VERSION ""

NS_ :

BS_:

BU_: ETH

BO_ 738 VCLEFT_seatStatus2: 8 Vector__XXX
 SG_ VCLEFT_seatStatus2Index M : 0|4@1+ (1,0) [0|0] "" Vector__XXX
 SG_ VCLEFT_2RowSeatReclineActuatorCurrent m6 : 4|12@1- (0.01,0) [0|0] "" Vector__XXX
 SG_ VCLEFT_2RowSeatTrackActuatorCurrent m9 : 4|12@1- (0.01,0) [0|0] "" Vector__XXX
 SG_ VCLEFT_frontOccupancyVoltage m2 : 4|8@1+ (0.02,0) [0|0] "" Vector__XXX
 SG_ VCLEFT_frontSeatHeatCurrent m0 : 4|12@1+ (0.01,0) [0|0] "" Vector__XXX
 SG_ VCLEFT_frontSeatTrackBackrestSwitchVoltage m7 : 4|10@1+ (0.01,0) [0|0] "" Vector__XXX
 SG_ VCLEFT_rearCHeatCurrent m4 : 4|12@1+ (0.01,0) [0|0] "" Vector__XXX
 SG_ VCLEFT_rearLBackHeatCurrent m1 : 4|12@1+ (0.01,0) [0|0] "" Vector__XXX
 SG_ VCLEFT_rearLHeatCurrent m3 : 4|12@1+ (0.01,0) [0|0] "" Vector__XXX
 SG_ VCLEFT_rearRCushionHeatCurrent m5 : 4|12@1+ (0.01,0) [0|0] "" Vector__XXX
 SG_ VCLEFT_trunkFoldFlatLeftSwitchVoltage m8 : 4|10@1+ (0.004887585532746823,0) [0|0] "" Vector__XXX
 SG_ VCLEFT_frontBuckleVoltage m2 : 12|8@1+ (0.02,0) [0|0] "" Vector__XXX
 SG_ VCLEFT_frontSeatLumbarSwitchVoltage m7 : 14|10@1+ (0.01,0) [0|0] "" Vector__XXX
 SG_ VCLEFT_trunkFoldFlatRightSwitchVoltage m8 : 14|10@1+ (0.01,0) [0|0] "" Vector__XXX
 SG_ VCLEFT_2RowSeatReclineActuatorDuty m6 : 16|12@1- (0.1,0) [0|0] "" Vector__XXX
 SG_ VCLEFT_2RowSeatTrackActuatorDuty m9 : 16|12@1- (0.1,0) [0|0] "" Vector__XXX
 SG_ VCLEFT_frontSeatHeatDuty m0 : 16|8@1+ (1,0) [0|0] "" Vector__XXX
 SG_ VCLEFT_rearCHeatDuty m4 : 16|8@1+ (1,0) [0|0] "" Vector__XXX
 SG_ VCLEFT_rearLBackHeatDuty m1 : 16|8@1+ (1,0) [0|0] "" Vector__XXX
 SG_ VCLEFT_rearLHeatDuty m3 : 16|8@1+ (1,0) [0|0] "" Vector__XXX
 SG_ VCLEFT_rearRCushionHeatDuty m5 : 16|8@1+ (1,0) [0|0] "" Vector__XXX
 SG_ VCLEFT_rearLeftBuckleVoltage m2 : 20|8@1+ (0.02,0) [0|0] "" Vector__XXX
 SG_ VCLEFT_frontSeatHeatTmp m0 : 24|12@1- (0.05,0) [0|0] "" Vector__XXX
 SG_ VCLEFT_frontSeatLiftTiltSwitchVoltage m7 : 24|10@1+ (0.01,0) [0|0] "" Vector__XXX
 SG_ VCLEFT_rearCHeatTmp m4 : 24|12@1- (0.05,0) [0|0] "" Vector__XXX
 SG_ VCLEFT_rearLBackHeatTmp m1 : 24|12@1- (0.05,0) [0|0] "" Vector__XXX
 SG_ VCLEFT_rearLHeatTmp m3 : 24|12@1- (0.05,0) [0|0] "" Vector__XXX
 SG_ VCLEFT_rearRCushionHeatTmp m5 : 24|12@1- (0.05,0) [0|0] "" Vector__XXX
 SG_ VCLEFT_2RowSeatCenterActuatorCurrent m6 : 28|12@1- (0.01,0) [0|0] "" Vector__XXX
 SG_ VCLEFT_2RowSeatEasyEntryState m9 : 28|3@1+ (1,0) [0|0] "" Vector__XXX
 SG_ VCLEFT_rearLeftOccupancyVoltage m2 : 28|8@1+ (0.02,0) [0|0] "" Vector__XXX
 SG_ VCLEFT_2RowSeatTrackPositionSwitch m9 : 31|2@1+ (1,0) [0|0] "" Vector__XXX
 SG_ VCLEFT_2RowSeatReclineSwitchVoltage m7 : 34|10@1+ (0.01,0) [0|0] "" Vector__XXX
 SG_ VCLEFT_frontSeatHeatTmpTarget m0 : 36|8@1- (0.5,0) [0|0] "" Vector__XXX
 SG_ VCLEFT_rearCHeatTmpTarget m4 : 36|8@1- (0.5,0) [0|0] "" Vector__XXX
 SG_ VCLEFT_rearCenterOccupancyVoltage m2 : 36|8@1+ (0.02,0) [0|0] "" Vector__XXX
 SG_ VCLEFT_rearLBackHeatTmpTarget m1 : 36|8@1- (0.5,0) [0|0] "" Vector__XXX
 SG_ VCLEFT_rearLHeatTmpTarget m3 : 36|8@1- (0.5,0) [0|0] "" Vector__XXX
 SG_ VCLEFT_rearRCushionHeatTmpTarget m5 : 36|8@1- (0.5,0) [0|0] "" Vector__XXX
 SG_ VCLEFT_2RowSeatCenterActuatorDuty m6 : 40|12@1- (0.1,0) [0|0] "" Vector__XXX
 SG_ VCLEFT_2RowSeatEasyEntrySwitchVoltage m7 : 44|10@1+ (0.01,0) [0|0] "" Vector__XXX
 SG_ VCLEFT_frontSeatHeatInhibited m0 : 44|1@1+ (1,0) [0|0] "" Vector__XXX
 SG_ VCLEFT_rearCHeatInhibited m4 : 44|1@1+ (1,0) [0|0] "" Vector__XXX
 SG_ VCLEFT_rearLBackHeatInhibited m1 : 44|1@1+ (1,0) [0|0] "" Vector__XXX
 SG_ VCLEFT_rearLHeatInhibited m3 : 44|1@1+ (1,0) [0|0] "" Vector__XXX
 SG_ VCLEFT_rearRCushionHeatInhibited m5 : 44|1@1+ (1,0) [0|0] "" Vector__XXX
 SG_ VCLEFT_rearRightOccupancyVoltage m2 : 44|8@1+ (0.02,0) [0|0] "" Vector__XXX
 SG_ VCLEFT_frontSeatHeatPowered m0 : 45|1@1+ (1,0) [0|0] "" Vector__XXX
 SG_ VCLEFT_rearCHeatPowered m4 : 45|1@1+ (1,0) [0|0] "" Vector__XXX
 SG_ VCLEFT_rearLBackHeatPowered m1 : 45|1@1+ (1,0) [0|0] "" Vector__XXX
 SG_ VCLEFT_rearLHeatPowered m3 : 45|1@1+ (1,0) [0|0] "" Vector__XXX
 SG_ VCLEFT_rearRCushionHeatPowered m5 : 45|1@1+ (1,0) [0|0] "" Vector__XXX
 SG_ VCLEFT_rearCenterBuckleVoltage m2 : 52|8@1+ (0.02,0) [0|0] "" Vector__XXX
 SG_ VCLEFT_2RowSeatCenterSwitchVoltage m7 : 54|10@1+ (0.01,0) [0|0] "" Vector__XXX
 SG_ VC_AH_1RowLeftSeatHeatVentHealth m0 : 62|2@1+ (1,0) [0|0] "" Vector__XXX
 SG_ VC_AH_2RowCenterSeatHeatVentHealth m4 : 62|2@1+ (1,0) [0|0] "" Vector__XXX
 SG_ VC_AH_2RowLeftSeatHeatVentHealth m3 : 62|2@1+ (1,0) [0|0] "" Vector__XXX
 SG_ VC_AH_2RowRightSeatHeatVentHealth m5 : 62|2@1+ (1,0) [0|0] "" Vector__XXX

BO_ 739 VCRIGHT_seatStatus2: 8 Vector__XXX
 SG_ VCRIGHT_seatStatus2Index M : 0|4@1+ (1,0) [0|0] "" Vector__XXX
 SG_ VCRIGHT_2RowSeatReclineActuatorCurrent m6 : 4|12@1- (0.01,0) [0|0] "" Vector__XXX
 SG_ VCRIGHT_2RowSeatTrackActuatorCurrent m9 : 4|12@1- (0.01,0) [0|0] "" Vector__XXX
 SG_ VCRIGHT_3RowSeatLeftReclineSwitchVoltage m8 : 4|10@1+ (0.01,0) [0|0] "" Vector__XXX
 SG_ VCRIGHT_frontOccupancyVoltage m4 : 4|10@1+ (0.01,0) [0|0] "" Vector__XXX
 SG_ VCRIGHT_frontSeatHeatCurrent m0 : 4|12@1+ (0.01,0) [0|0] "" Vector__XXX
 SG_ VCRIGHT_frontSeatTrackBackrestSwitchVoltage m7 : 4|10@1+ (0.01,0) [0|0] "" Vector__XXX
 SG_ VCRIGHT_ocsIEEAirbAllwdSts m10 : 4|2@1+ (1,0) [0|0] "" Vector__XXX
 SG_ VCRIGHT_rearCSeatHeatCurrent m2 : 4|12@1+ (0.01,0) [0|0] "" Vector__XXX
 SG_ VCRIGHT_rearLSeatHeatCurrent m1 : 4|12@1+ (0.01,0) [0|0] "" Vector__XXX
 SG_ VCRIGHT_rearRSeatHeatCurrent m3 : 4|12@1+ (0.01,0) [0|0] "" Vector__XXX
 SG_ VCRIGHT_ocsIEEEcuFailr m10 : 6|1@1+ (1,0) [0|0] "" Vector__XXX
 SG_ VCRIGHT_ocsIEEMIA m10 : 7|1@1+ (1,0) [0|0] "" Vector__XXX
 SG_ VCRIGHT_ocsIEEFltResp1 m10 : 8|1@1+ (1,0) [0|0] "" Vector__XXX
 SG_ VCRIGHT_ocsIEEFltResp2 m10 : 9|1@1+ (1,0) [0|0] "" Vector__XXX
 SG_ VCRIGHT_ocsIEEFltResp3 m10 : 10|1@1+ (1,0) [0|0] "" Vector__XXX
 SG_ VCRIGHT_ocsIEEFltResp4 m10 : 11|1@1+ (1,0) [0|0] "" Vector__XXX
 SG_ VCRIGHT_ocsIEEFltResp5 m10 : 12|1@1+ (1,0) [0|0] "" Vector__XXX
 SG_ VCRIGHT_ocsIEEFltResp6 m10 : 13|1@1+ (1,0) [0|0] "" Vector__XXX
 SG_ VCRIGHT_3RowSeatRightReclineSwitchVoltage m8 : 14|10@1+ (0.01,0) [0|0] "" Vector__XXX
 SG_ VCRIGHT_frontBuckleVoltage m4 : 14|10@1+ (0.01,0) [0|0] "" Vector__XXX
 SG_ VCRIGHT_frontSeatLumbarSwitchVoltage m7 : 14|10@1+ (0.01,0) [0|0] "" Vector__XXX
 SG_ VCRIGHT_ocsIEEFltResp7 m10 : 14|1@1+ (1,0) [0|0] "" Vector__XXX
 SG_ VCRIGHT_ocsIEEFltResp8 m10 : 15|1@1+ (1,0) [0|0] "" Vector__XXX
 SG_ VCRIGHT_2RowSeatReclineActuatorDuty m6 : 16|12@1- (0.1,0) [0|0] "" Vector__XXX
 SG_ VCRIGHT_2RowSeatTrackActuatorDuty m9 : 16|12@1- (0.1,0) [0|0] "" Vector__XXX
 SG_ VCRIGHT_frontSeatHeatDuty m0 : 16|8@1+ (1,0) [0|0] "" Vector__XXX
 SG_ VCRIGHT_ocsIEEReqOfPassSeatCal m10 : 16|1@1+ (1,0) [0|0] "" Vector__XXX
 SG_ VCRIGHT_rearCSeatHeatDuty m2 : 16|8@1+ (1,0) [0|0] "" Vector__XXX
 SG_ VCRIGHT_rearLSeatHeatDuty m1 : 16|8@1+ (1,0) [0|0] "" Vector__XXX
 SG_ VCRIGHT_rearRSeatHeatDuty m3 : 16|8@1+ (1,0) [0|0] "" Vector__XXX
 SG_ VCRIGHT_ocsIEEReqOfClrOfFlt m10 : 17|1@1+ (1,0) [0|0] "" Vector__XXX
 SG_ VCRIGHT_ocsIEESnsrPassSeatCalRespSts m10 : 18|2@1+ (1,0) [0|0] "" Vector__XXX
 SG_ VCRIGHT_ocsIEEPowerCurrent m10 : 20|12@1+ (0.001,0) [0|0] "" Vector__XXX
 SG_ VCRIGHT_frontSeatHeatTmp m0 : 24|12@1- (0.05,0) [0|0] "" Vector__XXX
 SG_ VCRIGHT_frontSeatLiftTiltSwitchVoltage m7 : 24|10@1+ (0.01,0) [0|0] "" Vector__XXX
 SG_ VCRIGHT_rearCSeatHeatTmp m2 : 24|12@1- (0.05,0) [0|0] "" Vector__XXX
 SG_ VCRIGHT_rearCenterBuckleVoltage m4 : 24|10@1+ (0.01,0) [0|0] "" Vector__XXX
 SG_ VCRIGHT_rearLSeatHeatTmp m1 : 24|12@1- (0.05,0) [0|0] "" Vector__XXX
 SG_ VCRIGHT_rearRSeatHeatTmp m3 : 24|12@1- (0.05,0) [0|0] "" Vector__XXX
 SG_ VCRIGHT_2RowSeatEasyEntryState m9 : 28|3@1+ (1,0) [0|0] "" Vector__XXX
 SG_ VCRIGHT_3RUSBPortsCurrentAvg m6 : 28|8@1+ (0.01,0) [0|0] "" Vector__XXX
 SG_ VCRIGHT_2RowSeatTrackPositionSwitch m9 : 31|2@1+ (1,0) [0|0] "" Vector__XXX
 SG_ VCRIGHT_ocsIEEState m10 : 32|3@1+ (1,0) [0|0] "" Vector__XXX
 SG_ VCRIGHT_2RowSeatReclineSwitchVoltage m7 : 34|10@1+ (0.01,0) [0|0] "" Vector__XXX
 SG_ VCRIGHT_rearRightBuckleVoltage m4 : 34|10@1+ (0.01,0) [0|0] "" Vector__XXX
 SG_ VCRIGHT_frontSeatHeatTmpTarget m0 : 36|8@1- (0.5,0) [0|0] "" Vector__XXX
 SG_ VCRIGHT_rearCSeatHeatTmpTarget m2 : 36|8@1- (0.5,0) [0|0] "" Vector__XXX
 SG_ VCRIGHT_rearLSeatHeatTmpTarget m1 : 36|8@1- (0.5,0) [0|0] "" Vector__XXX
 SG_ VCRIGHT_rearRSeatHeatTmpTarget m3 : 36|8@1- (0.5,0) [0|0] "" Vector__XXX
 SG_ VCRIGHT_2RowSeatEasyEntrySwitchVoltage m7 : 44|10@1+ (0.01,0) [0|0] "" Vector__XXX
 SG_ VCRIGHT_frontSeatHeatInhibited m0 : 44|1@1+ (1,0) [0|0] "" Vector__XXX
 SG_ VCRIGHT_rearCSeatHeatInhibited m2 : 44|1@1+ (1,0) [0|0] "" Vector__XXX
 SG_ VCRIGHT_rearLSeatHeatInhibited m1 : 44|1@1+ (1,0) [0|0] "" Vector__XXX
 SG_ VCRIGHT_rearRSeatHeatInhibited m3 : 44|1@1+ (1,0) [0|0] "" Vector__XXX
 SG_ VCRIGHT_frontSeatHeatPowered m0 : 45|1@1+ (1,0) [0|0] "" Vector__XXX
 SG_ VCRIGHT_rearCSeatHeatPowered m2 : 45|1@1+ (1,0) [0|0] "" Vector__XXX
 SG_ VCRIGHT_rearLSeatHeatPowered m1 : 45|1@1+ (1,0) [0|0] "" Vector__XXX
 SG_ VCRIGHT_rearRSeatHeatPowered m3 : 45|1@1+ (1,0) [0|0] "" Vector__XXX
 SG_ VCRIGHT_occupantClassificationHoldState m4 : 46|2@1+ (1,0) [0|0] "" Vector__XXX
 SG_ VC_AH_1RowRightSeatHeatVentHealth m0 : 54|2@1+ (1,0) [0|0] "" Vector__XXX

BO_ 740 PCS2_logging: 8 Vector__XXX
 SG_ PCS2_logMessageSelect M : 0|8@1+ (1,0) [0|0] "" Vector__XXX
 SG_ PCS2_10V0RailSense m24 : 8|12@1+ (0.01,0) [0|0] "" Vector__XXX
 SG_ PCS2_13V5RailSense m29 : 8|12@1+ (0.01,0) [0|0] "" Vector__XXX
 SG_ PCS2_18V0RailSense m16 : 8|12@1+ (0.01,0) [0|0] "" Vector__XXX
 SG_ PCS2_1V6RailSense m26 : 8|12@1+ (0.01,0) [0|0] "" Vector__XXX
 SG_ PCS2_2V5Ref_V m30 : 8|12@1+ (0.01,0) [0|0] "" Vector__XXX
 SG_ PCS2_48V0RailSense m27 : 8|13@1+ (0.01,0) [0|0] "" Vector__XXX
 SG_ PCS2_48V0_18V0_CurrentSense m28 : 8|13@1- (0.01,0) [0|0] "" Vector__XXX
 SG_ PCS2_4V5RailSense m25 : 8|12@1+ (0.01,0) [0|0] "" Vector__XXX
 SG_ PCS2_FC_VSense m31 : 8|12@1- (1,0) [0|0] "" Vector__XXX
 SG_ PCS2_L1NAvailableForCharging m140 : 8|1@1+ (1,0) [0|0] "" Vector__XXX
 SG_ PCS2_acChargeLifetimekVAh m151 : 8|24@1+ (0.01,0) [0|0] "" Vector__XXX
 SG_ PCS2_acFrequencyL1L2 m133 : 8|13@1+ (0.01,0) [0|0] "" Vector__XXX
 SG_ PCS2_acFrequencyL1N m132 : 8|13@1+ (0.01,0) [0|0] "" Vector__XXX
 SG_ PCS2_acL1Arms m130 : 8|12@1+ (0.1,0) [0|0] "" Vector__XXX
 SG_ PCS2_acL1ChassisVrms m138 : 8|9@1+ (1,0) [0|0] "" Vector__XXX
 SG_ PCS2_acL1ContinuousCurrentLimit m149 : 8|10@1+ (0.1,0) [0|0] "" Vector__XXX
 SG_ PCS2_acL1CurrentLimitI2T m148 : 8|9@1+ (1,0) [0|0] "" Vector__XXX
 SG_ PCS2_acL1GeneratedHeatI2TCpLimit m159 : 8|10@1+ (0.1,0) [0|0] "" Vector__XXX
 SG_ PCS2_acL1GeneratedHeatI2THwLimit m150 : 8|10@1+ (0.1,0) [0|0] "" Vector__XXX
 SG_ PCS2_acL1L2Vrms m129 : 8|10@1+ (0.5,0) [0|0] "" Vector__XXX
 SG_ PCS2_acL1NVrms m128 : 8|10@1+ (0.5,0) [0|0] "" Vector__XXX
 SG_ PCS2_acL1TransientCurrentLimit m147 : 8|10@1+ (0.1,0) [0|0] "" Vector__XXX
 SG_ PCS2_acL2NPreRelayVrms m157 : 8|10@1+ (0.5,0) [0|0] "" Vector__XXX
 SG_ PCS2_aggregatedChargingCurrentLimit m139 : 8|10@1+ (0.1,0) [0|0] "" Vector__XXX
 SG_ PCS2_cabinAndBedL1L2LifetimekVAh m153 : 8|24@1+ (0.01,0) [0|0] "" Vector__XXX
 SG_ PCS2_cabinOnlyL2L3LifetimekVAh m152 : 8|24@1+ (0.01,0) [0|0] "" Vector__XXX
 SG_ PCS2_chgMainStateMachineState m135 : 8|4@1+ (1,0) [0|0] "" Vector__XXX
 SG_ PCS2_cpu0IsrUtilizationPercentageMax10s m23 : 8|8@1+ (1,0) [0|0] "" Vector__XXX
 SG_ PCS2_cpu1IsrUtilizationPercentageMax10s m95 : 8|8@1+ (1,0) [0|0] "" Vector__XXX
 SG_ PCS2_cpu2IsrUtilizationPercentageMax10s m158 : 8|8@1+ (1,0) [0|0] "" Vector__XXX
 SG_ PCS2_cpu3IsrUtilizationPercentageMax10s m206 : 8|8@1+ (1,0) [0|0] "" Vector__XXX
 SG_ PCS2_cycloAC_L1L2PeakV m160 : 8|11@1+ (0.5,0) [0|0] "" Vector__XXX
 SG_ PCS2_cycloAC_L1PeakCurrent m192 : 8|9@1+ (1,0) [0|0] "" Vector__XXX
 SG_ PCS2_cycloAC_chassisNPeakV m136 : 8|11@1+ (0.5,0) [0|0] "" Vector__XXX
 SG_ PCS2_cycloACmdSwitchingFreq_max_1s m156 : 8|14@1+ (0.1,150) [0|0] "" Vector__XXX
 SG_ PCS2_cycloASurgeCombinedDeratingFactor m143 : 8|7@1+ (0.01,0) [0|0] "" Vector__XXX
 SG_ PCS2_cycloATankLeakFreq m137 : 8|12@1+ (0.1,0) [0|0] "" Vector__XXX
 SG_ PCS2_cycloA_L_tank m142 : 8|11@1+ (0.1,0) [0|0] "" Vector__XXX
 SG_ PCS2_cycloA_tank_zcd_event_pu_max_1s m155 : 8|9@1- (0.01,0) [0|0] "" Vector__XXX
 SG_ PCS2_cycloBCmdSwitchingFreq_max_1s m203 : 8|14@1+ (0.1,150) [0|0] "" Vector__XXX
 SG_ PCS2_cycloBSurgeCombinedDeratingFactor m195 : 8|7@1+ (0.01,0) [0|0] "" Vector__XXX
 SG_ PCS2_cycloBTankLeakFreq m193 : 8|12@1+ (0.1,0) [0|0] "" Vector__XXX
 SG_ PCS2_cycloB_L_tank m194 : 8|11@1+ (0.1,0) [0|0] "" Vector__XXX
 SG_ PCS2_cycloB_tank_zcd_event_pu_max_1s m202 : 8|9@1- (0.01,0) [0|0] "" Vector__XXX
 SG_ PCS2_cyclo_A_hv_device_temp m144 : 8|11@1+ (0.1,0) [0|0] "" Vector__XXX
 SG_ PCS2_cyclo_A_hv_device_temp_max m145 : 8|11@1+ (0.1,0) [0|0] "" Vector__XXX
 SG_ PCS2_cyclo_A_i_tank_loss m146 : 8|17@1+ (1000000000000,0) [0|0] "" Vector__XXX
 SG_ PCS2_cyclo_B_hv_device_temp m196 : 8|11@1+ (0.1,0) [0|0] "" Vector__XXX
 SG_ PCS2_cyclo_B_hv_device_temp_max m197 : 8|11@1+ (0.1,0) [0|0] "" Vector__XXX
 SG_ PCS2_cyclo_B_i_tank_loss m198 : 8|17@1+ (1000000000000,0) [0|0] "" Vector__XXX
 SG_ PCS2_dcOffsetL1NVoltage m204 : 8|9@1- (4,0) [0|0] "" Vector__XXX
 SG_ PCS2_dcOffsetL2NPreRelayVoltage m205 : 8|9@1- (4,0) [0|0] "" Vector__XXX
 SG_ PCS2_dcacA_ac1Temp m86 : 8|11@1- (0.15,70.05) [0|0] "" Vector__XXX
 SG_ PCS2_dcacA_ac1TempMax_10s m91 : 8|11@1- (0.15,70.05) [0|0] "" Vector__XXX
 SG_ PCS2_dcacA_ac1TempMin_10s m90 : 8|11@1- (0.15,70.05) [0|0] "" Vector__XXX
 SG_ PCS2_dcacA_transformerTemp m89 : 8|11@1- (0.15,70.05) [0|0] "" Vector__XXX
 SG_ PCS2_dcacA_transformerTempMax_10s m82 : 8|11@1- (0.15,70.05) [0|0] "" Vector__XXX
 SG_ PCS2_dcacA_transformerTempMin_10s m94 : 8|11@1- (0.15,70.05) [0|0] "" Vector__XXX
 SG_ PCS2_dcacB_ac1Temp m87 : 8|11@1- (0.15,70.05) [0|0] "" Vector__XXX
 SG_ PCS2_dcacB_ac1TempMax_10s m93 : 8|11@1- (0.15,70.05) [0|0] "" Vector__XXX
 SG_ PCS2_dcacB_ac1TempMin_10s m92 : 8|11@1- (0.15,70.05) [0|0] "" Vector__XXX
 SG_ PCS2_dcacHvBusVoltage m134 : 8|14@1+ (0.1,0) [0|0] "" Vector__XXX
 SG_ PCS2_dcdcACmdSwitchingFreq_max_1s m21 : 8|14@1+ (0.1,150) [0|0] "" Vector__XXX
 SG_ PCS2_dcdcAHalfBusTopVoltageMin_10s m7 : 8|10@1+ (1,0) [0|0] "" Vector__XXX
 SG_ PCS2_dcdcAHvCurrentCommand m2 : 8|13@1- (0.01,0) [0|0] "" Vector__XXX
 SG_ PCS2_dcdcAHvVoltage m0 : 8|14@1+ (0.1,0) [0|0] "" Vector__XXX
 SG_ PCS2_dcdcAHvVoltageMin_10s m5 : 8|14@1+ (0.1,0) [0|0] "" Vector__XXX
 SG_ PCS2_dcdcALifetimekWh m10 : 8|24@1+ (0.01,0) [0|0] "" Vector__XXX
 SG_ PCS2_dcdcALvMosfetModelTemp m11 : 8|9@1- (1,106) [0|0] "" Vector__XXX
 SG_ PCS2_dcdcALvVoltageTarget m9 : 8|13@1+ (0.01,0) [0|0] "" Vector__XXX
 SG_ PCS2_dcdcAPWMBlockedByArbitration m19 : 8|1@1+ (1,0) [0|0] "" Vector__XXX
 SG_ PCS2_dcdcAStageManagerRetryCount m17 : 8|3@1+ (1,0) [0|0] "" Vector__XXX
 SG_ PCS2_dcdcATankLeakFreq m8 : 8|12@1+ (0.1,0) [0|0] "" Vector__XXX
 SG_ PCS2_dcdcA_L_tank m6 : 8|11@1+ (0.1,0) [0|0] "" Vector__XXX
 SG_ PCS2_dcdcA_lv2Temp m88 : 8|11@1- (0.15,70.05) [0|0] "" Vector__XXX
 SG_ PCS2_dcdcA_lv2TempMax_10s m80 : 8|11@1- (0.15,70.05) [0|0] "" Vector__XXX
 SG_ PCS2_dcdcA_lv2TempMin_10s m79 : 8|11@1- (0.15,70.05) [0|0] "" Vector__XXX
 SG_ PCS2_dcdcA_tank_zcd_event_pu_max_1s m20 : 8|9@1- (0.01,0) [0|0] "" Vector__XXX
 SG_ PCS2_dcdcBCmdSwitchingFreq_max_1s m78 : 8|14@1+ (0.1,150) [0|0] "" Vector__XXX
 SG_ PCS2_dcdcBHalfBusTopVoltageMin_10s m68 : 8|10@1+ (1,0) [0|0] "" Vector__XXX
 SG_ PCS2_dcdcBHvCurrentCommand m65 : 8|13@1- (0.01,0) [0|0] "" Vector__XXX
 SG_ PCS2_dcdcBHvMosfetModelTemp m96 : 8|9@1- (1,106) [0|0] "" Vector__XXX
 SG_ PCS2_dcdcBHvVoltage m64 : 8|14@1+ (0.1,0) [0|0] "" Vector__XXX
 SG_ PCS2_dcdcBHvVoltageMin_10s m66 : 8|14@1+ (0.1,0) [0|0] "" Vector__XXX
 SG_ PCS2_dcdcBLifetimekWh m71 : 8|24@1+ (0.01,0) [0|0] "" Vector__XXX
 SG_ PCS2_dcdcBLvMosfetModelTemp m72 : 8|9@1- (1,106) [0|0] "" Vector__XXX
 SG_ PCS2_dcdcBLvVoltageTarget m70 : 8|13@1+ (0.01,0) [0|0] "" Vector__XXX
 SG_ PCS2_dcdcBPWMBlockedByArbitration m76 : 8|1@1+ (1,0) [0|0] "" Vector__XXX
 SG_ PCS2_dcdcBStageManagerRetryCount m74 : 8|3@1+ (1,0) [0|0] "" Vector__XXX
 SG_ PCS2_dcdcBTankLeakFreq m69 : 8|12@1+ (0.1,0) [0|0] "" Vector__XXX
 SG_ PCS2_dcdcB_L_tank m67 : 8|11@1+ (0.1,0) [0|0] "" Vector__XXX
 SG_ PCS2_dcdcB_tank_zcd_event_pu_max_1s m77 : 8|9@1- (0.01,0) [0|0] "" Vector__XXX
 SG_ PCS2_dcdcGdpsHealthCheckStatus m22 : 8|2@1+ (1,0) [0|0] "" Vector__XXX
 SG_ PCS2_dcdcLvBusVoltage m83 : 8|13@1+ (0.01,0) [0|0] "" Vector__XXX
 SG_ PCS2_dcdcLvBusVoltageFiltered m3 : 8|13@1+ (0.01,0) [0|0] "" Vector__XXX
 SG_ PCS2_dcdcUsingInternalDefLvTarget m1 : 8|1@1+ (1,0) [0|0] "" Vector__XXX
 SG_ PCS2_dcdc_hvTemp m81 : 8|11@1- (0.15,70.05) [0|0] "" Vector__XXX
 SG_ PCS2_detectedInternalPhaseConfig m131 : 8|3@1+ (1,0) [0|0] "" Vector__XXX
 SG_ PCS2_hvBusEstimatedCapacitance m73 : 8|10@1+ (10,0) [0|0] "" Vector__XXX
 SG_ PCS2_hwZcdFaultRateMax60s m97 : 8|16@1+ (0.001,0) [0|0] "" Vector__XXX
 SG_ PCS2_ipcCpu0ToCpu1MaxSuccessiveLockGrabFails m18 : 8|3@1+ (1,0) [0|0] "" Vector__XXX
 SG_ PCS2_ipcCpu1ToCpu0MaxSuccessiveLockGrabFails m75 : 8|3@1+ (1,0) [0|0] "" Vector__XXX
 SG_ PCS2_ipcCpu2ToCpu0MaxSuccessiveLockGrabFails m154 : 8|3@1+ (1,0) [0|0] "" Vector__XXX
 SG_ PCS2_ipcCpu3ToCpu0MaxSuccessiveLockGrabFails m200 : 8|3@1+ (1,0) [0|0] "" Vector__XXX
 SG_ PCS2_lite_ambientTemp m84 : 8|11@1- (0.15,70.05) [0|0] "" Vector__XXX
 SG_ PCS2_lite_boost_duty m32 : 8|7@1+ (0.01,0) [0|0] "" Vector__XXX
 SG_ PCS2_lite_dcdc_LV_A_Temp m85 : 8|11@1- (0.15,70.05) [0|0] "" Vector__XXX
 SG_ PCS2_lite_lvBiasRailSense m33 : 8|12@1+ (0.01,0) [0|0] "" Vector__XXX
 SG_ PCS2_llcControllerFreqMHz m4 : 8|8@1+ (0.01,0) [0|0] "" Vector__XXX
 SG_ PCS2_mfgFuncTestCalIterativeState m14 : 8|4@1+ (1,0) [0|0] "" Vector__XXX
 SG_ PCS2_mfgFuncTestIOXWriteFailed m15 : 8|10@1+ (1,0) [0|0] "" Vector__XXX
 SG_ PCS2_mfgFuncTestState m12 : 8|4@1+ (1,0) [0|0] "" Vector__XXX
 SG_ PCS2_mfg_can_injection_msg_index m13 : 8|3@1+ (1,0) [0|0] "" Vector__XXX
 SG_ PCS2_microgridHeartbeatDetected m201 : 8|1@1+ (1,0) [0|0] "" Vector__XXX
 SG_ PCS2_phase_diff_L1N_L2N m141 : 8|8@1+ (1,0) [0|0] "" Vector__XXX
 SG_ PCS2_vcrEfuseState m34 : 8|1@1+ (1,0) [0|0] "" Vector__XXX
 SG_ PCS2_L2NAvailableForCharging m140 : 9|1@1+ (1,0) [0|0] "" Vector__XXX
 SG_ PCS2_dcdcAStateMachineState m1 : 9|3@1+ (1,0) [0|0] "" Vector__XXX
 SG_ PCS2_hvcEfuseState m34 : 9|1@1+ (1,0) [0|0] "" Vector__XXX
 SG_ PCS2_L3NAvailableForCharging m140 : 10|1@1+ (1,0) [0|0] "" Vector__XXX
 SG_ PCS2_cycloAGdpsHealthCheckStatus m22 : 10|2@1+ (1,0) [0|0] "" Vector__XXX
 SG_ PCS2_L1L2AvailableForCharging m140 : 11|1@1+ (1,0) [0|0] "" Vector__XXX
 SG_ PCS2_dcdcASmLvRegulationRetryCnt m17 : 11|4@1+ (1,0) [0|0] "" Vector__XXX
 SG_ PCS2_dcdcBSmLvRegulationRetryCnt m74 : 11|4@1+ (1,0) [0|0] "" Vector__XXX
 SG_ PCS2_ipcCpu0ToCpu2MaxSuccessiveLockGrabFails m18 : 11|3@1+ (1,0) [0|0] "" Vector__XXX
 SG_ PCS2_ipcCpu1ToCpu2MaxSuccessiveLockGrabFails m75 : 11|3@1+ (1,0) [0|0] "" Vector__XXX
 SG_ PCS2_ipcCpu2ToCpu1MaxSuccessiveLockGrabFails m154 : 11|3@1+ (1,0) [0|0] "" Vector__XXX
 SG_ PCS2_ipcCpu3ToCpu1MaxSuccessiveLockGrabFails m200 : 11|3@1+ (1,0) [0|0] "" Vector__XXX
 SG_ PCS2_latchedInternalPhaseConfig m131 : 11|3@1+ (1,0) [0|0] "" Vector__XXX
 SG_ PCS2_mfgFuncTestImpedanceMeasEnable m13 : 11|1@1+ (1,0) [0|0] "" Vector__XXX
 SG_ PCS2_L1L3AvailableForCharging m140 : 12|1@1+ (1,0) [0|0] "" Vector__XXX
 SG_ PCS2_cycloBGdpsHealthCheckStatus m22 : 12|2@1+ (1,0) [0|0] "" Vector__XXX
 SG_ PCS2_dcdcBStateMachineState m1 : 12|3@1+ (1,0) [0|0] "" Vector__XXX
 SG_ PCS2_gridFormStateMachineState m135 : 12|3@1+ (1,0) [0|0] "" Vector__XXX
 SG_ PCS2_mfgFuncTestBlockID m12 : 12|6@1+ (1,0) [0|0] "" Vector__XXX
 SG_ PCS2_mfgFuncTestCalIterativeCtrlID m14 : 12|1@1+ (1,0) [0|0] "" Vector__XXX
 SG_ PCS2_mfgFuncTestCalPiCtrlEnable m13 : 12|1@1+ (1,0) [0|0] "" Vector__XXX
 SG_ PCS2_L2L3AvailableForCharging m140 : 13|1@1+ (1,0) [0|0] "" Vector__XXX
 SG_ PCS2_L1NExpectedWhileCharging m140 : 14|1@1+ (1,0) [0|0] "" Vector__XXX
 SG_ PCS2_cycloAMosfetHealthCheckStatus m22 : 14|2@1+ (1,0) [0|0] "" Vector__XXX
 SG_ PCS2_cycloNumWire m131 : 14|2@1+ (1,0) [0|0] "" Vector__XXX
 SG_ PCS2_L2NExpectedWhileCharging m140 : 15|1@1+ (1,0) [0|0] "" Vector__XXX
 SG_ PCS2_L3NExpectedWhileCharging m140 : 16|1@1+ (1,0) [0|0] "" Vector__XXX
 SG_ PCS2_cpu0Task5kHzUtilizationPercentageMax10s m23 : 16|8@1+ (1,0) [0|0] "" Vector__XXX
 SG_ PCS2_cpu1Task5kHzUtilizationPercentageMax10s m95 : 16|8@1+ (1,0) [0|0] "" Vector__XXX
 SG_ PCS2_cpu2Task5kHzUtilizationPercentageMax10s m158 : 16|8@1+ (1,0) [0|0] "" Vector__XXX
 SG_ PCS2_cpu3Task5kHzUtilizationPercentageMax10s m206 : 16|8@1+ (1,0) [0|0] "" Vector__XXX
 SG_ PCS2_cycloAStageStateMachineState m135 : 16|3@1+ (1,0) [0|0] "" Vector__XXX
 SG_ PCS2_cycloATxTempDeratingFactor m143 : 16|7@1+ (0.01,0) [0|0] "" Vector__XXX
 SG_ PCS2_cycloBMosfetHealthCheckStatus m22 : 16|2@1+ (1,0) [0|0] "" Vector__XXX
 SG_ PCS2_cycloBTxTempDeratingFactor m195 : 16|7@1+ (0.01,0) [0|0] "" Vector__XXX
 SG_ PCS2_dcdcADeltaEnergy m19 : 16|16@1+ (1,0) [0|0] "" Vector__XXX
 SG_ PCS2_dcdcASmPrechargeRetryCnt m17 : 16|4@1+ (1,0) [0|0] "" Vector__XXX
 SG_ PCS2_dcdcAStageModeRequest m1 : 16|2@1+ (1,0) [0|0] "" Vector__XXX
 SG_ PCS2_dcdcBDeltaEnergy m76 : 16|16@1+ (1,0) [0|0] "" Vector__XXX
 SG_ PCS2_dcdcBSmPrechargeRetryCnt m74 : 16|4@1+ (1,0) [0|0] "" Vector__XXX
 SG_ PCS2_gridFrequency m131 : 16|13@1+ (0.01,0) [0|0] "" Vector__XXX
 SG_ PCS2_ipcCpu0ToCpu3MaxSuccessiveLockGrabFails m18 : 16|3@1+ (1,0) [0|0] "" Vector__XXX
 SG_ PCS2_ipcCpu1ToCpu3MaxSuccessiveLockGrabFails m75 : 16|3@1+ (1,0) [0|0] "" Vector__XXX
 SG_ PCS2_ipcCpu2ToCpu3MaxSuccessiveLockGrabFails m154 : 16|3@1+ (1,0) [0|0] "" Vector__XXX
 SG_ PCS2_ipcCpu3ToCpu2MaxSuccessiveLockGrabFails m200 : 16|3@1+ (1,0) [0|0] "" Vector__XXX
 SG_ PCS2_lite_boost_duty_min_10s m32 : 16|7@1+ (0.01,0) [0|0] "" Vector__XXX
 SG_ PCS2_llcControllerFreqMHzMax10s m4 : 16|8@1+ (0.01,0) [0|0] "" Vector__XXX
 SG_ PCS2_mfgFuncTestCalPiReference m13 : 16|5@1+ (1,0) [0|0] "" Vector__XXX
 SG_ PCS2_mfgFuncTestResult2 m14 : 16|14@1- (0.01,0) [0|0] "" Vector__XXX
 SG_ PCS2_microgridHeartbeat1hzRms m201 : 16|8@1+ (0.001,0) [0|0] "" Vector__XXX
 SG_ PCS2_phase_diff_L1N_L3N m141 : 16|8@1+ (1,0) [0|0] "" Vector__XXX
 SG_ PCS2_L1L2ExpectedWhileCharging m140 : 17|1@1+ (1,0) [0|0] "" Vector__XXX
 SG_ PCS2_acL2ChassisVrms m138 : 17|9@1+ (1,0) [0|0] "" Vector__XXX
 SG_ PCS2_acL2CurrentLimitI2T m148 : 17|9@1+ (1,0) [0|0] "" Vector__XXX
 SG_ PCS2_cycloAC_L2PeakCurrent m192 : 17|9@1+ (1,0) [0|0] "" Vector__XXX
 SG_ PCS2_cycloA_tank_zcd_event_pu_min_1s m155 : 17|9@1- (0.01,0) [0|0] "" Vector__XXX
 SG_ PCS2_cycloB_tank_zcd_event_pu_min_1s m202 : 17|9@1- (0.01,0) [0|0] "" Vector__XXX
 SG_ PCS2_dcOffsetL2NVoltage m204 : 17|9@1- (4,0) [0|0] "" Vector__XXX
 SG_ PCS2_dcOffsetL3NPreRelayVoltage m205 : 17|9@1- (4,0) [0|0] "" Vector__XXX
 SG_ PCS2_dcdcALvMosfetModelHvCurrentLimit m11 : 17|14@1- (0.01,0) [0|0] "" Vector__XXX
 SG_ PCS2_dcdcA_tank_zcd_event_pu_min_1s m20 : 17|9@1- (0.01,0) [0|0] "" Vector__XXX
 SG_ PCS2_dcdcBHvMosfetModelHvCurrentLimit m96 : 17|14@1- (0.01,0) [0|0] "" Vector__XXX
 SG_ PCS2_dcdcBLvMosfetModelHvCurrentLimit m72 : 17|14@1- (0.01,0) [0|0] "" Vector__XXX
 SG_ PCS2_dcdcB_tank_zcd_event_pu_min_1s m77 : 17|9@1- (0.01,0) [0|0] "" Vector__XXX
 SG_ PCS2_L1L3ExpectedWhileCharging m140 : 18|1@1+ (1,0) [0|0] "" Vector__XXX
 SG_ PCS2_acL1L3Vrms m129 : 18|10@1+ (0.5,0) [0|0] "" Vector__XXX
 SG_ PCS2_acL2ContinuousCurrentLimit m149 : 18|10@1+ (0.1,0) [0|0] "" Vector__XXX
 SG_ PCS2_acL2GeneratedHeatI2TCpLimit m159 : 18|10@1+ (0.1,0) [0|0] "" Vector__XXX
 SG_ PCS2_acL2GeneratedHeatI2THwLimit m150 : 18|10@1+ (0.1,0) [0|0] "" Vector__XXX
 SG_ PCS2_acL2NVrms m128 : 18|10@1+ (0.5,0) [0|0] "" Vector__XXX
 SG_ PCS2_acL2TransientCurrentLimit m147 : 18|10@1+ (0.1,0) [0|0] "" Vector__XXX
 SG_ PCS2_acL3NPreRelayVrms m157 : 18|10@1+ (0.5,0) [0|0] "" Vector__XXX
 SG_ PCS2_aggregatedWithUserChargingCurrentLimit m139 : 18|10@1+ (0.1,0) [0|0] "" Vector__XXX
 SG_ PCS2_cycloXcapHealthCheckStatus m22 : 18|2@1+ (1,0) [0|0] "" Vector__XXX
 SG_ PCS2_dcdcAHalfBusTopVoltageMax_10s m7 : 18|10@1+ (1,0) [0|0] "" Vector__XXX
 SG_ PCS2_dcdcBHalfBusTopVoltageMax_10s m68 : 18|10@1+ (1,0) [0|0] "" Vector__XXX
 SG_ PCS2_dcdcBStageModeRequest m1 : 18|2@1+ (1,0) [0|0] "" Vector__XXX
 SG_ PCS2_mfgFuncTestID m12 : 18|10@1+ (1,0) [0|0] "" Vector__XXX
 SG_ PCS2_mfgFuncTestIOXWrRetryHWM m15 : 18|10@1+ (1,0) [0|0] "" Vector__XXX
 SG_ PCS2_L2L3ExpectedWhileCharging m140 : 19|1@1+ (1,0) [0|0] "" Vector__XXX
 SG_ PCS2_cycloAC_L1L3PeakV m160 : 19|11@1+ (0.5,0) [0|0] "" Vector__XXX
 SG_ PCS2_cycloAC_L1NPeakV m136 : 19|11@1+ (0.5,0) [0|0] "" Vector__XXX
 SG_ PCS2_cycloA_L_magnetizing m142 : 19|11@1+ (0.1,0) [0|0] "" Vector__XXX
 SG_ PCS2_cycloBStageStateMachineState m135 : 19|3@1+ (1,0) [0|0] "" Vector__XXX
 SG_ PCS2_cycloB_L_magnetizing m194 : 19|11@1+ (0.1,0) [0|0] "" Vector__XXX
 SG_ PCS2_cyclo_A_l1_device_temp m144 : 19|11@1+ (0.1,0) [0|0] "" Vector__XXX
 SG_ PCS2_cyclo_A_l1_device_temp_max m145 : 19|11@1+ (0.1,0) [0|0] "" Vector__XXX
 SG_ PCS2_cyclo_B_l1_device_temp m196 : 19|11@1+ (0.1,0) [0|0] "" Vector__XXX
 SG_ PCS2_cyclo_B_l1_device_temp_max m197 : 19|11@1+ (0.1,0) [0|0] "" Vector__XXX
 SG_ PCS2_dcacA_ac1TempIrrational m86 : 19|1@1+ (1,0) [0|0] "" Vector__XXX
 SG_ PCS2_dcacA_ac2TempMax_10s m91 : 19|11@1- (0.15,70.05) [0|0] "" Vector__XXX
 SG_ PCS2_dcacA_ac2TempMin_10s m90 : 19|11@1- (0.15,70.05) [0|0] "" Vector__XXX
 SG_ PCS2_dcacB_ac1TempIrrational m87 : 19|1@1+ (1,0) [0|0] "" Vector__XXX
 SG_ PCS2_dcacB_ac2TempMax_10s m93 : 19|11@1- (0.15,70.05) [0|0] "" Vector__XXX
 SG_ PCS2_dcacB_ac2TempMin_10s m92 : 19|11@1- (0.15,70.05) [0|0] "" Vector__XXX
 SG_ PCS2_dcacB_transformerTemp m89 : 19|11@1- (0.15,70.05) [0|0] "" Vector__XXX
 SG_ PCS2_dcacB_transformerTempMax_10s m82 : 19|11@1- (0.15,70.05) [0|0] "" Vector__XXX
 SG_ PCS2_dcacB_transformerTempMin_10s m94 : 19|11@1- (0.15,70.05) [0|0] "" Vector__XXX
 SG_ PCS2_dcdcA_L_magnetizing m6 : 19|11@1+ (0.1,0) [0|0] "" Vector__XXX
 SG_ PCS2_dcdcA_lv2TempIrrational m88 : 19|1@1+ (1,0) [0|0] "" Vector__XXX
 SG_ PCS2_dcdcB_L_magnetizing m67 : 19|11@1+ (0.1,0) [0|0] "" Vector__XXX
 SG_ PCS2_dcdcB_lv2TempMax_10s m80 : 19|11@1- (0.15,70.05) [0|0] "" Vector__XXX
 SG_ PCS2_dcdcB_lv2TempMin_10s m79 : 19|11@1- (0.15,70.05) [0|0] "" Vector__XXX
 SG_ PCS2_dcdc_hvTempIrrational m81 : 19|1@1+ (1,0) [0|0] "" Vector__XXX
 SG_ PCS2_ipcCpu0ToCpu1TotalPeriodicLockGrabFails m18 : 19|9@1+ (1,0) [0|0] "" Vector__XXX
 SG_ PCS2_ipcCpu1ToCpu0TotalPeriodicLockGrabFails m75 : 19|9@1+ (1,0) [0|0] "" Vector__XXX
 SG_ PCS2_ipcCpu2ToCpu0TotalPeriodicLockGrabFails m154 : 19|9@1+ (1,0) [0|0] "" Vector__XXX
 SG_ PCS2_ipcCpu3ToCpu0TotalPeriodicLockGrabFails m200 : 19|9@1+ (1,0) [0|0] "" Vector__XXX
 SG_ PCS2_lite_coolantOutTemp m84 : 19|11@1- (0.15,70.05) [0|0] "" Vector__XXX
 SG_ PCS2_lite_dcdc_LV_B_Temp m85 : 19|11@1- (0.15,70.05) [0|0] "" Vector__XXX
 SG_ PCS2_10V0RailSenseMax10s m24 : 20|12@1+ (0.01,0) [0|0] "" Vector__XXX
 SG_ PCS2_13V5RailSenseMax10s m29 : 20|12@1+ (0.01,0) [0|0] "" Vector__XXX
 SG_ PCS2_18V0RailSenseMax10s m16 : 20|12@1+ (0.01,0) [0|0] "" Vector__XXX
 SG_ PCS2_1V6RailSenseMax10s m26 : 20|12@1+ (0.01,0) [0|0] "" Vector__XXX
 SG_ PCS2_4V5RailSenseMax10s m25 : 20|12@1+ (0.01,0) [0|0] "" Vector__XXX
 SG_ PCS2_FC_P_VSense m31 : 20|12@1- (1,0) [0|0] "" Vector__XXX
 SG_ PCS2_L1NLatchedExpectedWhileCharging m140 : 20|1@1+ (1,0) [0|0] "" Vector__XXX
 SG_ PCS2_acL2Arms m130 : 20|12@1+ (0.1,0) [0|0] "" Vector__XXX
 SG_ PCS2_cycloATankLeakInductance m137 : 20|12@1+ (0.1,0) [0|0] "" Vector__XXX
 SG_ PCS2_cycloBTankLeakInductance m193 : 20|12@1+ (0.1,0) [0|0] "" Vector__XXX
 SG_ PCS2_dcacA_ac2Temp m86 : 20|11@1- (0.15,70.05) [0|0] "" Vector__XXX
 SG_ PCS2_dcacB_ac2Temp m87 : 20|11@1- (0.15,70.05) [0|0] "" Vector__XXX
 SG_ PCS2_dcdcASmDischargeRetryCnt m17 : 20|4@1+ (1,0) [0|0] "" Vector__XXX
 SG_ PCS2_dcdcATankLeakInductance m8 : 20|12@1+ (0.1,0) [0|0] "" Vector__XXX
 SG_ PCS2_dcdcBSmDischargeRetryCnt m74 : 20|4@1+ (1,0) [0|0] "" Vector__XXX
 SG_ PCS2_dcdcBTankLeakInductance m69 : 20|12@1+ (0.1,0) [0|0] "" Vector__XXX
 SG_ PCS2_dcdcB_lv2Temp m88 : 20|11@1- (0.15,70.05) [0|0] "" Vector__XXX
 SG_ PCS2_dcdc_LVRightTemp m81 : 20|11@1- (0.15,70.05) [0|0] "" Vector__XXX
 SG_ PCS2_lite_lvBiasRailSenseMax10s m33 : 20|12@1+ (0.01,0) [0|0] "" Vector__XXX
 SG_ PCS2_L2NLatchedExpectedWhileCharging m140 : 21|1@1+ (1,0) [0|0] "" Vector__XXX
 SG_ PCS2_L3NLatchedExpectedWhileCharging m140 : 22|1@1+ (1,0) [0|0] "" Vector__XXX
 SG_ PCS2_cycloACmdSwitchingFreq_min_1s m156 : 22|14@1+ (0.1,150) [0|0] "" Vector__XXX
 SG_ PCS2_cycloAEnableRequest m135 : 22|1@1+ (1,0) [0|0] "" Vector__XXX
 SG_ PCS2_cycloBCmdSwitchingFreq_min_1s m203 : 22|14@1+ (0.1,150) [0|0] "" Vector__XXX
 SG_ PCS2_L1L2LatchedExpectedWhileCharging m140 : 23|1@1+ (1,0) [0|0] "" Vector__XXX
 SG_ PCS2_cycloBEnableRequest m135 : 23|1@1+ (1,0) [0|0] "" Vector__XXX
 SG_ PCS2_48V0RailSenseMax10s m27 : 24|13@1+ (0.01,0) [0|0] "" Vector__XXX
 SG_ PCS2_48V0_18V0_CurrentSenseMax10s m28 : 24|13@1- (0.01,0) [0|0] "" Vector__XXX
 SG_ PCS2_L1L3LatchedExpectedWhileCharging m140 : 24|1@1+ (1,0) [0|0] "" Vector__XXX
 SG_ PCS2_acFrequencyL1L3 m133 : 24|13@1+ (0.01,0) [0|0] "" Vector__XXX
 SG_ PCS2_acFrequencyL2N m132 : 24|13@1+ (0.01,0) [0|0] "" Vector__XXX
 SG_ PCS2_cpu0Task1kHzUtilizationPercentageMax10s m23 : 24|8@1+ (1,0) [0|0] "" Vector__XXX
 SG_ PCS2_cpu1Task1kHzUtilizationPercentageMax10s m95 : 24|8@1+ (1,0) [0|0] "" Vector__XXX
 SG_ PCS2_cpu2Task1kHzUtilizationPercentageMax10s m158 : 24|8@1+ (1,0) [0|0] "" Vector__XXX
 SG_ PCS2_cpu3Task1kHzUtilizationPercentageMax10s m206 : 24|8@1+ (1,0) [0|0] "" Vector__XXX
 SG_ PCS2_cycloADcTempDeratingFactor m143 : 24|7@1+ (0.01,0) [0|0] "" Vector__XXX
 SG_ PCS2_cycloARetryCount m135 : 24|4@1+ (1,0) [0|0] "" Vector__XXX
 SG_ PCS2_cycloBDcTempDeratingFactor m195 : 24|7@1+ (0.01,0) [0|0] "" Vector__XXX
 SG_ PCS2_dcacHvBusCurrent m134 : 24|15@1- (0.01,0) [0|0] "" Vector__XXX
 SG_ PCS2_dcdcACmdSwitchingFreq_min_1s m21 : 24|14@1+ (0.1,150) [0|0] "" Vector__XXX
 SG_ PCS2_dcdcAHvVoltageFiltered m0 : 24|14@1+ (0.1,0) [0|0] "" Vector__XXX
 SG_ PCS2_dcdcAHvVoltageMax_10s m5 : 24|14@1+ (0.1,0) [0|0] "" Vector__XXX
 SG_ PCS2_dcdcAHvVoltageTarget m9 : 24|14@1+ (0.1,0) [0|0] "" Vector__XXX
 SG_ PCS2_dcdcALvCurrentCommand m2 : 24|13@1- (0.1,0) [0|0] "" Vector__XXX
 SG_ PCS2_dcdcAMinFaultDurationTicks m17 : 24|14@1+ (1,0) [0|0] "" Vector__XXX
 SG_ PCS2_dcdcBCmdSwitchingFreq_min_1s m78 : 24|14@1+ (0.1,150) [0|0] "" Vector__XXX
 SG_ PCS2_dcdcBHvVoltageFiltered m64 : 24|14@1+ (0.1,0) [0|0] "" Vector__XXX
 SG_ PCS2_dcdcBHvVoltageMax_10s m66 : 24|14@1+ (0.1,0) [0|0] "" Vector__XXX
 SG_ PCS2_dcdcBHvVoltageTarget m70 : 24|14@1+ (0.1,0) [0|0] "" Vector__XXX
 SG_ PCS2_dcdcBLvCurrentCommand m65 : 24|13@1- (0.1,0) [0|0] "" Vector__XXX
 SG_ PCS2_dcdcBMinFaultDurationTicks m74 : 24|14@1+ (1,0) [0|0] "" Vector__XXX
 SG_ PCS2_dcdcHvBusCurrent m83 : 24|15@1- (0.01,0) [0|0] "" Vector__XXX
 SG_ PCS2_hvBusEstimatedImpedanceLinear m73 : 24|16@1+ (10,0) [0|0] "" Vector__XXX
 SG_ PCS2_lite_boost_duty_max_10s m32 : 24|7@1+ (0.01,0) [0|0] "" Vector__XXX
 SG_ PCS2_llcControllerFreqMHzMin10s m4 : 24|8@1+ (0.01,0) [0|0] "" Vector__XXX
 SG_ PCS2_mfgFuncTestCalCtrlFreq_MHz m13 : 24|12@1+ (0.001,0) [0|0] "" Vector__XXX
 SG_ PCS2_microgridHeartbeat2hzRms m201 : 24|8@1+ (0.001,0) [0|0] "" Vector__XXX
 SG_ PCS2_phase_diff_L2N_L3N m141 : 24|8@1+ (1,0) [0|0] "" Vector__XXX
 SG_ PCS2_L2L3LatchedExpectedWhileCharging m140 : 25|1@1+ (1,0) [0|0] "" Vector__XXX
 SG_ PCS2_acL3ChassisVrms m138 : 26|9@1+ (1,0) [0|0] "" Vector__XXX
 SG_ PCS2_acL3CurrentLimitI2T m148 : 26|9@1+ (1,0) [0|0] "" Vector__XXX
 SG_ PCS2_cycloAC_L3PeakCurrent m192 : 26|9@1+ (1,0) [0|0] "" Vector__XXX
 SG_ PCS2_cycloA_tank_zcd_half_prd_meas_pu_max_1s m155 : 26|9@1- (0.01,0) [0|0] "" Vector__XXX
 SG_ PCS2_cycloB_tank_zcd_half_prd_meas_pu_max_1s m202 : 26|9@1- (0.01,0) [0|0] "" Vector__XXX
 SG_ PCS2_dcOffsetL3NVoltage m204 : 26|9@1- (4,0) [0|0] "" Vector__XXX
 SG_ PCS2_dcdcA_tank_zcd_half_prd_meas_pu_max_1s m20 : 26|9@1- (0.01,0) [0|0] "" Vector__XXX
 SG_ PCS2_dcdcB_tank_zcd_half_prd_meas_pu_max_1s m77 : 26|9@1- (0.01,0) [0|0] "" Vector__XXX
 SG_ PCS2_pcs2_pwm_xbar_time_index m35 : 26|6@1+ (1,0) [0|0] "" Vector__XXX
 SG_ PCS2_pcs2lite_pwm_xbar_time_index m36 : 26|6@1+ (1,0) [0|0] "" Vector__XXX
 SG_ PCS2_pcsci_pwm_xbar_time_index m37 : 26|6@1+ (1,0) [0|0] "" Vector__XXX
 SG_ PCS2_acL2L3Vrms m129 : 28|10@1+ (0.5,0) [0|0] "" Vector__XXX
 SG_ PCS2_acL3ContinuousCurrentLimit m149 : 28|10@1+ (0.1,0) [0|0] "" Vector__XXX
 SG_ PCS2_acL3GeneratedHeatI2TCpLimit m159 : 28|10@1+ (0.1,0) [0|0] "" Vector__XXX
 SG_ PCS2_acL3GeneratedHeatI2THwLimit m150 : 28|10@1+ (0.1,0) [0|0] "" Vector__XXX
 SG_ PCS2_acL3NVrms m128 : 28|10@1+ (0.5,0) [0|0] "" Vector__XXX
 SG_ PCS2_acL3TransientCurrentLimit m147 : 28|10@1+ (0.1,0) [0|0] "" Vector__XXX
 SG_ PCS2_acRelayState m157 : 28|3@1+ (1,0) [0|0] "" Vector__XXX
 SG_ PCS2_cycloChargingCurrentCommand m139 : 28|10@1+ (0.1,0) [0|0] "" Vector__XXX
 SG_ PCS2_dcdcAHalfBusBotVoltageMin_10s m7 : 28|10@1+ (1,0) [0|0] "" Vector__XXX
 SG_ PCS2_dcdcBHalfBusBotVoltageMin_10s m68 : 28|10@1+ (1,0) [0|0] "" Vector__XXX
 SG_ PCS2_ipcCpu0ToCpu2TotalPeriodicLockGrabFails m18 : 28|9@1+ (1,0) [0|0] "" Vector__XXX
 SG_ PCS2_ipcCpu1ToCpu2TotalPeriodicLockGrabFails m75 : 28|9@1+ (1,0) [0|0] "" Vector__XXX
 SG_ PCS2_ipcCpu2ToCpu1TotalPeriodicLockGrabFails m154 : 28|9@1+ (1,0) [0|0] "" Vector__XXX
 SG_ PCS2_ipcCpu3ToCpu1TotalPeriodicLockGrabFails m200 : 28|9@1+ (1,0) [0|0] "" Vector__XXX
 SG_ PCS2_mfgFuncTestACLineMosfetCount m12 : 28|3@1+ (1,0) [0|0] "" Vector__XXX
 SG_ PCS2_cycloA_C_tank m142 : 30|10@1+ (0.1,50) [0|0] "" Vector__XXX
 SG_ PCS2_cycloB_C_tank m194 : 30|10@1+ (0.1,50) [0|0] "" Vector__XXX
 SG_ PCS2_cyclo_A_l2_device_temp m144 : 30|11@1+ (0.1,0) [0|0] "" Vector__XXX
 SG_ PCS2_cyclo_A_l2_device_temp_max m145 : 30|11@1+ (0.1,0) [0|0] "" Vector__XXX
 SG_ PCS2_cyclo_B_l2_device_temp m196 : 30|11@1+ (0.1,0) [0|0] "" Vector__XXX
 SG_ PCS2_cyclo_B_l2_device_temp_max m197 : 30|11@1+ (0.1,0) [0|0] "" Vector__XXX
 SG_ PCS2_dcdcA_C_tank m6 : 30|10@1+ (0.05,15) [0|0] "" Vector__XXX
 SG_ PCS2_dcdcB_C_tank m67 : 30|10@1+ (0.05,15) [0|0] "" Vector__XXX
 SG_ PCS2_mfgFuncTestCalPiCtrlEnable2 m14 : 30|1@1+ (1,0) [0|0] "" Vector__XXX
 SG_ PCS2_dcacA_ac2TempIrrational m86 : 31|1@1+ (1,0) [0|0] "" Vector__XXX
 SG_ PCS2_dcacB_ac2TempIrrational m87 : 31|1@1+ (1,0) [0|0] "" Vector__XXX
 SG_ PCS2_dcdcATxWindingModelTemp m11 : 31|9@1- (1,106) [0|0] "" Vector__XXX
 SG_ PCS2_dcdcBTxWindingModelTemp m72 : 31|9@1- (1,106) [0|0] "" Vector__XXX
 SG_ PCS2_dcdcB_lv2TempIrrational m88 : 31|1@1+ (1,0) [0|0] "" Vector__XXX
 SG_ PCS2_dcdc_LVLeftTemp m81 : 31|11@1- (0.15,70.05) [0|0] "" Vector__XXX
 SG_ PCS2_mfgFuncTestACTankMosfetCount m12 : 31|2@1+ (1,0) [0|0] "" Vector__XXX
 SG_ PCS2_10V0RailSenseMin10s m24 : 32|12@1+ (0.01,0) [0|0] "" Vector__XXX
 SG_ PCS2_13V5RailSenseMin10s m29 : 32|12@1+ (0.01,0) [0|0] "" Vector__XXX
 SG_ PCS2_18V0RailSenseMin10s m16 : 32|12@1+ (0.01,0) [0|0] "" Vector__XXX
 SG_ PCS2_1V6RailSenseMin10s m26 : 32|12@1+ (0.01,0) [0|0] "" Vector__XXX
 SG_ PCS2_4V5RailSenseMin10s m25 : 32|12@1+ (0.01,0) [0|0] "" Vector__XXX
 SG_ PCS2_FC_N_VSense m31 : 32|12@1- (1,0) [0|0] "" Vector__XXX
 SG_ PCS2_acL3Arms m130 : 32|12@1+ (0.1,0) [0|0] "" Vector__XXX
 SG_ PCS2_ambientTemp m89 : 32|11@1- (0.15,70.05) [0|0] "" Vector__XXX
 SG_ PCS2_ambientTempMax_10s m82 : 32|11@1- (0.15,70.05) [0|0] "" Vector__XXX
 SG_ PCS2_ambientTempMin_10s m94 : 32|11@1- (0.15,70.05) [0|0] "" Vector__XXX
 SG_ PCS2_cabinAndBedL2L3LifetimekVAh m153 : 32|24@1+ (0.01,0) [0|0] "" Vector__XXX
 SG_ PCS2_cpGridFormLifetimekVAh m151 : 32|24@1+ (0.01,0) [0|0] "" Vector__XXX
 SG_ PCS2_cycloAC_L2L3PeakV m160 : 32|11@1+ (0.5,0) [0|0] "" Vector__XXX
 SG_ PCS2_cycloAC_L2NPeakV m136 : 32|11@1+ (0.5,0) [0|0] "" Vector__XXX
 SG_ PCS2_cycloAJunctionTempDeratingFactor m143 : 32|7@1+ (0.01,0) [0|0] "" Vector__XXX
 SG_ PCS2_cycloALineTransientRetryCount m135 : 32|7@1+ (0.1,0) [0|0] "" Vector__XXX
 SG_ PCS2_cycloATankCapacitance m137 : 32|10@1+ (0.1,50) [0|0] "" Vector__XXX
 SG_ PCS2_cycloBJunctionTempDeratingFactor m195 : 32|7@1+ (0.01,0) [0|0] "" Vector__XXX
 SG_ PCS2_cycloBTankCapacitance m193 : 32|10@1+ (0.1,50) [0|0] "" Vector__XXX
 SG_ PCS2_cyclo_A_hvdc_oc_count m146 : 32|8@1+ (1,0) [0|0] "" Vector__XXX
 SG_ PCS2_cyclo_B_hvdc_oc_count m198 : 32|8@1+ (1,0) [0|0] "" Vector__XXX
 SG_ PCS2_dcacA_dcTemp m86 : 32|11@1- (0.15,70.05) [0|0] "" Vector__XXX
 SG_ PCS2_dcacA_dcTempMax_10s m91 : 32|11@1- (0.15,70.05) [0|0] "" Vector__XXX
 SG_ PCS2_dcacA_dcTempMin_10s m90 : 32|11@1- (0.15,70.05) [0|0] "" Vector__XXX
 SG_ PCS2_dcacB_dcTemp m87 : 32|11@1- (0.15,70.05) [0|0] "" Vector__XXX
 SG_ PCS2_dcacB_dcTempMax_10s m93 : 32|11@1- (0.15,70.05) [0|0] "" Vector__XXX
 SG_ PCS2_dcacB_dcTempMin_10s m92 : 32|11@1- (0.15,70.05) [0|0] "" Vector__XXX
 SG_ PCS2_dcdcATankCapacitance m8 : 32|9@1+ (0.05,15) [0|0] "" Vector__XXX
 SG_ PCS2_dcdcAVoltageErrorTooLarge m19 : 32|1@1+ (1,0) [0|0] "" Vector__XXX
 SG_ PCS2_dcdcA_hvTemp m88 : 32|11@1- (0.15,70.05) [0|0] "" Vector__XXX
 SG_ PCS2_dcdcA_hvTempMax_10s m80 : 32|11@1- (0.15,70.05) [0|0] "" Vector__XXX
 SG_ PCS2_dcdcA_hvTempMin_10s m79 : 32|11@1- (0.15,70.05) [0|0] "" Vector__XXX
 SG_ PCS2_dcdcBTankCapacitance m69 : 32|9@1+ (0.05,15) [0|0] "" Vector__XXX
 SG_ PCS2_dcdcBVoltageErrorTooLarge m76 : 32|1@1+ (1,0) [0|0] "" Vector__XXX
 SG_ PCS2_lite_buck_duty m32 : 32|7@1+ (0.01,0) [0|0] "" Vector__XXX
 SG_ PCS2_lite_dcac_dcTemp m84 : 32|11@1- (0.15,70.05) [0|0] "" Vector__XXX
 SG_ PCS2_lite_dcdc_LV_C_Temp m85 : 32|11@1- (0.15,70.05) [0|0] "" Vector__XXX
 SG_ PCS2_lite_lvBiasRailSenseMin10s m33 : 32|12@1+ (0.01,0) [0|0] "" Vector__XXX
 SG_ PCS2_mfgFuncTestCalPiReference2 m14 : 32|5@1+ (1,0) [0|0] "" Vector__XXX
 SG_ PCS2_mfgFuncTestIOXWrExpected m15 : 32|16@1+ (1,0) [0|0] "" Vector__XXX
 SG_ PCS2_pcs2_pwm_xbar_DCDCA_TANK_ZCD m35 : 32|1@1+ (1,0) [0|0] "" Vector__XXX
 SG_ PCS2_pcs2lite_pwm_xbar_DCDCB_TANK_ZCD m36 : 32|1@1+ (1,0) [0|0] "" Vector__XXX
 SG_ PCS2_pcsci_pwm_xbar_DCDCB_TANK_ZCD m37 : 32|1@1+ (1,0) [0|0] "" Vector__XXX
 SG_ PCS2_phase_diff_L1L3_L2L3 m141 : 32|8@1+ (1,0) [0|0] "" Vector__XXX
 SG_ PCS2_remoteFilteredCoolantTemp m4 : 32|8@1- (1,46) [0|0] "" Vector__XXX
 SG_ PCS2_totalOutletLifetimekVAh m152 : 32|24@1+ (0.01,0) [0|0] "" Vector__XXX
 SG_ PCS2_dcdcACloseToPowerLimit m19 : 33|1@1+ (1,0) [0|0] "" Vector__XXX
 SG_ PCS2_dcdcBCloseToPowerLimit m76 : 33|1@1+ (1,0) [0|0] "" Vector__XXX
 SG_ PCS2_mfgFuncTestSwitchingFreq m12 : 33|14@1+ (0.1,150) [0|0] "" Vector__XXX
 SG_ PCS2_pcs2_pwm_xbar_ANY_LN_OC m35 : 33|1@1+ (1,0) [0|0] "" Vector__XXX
 SG_ PCS2_pcs2lite_pwm_xbar_ANY_LN_OC m36 : 33|1@1+ (1,0) [0|0] "" Vector__XXX
 SG_ PCS2_dcdcATransientPowerNotEnough m19 : 34|1@1+ (1,0) [0|0] "" Vector__XXX
 SG_ PCS2_dcdcBTransientPowerNotEnough m76 : 34|1@1+ (1,0) [0|0] "" Vector__XXX
 SG_ PCS2_pcs2_pwm_xbar_CYCLOA_TANK_ZCD m35 : 34|1@1+ (1,0) [0|0] "" Vector__XXX
 SG_ PCS2_acL2PreRelayChassisVrms m138 : 35|9@1+ (1,0) [0|0] "" Vector__XXX
 SG_ PCS2_acLNCurrentLimitI2T m148 : 35|9@1+ (1,0) [0|0] "" Vector__XXX
 SG_ PCS2_cycloAC_NPeakCurrent m192 : 35|9@1+ (1,0) [0|0] "" Vector__XXX
 SG_ PCS2_cycloA_tank_zcd_half_prd_meas_pu_min_1s m155 : 35|9@1- (0.01,0) [0|0] "" Vector__XXX
 SG_ PCS2_cycloB_tank_zcd_half_prd_meas_pu_min_1s m202 : 35|9@1- (0.01,0) [0|0] "" Vector__XXX
 SG_ PCS2_dcOffsetL1L2Voltage m204 : 35|9@1- (4,0) [0|0] "" Vector__XXX
 SG_ PCS2_dcdcA_tank_zcd_half_prd_meas_pu_min_1s m20 : 35|9@1- (0.01,0) [0|0] "" Vector__XXX
 SG_ PCS2_dcdcB_tank_zcd_half_prd_meas_pu_min_1s m77 : 35|9@1- (0.01,0) [0|0] "" Vector__XXX
 SG_ PCS2_pcs2_pwm_xbar_CYCLOA_SECONDARY_TRIPOUT m35 : 35|1@1+ (1,0) [0|0] "" Vector__XXX
 SG_ PCS2_pcs2lite_pwm_xbar_CYCLOA_SECONDARY_TRIPOUT m36 : 35|1@1+ (1,0) [0|0] "" Vector__XXX
 SG_ PCS2_cycloA_tank_zcd_measured_freq_max_1s m156 : 36|14@1+ (0.1,150) [0|0] "" Vector__XXX
 SG_ PCS2_cycloB_tank_zcd_measured_freq_max_1s m203 : 36|14@1+ (0.1,150) [0|0] "" Vector__XXX
 SG_ PCS2_mfg_nvm_gdps_id_begin m13 : 36|3@1+ (1,0) [0|0] "" Vector__XXX
 SG_ PCS2_pcs2_pwm_xbar_CYCLOB_SECONDARY_TRIPOUT m35 : 36|1@1+ (1,0) [0|0] "" Vector__XXX
 SG_ PCS2_dcdcAPowerLimit m2 : 37|12@1+ (1,0) [0|0] "" Vector__XXX
 SG_ PCS2_dcdcBPowerLimit m65 : 37|12@1+ (1,0) [0|0] "" Vector__XXX
 SG_ PCS2_ipcCpu0ToCpu3TotalPeriodicLockGrabFails m18 : 37|9@1+ (1,0) [0|0] "" Vector__XXX
 SG_ PCS2_ipcCpu1ToCpu3TotalPeriodicLockGrabFails m75 : 37|9@1+ (1,0) [0|0] "" Vector__XXX
 SG_ PCS2_ipcCpu2ToCpu3TotalPeriodicLockGrabFails m154 : 37|9@1+ (1,0) [0|0] "" Vector__XXX
 SG_ PCS2_ipcCpu3ToCpu2TotalPeriodicLockGrabFails m200 : 37|9@1+ (1,0) [0|0] "" Vector__XXX
 SG_ PCS2_pcs2lite_pwm_xbar_DCDC_GDPS m36 : 37|1@1+ (1,0) [0|0] "" Vector__XXX
 SG_ PCS2_acGndN m128 : 38|10@1- (1,0) [0|0] "" Vector__XXX
 SG_ PCS2_acLNContinuousCurrentLimit m149 : 38|10@1+ (0.1,0) [0|0] "" Vector__XXX
 SG_ PCS2_acLNGeneratedHeatI2TCpLimit m159 : 38|10@1+ (0.1,0) [0|0] "" Vector__XXX
 SG_ PCS2_acLNGeneratedHeatI2THwLimit m150 : 38|10@1+ (0.1,0) [0|0] "" Vector__XXX
 SG_ PCS2_acLNTransientCurrentLimit m147 : 38|10@1+ (0.1,0) [0|0] "" Vector__XXX
 SG_ PCS2_cycloChargingCurrentCommandReal m139 : 38|10@1+ (0.1,0) [0|0] "" Vector__XXX
 SG_ PCS2_dcdcABursting m17 : 38|1@1+ (1,0) [0|0] "" Vector__XXX
 SG_ PCS2_dcdcAHalfBusBotVoltageMax_10s m7 : 38|10@1+ (1,0) [0|0] "" Vector__XXX
 SG_ PCS2_dcdcAHvTopVoltage m0 : 38|13@1+ (0.1,0) [0|0] "" Vector__XXX
 SG_ PCS2_dcdcBBursting m74 : 38|1@1+ (1,0) [0|0] "" Vector__XXX
 SG_ PCS2_dcdcBHalfBusBotVoltageMax_10s m68 : 38|10@1+ (1,0) [0|0] "" Vector__XXX
 SG_ PCS2_dcdcBHvTopVoltage m64 : 38|13@1+ (0.1,0) [0|0] "" Vector__XXX
 SG_ PCS2_dcdcLvVoltageMin_10s m66 : 38|13@1+ (0.01,0) [0|0] "" Vector__XXX
 SG_ PCS2_pcs2_pwm_xbar_CYCLOA_COMBINEDX m35 : 38|1@1+ (1,0) [0|0] "" Vector__XXX
 SG_ PCS2_pcs2lite_pwm_xbar_CYCLOA_COMBINEDX m36 : 38|1@1+ (1,0) [0|0] "" Vector__XXX
 SG_ PCS2_cycloBRetryCount m135 : 39|4@1+ (1,0) [0|0] "" Vector__XXX
 SG_ PCS2_dcdcAlvuvSurgeLocked m17 : 39|1@1+ (1,0) [0|0] "" Vector__XXX
 SG_ PCS2_pcs2_pwm_xbar_CYCLOB_COMBINEDX m35 : 39|1@1+ (1,0) [0|0] "" Vector__XXX
 SG_ PCS2_pcs2lite_pwm_xbar_TEMPSENSE m36 : 39|1@1+ (1,0) [0|0] "" Vector__XXX
 SG_ PCS2_pcsci_pwm_xbar_DATA_TEMPSENSE m37 : 39|1@1+ (1,0) [0|0] "" Vector__XXX
 SG_ PCS2_48V0RailSenseMin10s m27 : 40|13@1+ (0.01,0) [0|0] "" Vector__XXX
 SG_ PCS2_48V0_18V0_CurrentSenseMin10s m28 : 40|13@1- (0.01,0) [0|0] "" Vector__XXX
 SG_ PCS2_acFrequencyL2L3 m133 : 40|13@1+ (0.01,0) [0|0] "" Vector__XXX
 SG_ PCS2_acFrequencyL3N m132 : 40|13@1+ (0.01,0) [0|0] "" Vector__XXX
 SG_ PCS2_canBusOffOccurrencePer10s m4 : 40|7@1+ (1,0) [0|0] "" Vector__XXX
 SG_ PCS2_cycloAInductorLossDeratingFactor m143 : 40|7@1+ (0.01,0) [0|0] "" Vector__XXX
 SG_ PCS2_cycloBInductorLossDeratingFactor m195 : 40|7@1+ (0.01,0) [0|0] "" Vector__XXX
 SG_ PCS2_dcdcAHvImpedanceEstState m9 : 40|3@1+ (1,0) [0|0] "" Vector__XXX
 SG_ PCS2_dcdcATxWindingModelHvCurrentLimit m11 : 40|14@1- (0.01,0) [0|0] "" Vector__XXX
 SG_ PCS2_dcdcBHvImpedanceEstState m70 : 40|3@1+ (1,0) [0|0] "" Vector__XXX
 SG_ PCS2_dcdcBTankSelfTestState m74 : 40|2@1+ (1,0) [0|0] "" Vector__XXX
 SG_ PCS2_dcdcBTxWindingModelHvCurrentLimit m72 : 40|14@1- (0.01,0) [0|0] "" Vector__XXX
 SG_ PCS2_hvBusEstimatedImpedanceLogarithm m73 : 40|16@1+ (10,0) [0|0] "" Vector__XXX
 SG_ PCS2_lite_buck_duty_min_10s m32 : 40|7@1+ (0.01,0) [0|0] "" Vector__XXX
 SG_ PCS2_mfgFuncTestCalCtrlFreq2_MHz m14 : 40|12@1+ (0.001,0) [0|0] "" Vector__XXX
 SG_ PCS2_mfg_nvm_gdps_id_end m13 : 40|3@1+ (1,0) [0|0] "" Vector__XXX
 SG_ PCS2_pcs2_pwm_xbar_DCDCA_COMBINEDX m35 : 40|1@1+ (1,0) [0|0] "" Vector__XXX
 SG_ PCS2_pcs2lite_pwm_xbar_DCAC_GDPS_COMBINEDX m36 : 40|1@1+ (1,0) [0|0] "" Vector__XXX
 SG_ PCS2_phase_diff_pre_relay_L1N_L2N m141 : 40|8@1+ (1,0) [0|0] "" Vector__XXX
 SG_ PCS2_cyclo_A_l3_device_temp m144 : 41|11@1+ (0.1,0) [0|0] "" Vector__XXX
 SG_ PCS2_cyclo_A_l3_device_temp_max m145 : 41|11@1+ (0.1,0) [0|0] "" Vector__XXX
 SG_ PCS2_cyclo_B_l3_device_temp m196 : 41|11@1+ (0.1,0) [0|0] "" Vector__XXX
 SG_ PCS2_cyclo_B_l3_device_temp_max m197 : 41|11@1+ (0.1,0) [0|0] "" Vector__XXX
 SG_ PCS2_dcdcATankMagInductance m8 : 41|12@1+ (0.1,0) [0|0] "" Vector__XXX
 SG_ PCS2_dcdcBTankMagInductance m69 : 41|12@1+ (0.1,0) [0|0] "" Vector__XXX
 SG_ PCS2_pcs2_pwm_xbar_DCDCB_COMBINEDX m35 : 41|1@1+ (1,0) [0|0] "" Vector__XXX
 SG_ PCS2_pcs2lite_pwm_xbar_DCDCB_COMBINEDX m36 : 41|1@1+ (1,0) [0|0] "" Vector__XXX
 SG_ PCS2_pcsci_pwm_xbar_DCDCB_COMBINEDX m37 : 41|1@1+ (1,0) [0|0] "" Vector__XXX
 SG_ PCS2_cycloATankMagInductance m137 : 42|12@1+ (0.1,0) [0|0] "" Vector__XXX
 SG_ PCS2_cycloBTankMagInductance m193 : 42|12@1+ (0.1,0) [0|0] "" Vector__XXX
 SG_ PCS2_dcdcBlvuvSurgeLocked m74 : 42|1@1+ (1,0) [0|0] "" Vector__XXX
 SG_ PCS2_dcdc_CoolantInTemp m81 : 42|11@1- (0.15,70.05) [0|0] "" Vector__XXX
 SG_ PCS2_pcs2_pwm_xbar_ANY_LN_OV m35 : 42|1@1+ (1,0) [0|0] "" Vector__XXX
 SG_ PCS2_pcs2lite_pwm_xbar_ANY_LN_OV m36 : 42|1@1+ (1,0) [0|0] "" Vector__XXX
 SG_ PCS2_coolantTemp m89 : 43|11@1- (0.15,70.05) [0|0] "" Vector__XXX
 SG_ PCS2_coolantTempMax_10s m82 : 43|11@1- (0.15,70.05) [0|0] "" Vector__XXX
 SG_ PCS2_coolantTempMin_10s m94 : 43|11@1- (0.15,70.05) [0|0] "" Vector__XXX
 SG_ PCS2_cycloAC_L3NPeakV m136 : 43|11@1+ (0.5,0) [0|0] "" Vector__XXX
 SG_ PCS2_cycloBLineTransientRetryCount m135 : 43|7@1+ (0.1,0) [0|0] "" Vector__XXX
 SG_ PCS2_dcacA_dcTempIrrational m86 : 43|1@1+ (1,0) [0|0] "" Vector__XXX
 SG_ PCS2_dcacB_dcTempIrrational m87 : 43|1@1+ (1,0) [0|0] "" Vector__XXX
 SG_ PCS2_dcdcA_hvTempIrrational m88 : 43|1@1+ (1,0) [0|0] "" Vector__XXX
 SG_ PCS2_dcdcB_hvTempMax_10s m80 : 43|11@1- (0.15,70.05) [0|0] "" Vector__XXX
 SG_ PCS2_dcdcB_hvTempMin_10s m79 : 43|11@1- (0.15,70.05) [0|0] "" Vector__XXX
 SG_ PCS2_lite_dcac_dcTempIrrational m84 : 43|1@1+ (1,0) [0|0] "" Vector__XXX
 SG_ PCS2_lite_dcdc_hvTemp m85 : 43|11@1- (0.15,70.05) [0|0] "" Vector__XXX
 SG_ PCS2_mfg_nvm_num_tables_in_last_commit m13 : 43|3@1+ (1,0) [0|0] "" Vector__XXX
 SG_ PCS2_pcs2_pwm_xbar_CYCLOA_I_TANK m35 : 43|1@1+ (1,0) [0|0] "" Vector__XXX
 SG_ PCS2_pcs2lite_pwm_xbar_CYCLOA_I_TANK m36 : 43|1@1+ (1,0) [0|0] "" Vector__XXX
 SG_ PCS2_acL3PreRelayChassisVrms m138 : 44|9@1+ (1,0) [0|0] "" Vector__XXX
 SG_ PCS2_acLNArms m130 : 44|12@1+ (0.1,0) [0|0] "" Vector__XXX
 SG_ PCS2_dcOffsetL1L3Voltage m204 : 44|9@1- (4,0) [0|0] "" Vector__XXX
 SG_ PCS2_dcdcB_hvTemp m88 : 44|11@1- (0.15,70.05) [0|0] "" Vector__XXX
 SG_ PCS2_lite_dcac_ac3Temp m84 : 44|11@1- (0.15,70.05) [0|0] "" Vector__XXX
 SG_ PCS2_pcs2_pwm_xbar_CYCLOB_I_TANK m35 : 44|1@1+ (1,0) [0|0] "" Vector__XXX
 SG_ PCS2_pcsci_pwm_xbar_CP_LATCH_OC m37 : 44|1@1+ (1,0) [0|0] "" Vector__XXX
 SG_ PCS2_pcs2_pwm_xbar_DCDCA_I_TANK m35 : 45|1@1+ (1,0) [0|0] "" Vector__XXX
 SG_ PCS2_pcsci_pwm_xbar_CP_RESERVED m37 : 45|1@1+ (1,0) [0|0] "" Vector__XXX
 SG_ PCS2_mfg_ac_line_LUT_is_committed m13 : 46|1@1+ (1,0) [0|0] "" Vector__XXX
 SG_ PCS2_pcs2_pwm_xbar_DCDCB_I_TANK m35 : 46|1@1+ (1,0) [0|0] "" Vector__XXX
 SG_ PCS2_pcs2lite_pwm_xbar_DCDCB_I_TANK m36 : 46|1@1+ (1,0) [0|0] "" Vector__XXX
 SG_ PCS2_pcsci_pwm_xbar_DCDCB_I_TANK m37 : 46|1@1+ (1,0) [0|0] "" Vector__XXX
 SG_ PCS2_mfgFuncTestResult m12 : 47|14@1- (0.01,0) [0|0] "" Vector__XXX
 SG_ PCS2_mfg_ac_tank_LUT_is_committed m13 : 47|1@1+ (1,0) [0|0] "" Vector__XXX
 SG_ PCS2_pcs2_pwm_xbar_DCDCB_TANK_ZCD m35 : 47|1@1+ (1,0) [0|0] "" Vector__XXX
 SG_ PCS2_IONVMM_ServerState m4 : 48|3@1+ (1,0) [0|0] "" Vector__XXX
 SG_ PCS2_acGndNVrms m128 : 48|10@1+ (0.5,0) [0|0] "" Vector__XXX
 SG_ PCS2_acSurgeCurrentLimit m147 : 48|10@1+ (0.1,0) [0|0] "" Vector__XXX
 SG_ PCS2_bmsLimitDeratingFactor m148 : 48|7@1+ (0.01,0) [0|0] "" Vector__XXX
 SG_ PCS2_cycloChargingCurrentCommandReactive m139 : 48|10@1+ (0.1,0) [0|0] "" Vector__XXX
 SG_ PCS2_dcdcAHalfBusCompensationPiOutputMin_1s m7 : 48|7@1- (1,0) [0|0] "" Vector__XXX
 SG_ PCS2_dcdcBHalfBusCompensationPiOutputMin_1s m68 : 48|7@1- (1,0) [0|0] "" Vector__XXX
 SG_ PCS2_hvToAcVoltageRatioDeratingFactor m149 : 48|7@1+ (0.01,0) [0|0] "" Vector__XXX
 SG_ PCS2_lite_buck_duty_max_10s m32 : 48|7@1+ (0.01,0) [0|0] "" Vector__XXX
 SG_ PCS2_mfgFuncTestIOXWrActual m15 : 48|16@1+ (1,0) [0|0] "" Vector__XXX
 SG_ PCS2_mfg_dc_tank_LUT_is_committed m13 : 48|1@1+ (1,0) [0|0] "" Vector__XXX
 SG_ PCS2_pcs2_pwm_xbar_L1N_CMPSS_OC m35 : 48|1@1+ (1,0) [0|0] "" Vector__XXX
 SG_ PCS2_pcs2lite_pwm_xbar_L1N_CMPSS_OC m36 : 48|1@1+ (1,0) [0|0] "" Vector__XXX
 SG_ PCS2_phase_diff_pre_relay_L1N_L3N m141 : 48|8@1+ (1,0) [0|0] "" Vector__XXX
 SG_ PCS2_dcdcALvCurrentEstimated m2 : 49|13@1- (0.1,0) [0|0] "" Vector__XXX
 SG_ PCS2_dcdcBLvCurrentEstimated m65 : 49|13@1- (0.1,0) [0|0] "" Vector__XXX
 SG_ PCS2_mfg_dcdcx_LUT_is_committed m13 : 49|1@1+ (1,0) [0|0] "" Vector__XXX
 SG_ PCS2_pcs2_pwm_xbar_CYCLOB_TANK_ZCD m35 : 49|1@1+ (1,0) [0|0] "" Vector__XXX
 SG_ PCS2_pcs2lite_pwm_xbar_CYCLOA_TANK_ZCD m36 : 49|1@1+ (1,0) [0|0] "" Vector__XXX
 SG_ PCS2_cycloABlockedReason m135 : 50|3@1+ (1,0) [0|0] "" Vector__XXX
 SG_ PCS2_cycloA_tank_zcd_measured_freq_min_1s m156 : 50|14@1+ (0.1,150) [0|0] "" Vector__XXX
 SG_ PCS2_cycloB_tank_zcd_measured_freq_min_1s m203 : 50|14@1+ (0.1,150) [0|0] "" Vector__XXX
 SG_ PCS2_pcs2_pwm_xbar_L2N_CMPSS_OC m35 : 50|1@1+ (1,0) [0|0] "" Vector__XXX
 SG_ PCS2_pcs2lite_pwm_xbar_L2N_CMPSS_OC m36 : 50|1@1+ (1,0) [0|0] "" Vector__XXX
 SG_ PCS2_BuckBoostState m4 : 51|3@1+ (1,0) [0|0] "" Vector__XXX
 SG_ PCS2_dcdcAHvBottomVoltage m0 : 51|13@1+ (0.1,0) [0|0] "" Vector__XXX
 SG_ PCS2_dcdcBHvBottomVoltage m64 : 51|13@1+ (0.1,0) [0|0] "" Vector__XXX
 SG_ PCS2_dcdcLvVoltageMax_10s m66 : 51|13@1+ (0.01,0) [0|0] "" Vector__XXX
 SG_ PCS2_pcs2_pwm_xbar_L3N_CMPSS_OC m35 : 51|1@1+ (1,0) [0|0] "" Vector__XXX
 SG_ PCS2_pcs2lite_pwm_xbar_L3N_CMPSS_OC m36 : 51|1@1+ (1,0) [0|0] "" Vector__XXX
 SG_ PCS2_cyclo_A_ln_device_temp m144 : 52|11@1+ (0.1,0) [0|0] "" Vector__XXX
 SG_ PCS2_cyclo_A_ln_device_temp_max m145 : 52|11@1+ (0.1,0) [0|0] "" Vector__XXX
 SG_ PCS2_cyclo_B_ln_device_temp m196 : 52|11@1+ (0.1,0) [0|0] "" Vector__XXX
 SG_ PCS2_cyclo_B_ln_device_temp_max m197 : 52|11@1+ (0.1,0) [0|0] "" Vector__XXX
 SG_ PCS2_mfgFuncTestIOXWriteRetry m14 : 52|10@1+ (1,0) [0|0] "" Vector__XXX
 SG_ PCS2_pcs2_pwm_xbar_LN_OC m35 : 52|1@1+ (1,0) [0|0] "" Vector__XXX
 SG_ PCS2_pcs2lite_pwm_xbar_LN_OC m36 : 52|1@1+ (1,0) [0|0] "" Vector__XXX
 SG_ PCS2_L1L2_pllLocked m133 : 53|1@1+ (1,0) [0|0] "" Vector__XXX
 SG_ PCS2_L1N_pllLocked m132 : 53|1@1+ (1,0) [0|0] "" Vector__XXX
 SG_ PCS2_cycloBBlockedReason m135 : 53|3@1+ (1,0) [0|0] "" Vector__XXX
 SG_ PCS2_dcOffsetL2L3Voltage m204 : 53|9@1- (4,0) [0|0] "" Vector__XXX
 SG_ PCS2_dcdc_CoolantOutTemp m81 : 53|11@1- (0.15,70.05) [0|0] "" Vector__XXX
 SG_ PCS2_pcs2_pwm_xbar_CYCLOA_COMBINEDY m35 : 53|1@1+ (1,0) [0|0] "" Vector__XXX
 SG_ PCS2_pcs2lite_pwm_xbar_CYCLOA_COMBINEDY m36 : 53|1@1+ (1,0) [0|0] "" Vector__XXX
 SG_ PCS2_L1L3_pllLocked m133 : 54|1@1+ (1,0) [0|0] "" Vector__XXX
 SG_ PCS2_L2N_pllLocked m132 : 54|1@1+ (1,0) [0|0] "" Vector__XXX
 SG_ PCS2_dcdcALvModelTemp m11 : 54|9@1- (1,106) [0|0] "" Vector__XXX
 SG_ PCS2_dcdcBLvModelTemp m72 : 54|9@1- (1,106) [0|0] "" Vector__XXX
 SG_ PCS2_lite_dcdc_hvTempIrrational m85 : 54|1@1+ (1,0) [0|0] "" Vector__XXX
 SG_ PCS2_pcs2_pwm_xbar_CYCLOB_COMBINEDY m35 : 54|1@1+ (1,0) [0|0] "" Vector__XXX
 SG_ PCS2_pcs2lite_pwm_xbar_BUCK_BOOST_OV m36 : 54|1@1+ (1,0) [0|0] "" Vector__XXX
 SG_ PCS2_L2L3_pllLocked m133 : 55|1@1+ (1,0) [0|0] "" Vector__XXX
 SG_ PCS2_L3N_pllLocked m132 : 55|1@1+ (1,0) [0|0] "" Vector__XXX
 SG_ PCS2_dcdcB_hvTempIrrational m88 : 55|1@1+ (1,0) [0|0] "" Vector__XXX
 SG_ PCS2_lite_dcac_ac3TempIrrational m84 : 55|1@1+ (1,0) [0|0] "" Vector__XXX
 SG_ PCS2_pcs2_pwm_xbar_DCDCA_COMBINEDY m35 : 55|1@1+ (1,0) [0|0] "" Vector__XXX
 SG_ PCS2_pcs2lite_pwm_xbar_DCAC_GDPS_COMBINEDY m36 : 55|1@1+ (1,0) [0|0] "" Vector__XXX
 SG_ PCS2_acManagerOperatingMode m135 : 56|4@1+ (1,0) [0|0] "" Vector__XXX
 SG_ PCS2_baseCurrentLimitDeratingFactor m149 : 56|7@1+ (0.01,0) [0|0] "" Vector__XXX
 SG_ PCS2_dcdcAHalfBusCompensationPiOutputMax_1s m7 : 56|7@1- (1,0) [0|0] "" Vector__XXX
 SG_ PCS2_dcdcBHalfBusCompensationPiOutputMax_1s m68 : 56|7@1- (1,0) [0|0] "" Vector__XXX
 SG_ PCS2_lite_buck_boost_cbc_leakybucket m32 : 56|8@1+ (0.1,0) [0|0] "" Vector__XXX
 SG_ PCS2_pcs2_pwm_xbar_DCDCB_COMBINEDY m35 : 56|1@1+ (1,0) [0|0] "" Vector__XXX
 SG_ PCS2_pcs2lite_pwm_xbar_DCDCB_COMBINEDY m36 : 56|1@1+ (1,0) [0|0] "" Vector__XXX
 SG_ PCS2_pcsci_pwm_xbar_DCDCB_COMBINEDY m37 : 56|1@1+ (1,0) [0|0] "" Vector__XXX
 SG_ PCS2_phase_diff_pre_relay_L2N_L3N m141 : 56|8@1+ (1,0) [0|0] "" Vector__XXX
 SG_ PCS2_pcs2_pwm_xbar_TEMPSENSE m35 : 57|1@1+ (1,0) [0|0] "" Vector__XXX
 SG_ PCS2_pcs2lite_pwm_xbar_BUCK_BOOST_UV m36 : 57|1@1+ (1,0) [0|0] "" Vector__XXX
 SG_ PCS2_pcs2_pwm_xbar_HVDC_OC m35 : 58|1@1+ (1,0) [0|0] "" Vector__XXX
 SG_ PCS2_pcs2lite_pwm_xbar_HVDC_OC m36 : 58|1@1+ (1,0) [0|0] "" Vector__XXX
 SG_ PCS2_pcsci_pwm_xbar_HVDC_OC m37 : 58|1@1+ (1,0) [0|0] "" Vector__XXX
 SG_ PCS2_pcs2_pwm_xbar_LV_BUS_OV_OR_UV m35 : 59|1@1+ (1,0) [0|0] "" Vector__XXX
 SG_ PCS2_pcs2lite_pwm_xbar_LV_BUS_OV_OR_UV m36 : 59|1@1+ (1,0) [0|0] "" Vector__XXX
 SG_ PCS2_pcsci_pwm_xbar_LV_BUS_OV_OR_UV m37 : 59|1@1+ (1,0) [0|0] "" Vector__XXX
 SG_ PCS2_legHardTiedToNeutral m135 : 60|2@1+ (1,0) [0|0] "" Vector__XXX
 SG_ PCS2_pcs2_pwm_xbar_HV_BUS_OV_OR_UV m35 : 60|1@1+ (1,0) [0|0] "" Vector__XXX
 SG_ PCS2_pcs2lite_pwm_xbar_HV_BUS_OV_OR_UV m36 : 60|1@1+ (1,0) [0|0] "" Vector__XXX
 SG_ PCS2_pcsci_pwm_xbar_HV_BUS_OV_OR_UV m37 : 60|1@1+ (1,0) [0|0] "" Vector__XXX
 SG_ PCS2_mfgFuncTestTopBoardEnable m12 : 61|1@1+ (1,0) [0|0] "" Vector__XXX
 SG_ PCS2_pcs2_pwm_xbar_HV_BATT_OV_OR_UV m35 : 61|1@1+ (1,0) [0|0] "" Vector__XXX
 SG_ PCS2_latchedLineConfiguration m135 : 62|2@1+ (1,0) [0|0] "" Vector__XXX
 SG_ PCS2_mfgFuncTestBottomBoardEnable m12 : 62|1@1+ (1,0) [0|0] "" Vector__XXX
 SG_ PCS2_dcdcAThermalLimited m11 : 63|1@1+ (1,0) [0|0] "" Vector__XXX
 SG_ PCS2_dcdcBThermalLimited m72 : 63|1@1+ (1,0) [0|0] "" Vector__XXX
 SG_ PCS2_mfgFuncTestVoltageEmuMeasEnable m12 : 63|1@1+ (1,0) [0|0] "" Vector__XXX

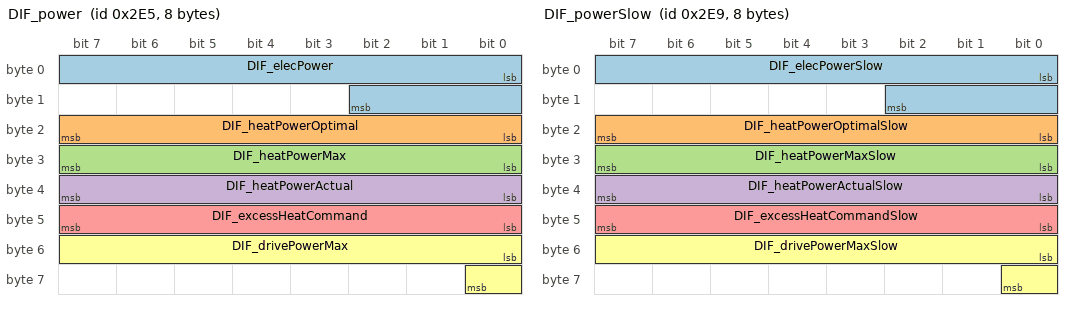
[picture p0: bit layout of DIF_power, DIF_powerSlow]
BO_ 741 DIF_power: 8 Vector__XXX
 SG_ DIF_elecPower : 0|11@1- (0.5,0) [0|0] "" Vector__XXX
 SG_ DIF_heatPowerOptimal : 16|8@1+ (0.08,0) [0|0] "" Vector__XXX
 SG_ DIF_heatPowerMax : 24|8@1+ (0.08,0) [0|0] "" Vector__XXX
 SG_ DIF_heatPowerActual : 32|8@1+ (0.08,0) [0|0] "" Vector__XXX
 SG_ DIF_excessHeatCommand : 40|8@1+ (0.08,0) [0|0] "" Vector__XXX
 SG_ DIF_drivePowerMax : 48|9@1+ (1,0) [0|0] "" Vector__XXX

BO_ 744 EPBR_status: 8 Vector__XXX
 SG_ EPBR_systemStatus : 0|4@1+ (1,0) [0|0] "" Vector__XXX
 SG_ EPBR_freeRollModeStatus : 4|2@1+ (1,0) [0|0] "" Vector__XXX
 SG_ EPBR_driverIsLeaving : 6|1@1+ (1,0) [0|0] "" Vector__XXX
 SG_ EPBR_driverIsLeavingAnySpeed : 7|1@1+ (1,0) [0|0] "" Vector__XXX
 SG_ EPBR_systemCdpAvailable : 8|1@1+ (1,0) [0|0] "" Vector__XXX
 SG_ EPBR_chimeRequest : 9|3@1+ (1,0) [0|0] "" Vector__XXX
 SG_ EPBR_telltale : 12|3@1+ (1,0) [0|0] "" Vector__XXX
 SG_ EPBR_audioCurrentSpikeDetected : 15|1@1+ (1,0) [0|0] "" Vector__XXX
 SG_ EPBR_redundantBrakingEnabled : 16|1@1+ (1,0) [0|0] "" Vector__XXX
 SG_ EPBR_summonEnabled : 17|1@1+ (1,0) [0|0] "" Vector__XXX
 SG_ EPBR_brakeLight : 18|1@1+ (1,0) [0|0] "" Vector__XXX
 SG_ EPBR_epbConfigMismatch : 19|1@1+ (1,0) [0|0] "" Vector__XXX
 SG_ EPBR_brakeConfirmedPressed : 20|1@1+ (1,0) [0|0] "" Vector__XXX
 SG_ EPBR_requestUserConfirmation : 21|1@1+ (1,0) [0|0] "" Vector__XXX
 SG_ EPBR_uiWinchModeMiscBlocking : 22|1@1+ (1,0) [0|0] "" Vector__XXX
 SG_ EPBR_winchModeActive : 23|1@1+ (1,0) [0|0] "" Vector__XXX
 SG_ EPBR_updateMode : 24|1@1+ (1,0) [0|0] "" Vector__XXX
 SG_ EPBR_winchModePermissive : 25|1@1+ (1,0) [0|0] "" Vector__XXX
 SG_ EPBR_winchModePending : 26|1@1+ (1,0) [0|0] "" Vector__XXX
 SG_ EPBR_cdpRequest : 27|1@1+ (1,0) [0|0] "" Vector__XXX
 SG_ EPBR_uiParkAvailable : 28|2@1+ (1,0) [0|0] "" Vector__XXX
 SG_ EPBR_brakeDiscWipeRequest : 30|2@1+ (1,0) [0|0] "" Vector__XXX
 SG_ EPBR_showUiGearShifter : 32|1@1+ (1,0) [0|0] "" Vector__XXX
 SG_ EPBR_uiWinchModeLvStatus : 33|2@1+ (1,0) [0|0] "" Vector__XXX
 SG_ EPBR_contactorCycleNotNeededForWinchEntry : 35|1@1+ (1,0) [0|0] "" Vector__XXX
 SG_ EPBR_showStalkFaultedOnUi : 45|1@1+ (1,0) [0|0] "" Vector__XXX
 SG_ EPBR_espPowerRequest : 46|1@1+ (1,0) [0|0] "" Vector__XXX
 SG_ EPBR_okToPark : 47|1@1+ (1,0) [0|0] "" Vector__XXX
 SG_ EPBR_hornRequest : 48|1@1+ (1,0) [0|0] "" Vector__XXX
 SG_ EPBR_winchModeAvailable : 49|1@1+ (1,0) [0|0] "" Vector__XXX
 SG_ EPBR_bothDisconnected : 50|1@1+ (1,0) [0|0] "" Vector__XXX
 SG_ EPBR_blockDrive : 51|1@1+ (1,0) [0|0] "" Vector__XXX
 SG_ EPBR_statusCounter : 52|4@1+ (1,0) [0|0] "" Vector__XXX
 SG_ EPBR_statusChecksum : 56|8@1+ (1,0) [0|0] "" Vector__XXX

BO_ 745 DIF_powerSlow: 8 Vector__XXX
 SG_ DIF_elecPowerSlow : 0|11@1- (0.5,0) [0|0] "" Vector__XXX
 SG_ DIF_heatPowerOptimalSlow : 16|8@1+ (0.08,0) [0|0] "" Vector__XXX
 SG_ DIF_heatPowerMaxSlow : 24|8@1+ (0.08,0) [0|0] "" Vector__XXX
 SG_ DIF_heatPowerActualSlow : 32|8@1+ (0.08,0) [0|0] "" Vector__XXX
 SG_ DIF_excessHeatCommandSlow : 40|8@1+ (0.08,0) [0|0] "" Vector__XXX
 SG_ DIF_drivePowerMaxSlow : 48|9@1+ (1,0) [0|0] "" Vector__XXX

BO_ 753 VCFRONT_eFuseDebugStatus: 8 Vector__XXX
 SG_ VCFRONT_eFuseDebugStatusIndex M : 0|5@1+ (1,0) [0|0] "" Vector__XXX
 SG_ VCFRONT_mcuAudioState m18 : 5|1@1+ (1,0) [0|0] "" Vector__XXX
 SG_ VCFRONT_mcuLogicState m11 : 5|1@1+ (1,0) [0|0] "" Vector__XXX
 SG_ VCFRONT_pump1AndFanState m14 : 5|1@1+ (1,0) [0|0] "" Vector__XXX
 SG_ VCFRONT_mcuAudioFault m18 : 6|1@1+ (1,0) [0|0] "" Vector__XXX
 SG_ VCFRONT_mcuLogicFault m11 : 6|1@1+ (1,0) [0|0] "" Vector__XXX
 SG_ VCFRONT_pump1AndFanCurrent m14 : 6|16@1+ (0.05,0) [0|0] "" Vector__XXX
 SG_ VCFRONT_EPAS3PState m4 : 8|2@1+ (1,0) [0|0] "" Vector__XXX
 SG_ VCFRONT_EPAS3SState m5 : 8|2@1+ (1,0) [0|0] "" Vector__XXX
 SG_ VCFRONT_ESPMotorState m6 : 8|2@1+ (1,0) [0|0] "" Vector__XXX
 SG_ VCFRONT_ESPValveState m7 : 8|2@1+ (1,0) [0|0] "" Vector__XXX
 SG_ VCFRONT_PCSState m2 : 8|2@1+ (1,0) [0|0] "" Vector__XXX
 SG_ VCFRONT_autopilot1State m8 : 8|2@1+ (1,0) [0|0] "" Vector__XXX
 SG_ VCFRONT_autopilot2State m9 : 8|2@1+ (1,0) [0|0] "" Vector__XXX
 SG_ VCFRONT_chargedIBSAmpHours m17 : 8|16@1+ (1,0) [0|0] "" Vector__XXX
 SG_ VCFRONT_eFuseLockoutVoltage m16 : 8|12@1+ (0.005443676098,0) [0|0] "" Vector__XXX
 SG_ VCFRONT_headlampLeftState m12 : 8|1@1+ (1,0) [0|0] "" Vector__XXX
 SG_ VCFRONT_iBoosterState m3 : 8|2@1+ (1,0) [0|0] "" Vector__XXX
 SG_ VCFRONT_leftControllerState m1 : 8|2@1+ (1,0) [0|0] "" Vector__XXX
 SG_ VCFRONT_mcuAudioCurrent m18 : 8|10@1+ (0.025,0) [0|0] "" Vector__XXX
 SG_ VCFRONT_mcuLogicCurrent m11 : 8|10@1+ (0.027,0) [0|0] "" Vector__XXX
 SG_ VCFRONT_railA_12v m15 : 8|12@1+ (0.005443676098,0) [0|0] "" Vector__XXX
 SG_ VCFRONT_rightControllerState m0 : 8|2@1+ (1,0) [0|0] "" Vector__XXX
 SG_ VCFRONT_sleepBypassState m10 : 8|1@1+ (1,0) [0|0] "" Vector__XXX
 SG_ VCFRONT_vbatFusedHighState m13 : 8|1@1+ (1,0) [0|0] "" Vector__XXX
 SG_ VCFRONT_headlampLeftFault m12 : 9|1@1+ (1,0) [0|0] "" Vector__XXX
 SG_ VCFRONT_sleepBypassFault m10 : 9|1@1+ (1,0) [0|0] "" Vector__XXX
 SG_ VCFRONT_vbatFusedHighFault m13 : 9|1@1+ (1,0) [0|0] "" Vector__XXX
 SG_ VCFRONT_EPAS3PFault m4 : 10|1@1+ (1,0) [0|0] "" Vector__XXX
 SG_ VCFRONT_EPAS3SFault m5 : 10|1@1+ (1,0) [0|0] "" Vector__XXX
 SG_ VCFRONT_ESPMotorFault m6 : 10|1@1+ (1,0) [0|0] "" Vector__XXX
 SG_ VCFRONT_ESPValveFault m7 : 10|1@1+ (1,0) [0|0] "" Vector__XXX
 SG_ VCFRONT_PCSFault m2 : 10|1@1+ (1,0) [0|0] "" Vector__XXX
 SG_ VCFRONT_autopilot1Fault m8 : 10|1@1+ (1,0) [0|0] "" Vector__XXX
 SG_ VCFRONT_autopilot2Fault m9 : 10|1@1+ (1,0) [0|0] "" Vector__XXX
 SG_ VCFRONT_headlampLeftCurrent m12 : 10|10@1+ (0.027,0) [0|0] "" Vector__XXX
 SG_ VCFRONT_iBoosterFault m3 : 10|1@1+ (1,0) [0|0] "" Vector__XXX
 SG_ VCFRONT_leftControllerFault m1 : 10|1@1+ (1,0) [0|0] "" Vector__XXX
 SG_ VCFRONT_rightControllerFault m0 : 10|1@1+ (1,0) [0|0] "" Vector__XXX
 SG_ VCFRONT_sleepBypassVoltage m10 : 10|16@1+ (0.1,0) [0|0] "" Vector__XXX
 SG_ VCFRONT_vbatFusedSelfTestResult m13 : 10|4@1+ (1,0) [0|0] "" Vector__XXX
 SG_ VCFRONT_EPAS3PSelfTestResult m4 : 11|4@1+ (1,0) [0|0] "" Vector__XXX
 SG_ VCFRONT_EPAS3SSelfTestResult m5 : 11|4@1+ (1,0) [0|0] "" Vector__XXX
 SG_ VCFRONT_ESPMotorSelfTestResult m6 : 11|4@1+ (1,0) [0|0] "" Vector__XXX
 SG_ VCFRONT_autopilot1Temp m8 : 11|11@1+ (0.125,-40) [0|0] "" Vector__XXX
 SG_ VCFRONT_autopilot2Temp m9 : 11|11@1+ (0.125,-40) [0|0] "" Vector__XXX
 SG_ VCFRONT_iBoosterSelfTestResult m3 : 11|4@1+ (1,0) [0|0] "" Vector__XXX
 SG_ VCFRONT_pcsSelfTestResult m2 : 11|4@1+ (1,0) [0|0] "" Vector__XXX
 SG_ VCFRONT_vcleftSelfTestResult m1 : 11|4@1+ (1,0) [0|0] "" Vector__XXX
 SG_ VCFRONT_vcrightSelfTestResult m0 : 11|4@1+ (1,0) [0|0] "" Vector__XXX
 SG_ VCFRONT_ESPValveTemp m7 : 12|11@1+ (0.125,-40) [0|0] "" Vector__XXX
 SG_ VCFRONT_vbatFusedHighTemp m13 : 14|11@1+ (0.125,-40) [0|0] "" Vector__XXX
 SG_ VCFRONT_EPAS3PTemp m4 : 15|11@1+ (0.125,-40) [0|0] "" Vector__XXX
 SG_ VCFRONT_EPAS3STemp m5 : 15|11@1+ (0.125,-40) [0|0] "" Vector__XXX
 SG_ VCFRONT_ESPMotorTemp m6 : 15|11@1+ (0.125,-40) [0|0] "" Vector__XXX
 SG_ VCFRONT_PCSTemp m2 : 15|11@1+ (0.125,-40) [0|0] "" Vector__XXX
 SG_ VCFRONT_iBoosterTemp m3 : 15|11@1+ (0.125,-40) [0|0] "" Vector__XXX
 SG_ VCFRONT_leftControllerTemp m1 : 15|11@1+ (0.125,-40) [0|0] "" Vector__XXX
 SG_ VCFRONT_rightControllerTemp m0 : 15|11@1+ (0.125,-40) [0|0] "" Vector__XXX
 SG_ VCFRONT_headlampLeftVoltage m12 : 20|8@1+ (0.1,0) [0|0] "" Vector__XXX
 SG_ VCFRONT_railB_12v m15 : 20|12@1+ (0.005443676098,0) [0|0] "" Vector__XXX
 SG_ VCFRONT_pump1AndFanVoltage m14 : 22|12@1+ (0.1,0) [0|0] "" Vector__XXX
 SG_ VCFRONT_ChargePumpVoltage m16 : 24|16@1+ (0.005443676098,0) [0|0] "" Vector__XXX
 SG_ VCFRONT_dischargedIBSAmpHours m17 : 24|16@1+ (1,0) [0|0] "" Vector__XXX
 SG_ VCFRONT_mcuAudioVoltage m18 : 24|8@1+ (0.1,0) [0|0] "" Vector__XXX
 SG_ VCFRONT_mcuLogicVoltage m11 : 24|8@1+ (0.1,0) [0|0] "" Vector__XXX
 SG_ VCFRONT_sleepBypassCurrent m10 : 26|16@1+ (0.1,0) [0|0] "" Vector__XXX
 SG_ VCFRONT_autopilot1Voltage m8 : 27|16@1+ (0.1,0) [0|0] "" Vector__XXX
 SG_ VCFRONT_autopilot2Voltage m9 : 27|16@1+ (0.1,0) [0|0] "" Vector__XXX
 SG_ VCFRONT_ESPValveVoltage m7 : 28|16@1+ (0.1,0) [0|0] "" Vector__XXX
 SG_ VCFRONT_headlampRightState m12 : 28|1@1+ (1,0) [0|0] "" Vector__XXX
 SG_ VCFRONT_headlampRightFault m12 : 29|1@1+ (1,0) [0|0] "" Vector__XXX
 SG_ VCFRONT_headlampRightCurrent m12 : 30|10@1+ (0.027,0) [0|0] "" Vector__XXX
 SG_ VCFRONT_vbatFusedHighVoltage m13 : 30|16@1+ (0.1,0) [0|0] "" Vector__XXX
 SG_ VCFRONT_EPAS3PVoltage m4 : 31|9@1+ (0.1,0) [0|0] "" Vector__XXX
 SG_ VCFRONT_EPAS3SVoltage m5 : 31|14@1+ (0.1,0) [0|0] "" Vector__XXX
 SG_ VCFRONT_ESPMotorVoltage m6 : 31|14@1+ (0.1,0) [0|0] "" Vector__XXX
 SG_ VCFRONT_PCSVoltage m2 : 31|14@1+ (0.1,0) [0|0] "" Vector__XXX
 SG_ VCFRONT_iBoosterVoltage m3 : 31|9@1+ (0.1,0) [0|0] "" Vector__XXX
 SG_ VCFRONT_leftControllerVoltage m1 : 31|14@1+ (0.1,0) [0|0] "" Vector__XXX
 SG_ VCFRONT_rightControllerVoltage m0 : 31|14@1+ (0.1,0) [0|0] "" Vector__XXX
 SG_ VCFRONT_railA_5v m15 : 32|12@1+ (0.005443676098,0) [0|0] "" Vector__XXX
 SG_ VCFRONT_pump2AndAirCompState m14 : 34|1@1+ (1,0) [0|0] "" Vector__XXX
 SG_ VCFRONT_pump2AndAirCompCurrent m14 : 35|10@1+ (0.05,0) [0|0] "" Vector__XXX
 SG_ VCFRONT_IBSUnfilteredTemperature m17 : 40|16@1- (0.01,0) [0|0] "" Vector__XXX
 SG_ VCFRONT_headlampLeftCurrentFiltered m16 : 40|10@1+ (0.027,0) [0|0] "" Vector__XXX
 SG_ VCFRONT_headlampRightVoltage m12 : 40|8@1+ (0.1,0) [0|0] "" Vector__XXX
 SG_ VCFRONT_mcuGraphicsState m18 : 40|1@1+ (1,0) [0|0] "" Vector__XXX
 SG_ VCFRONT_mcuGraphicsFault m18 : 41|1@1+ (1,0) [0|0] "" Vector__XXX
 SG_ VCFRONT_mcuGraphicsCurrent m18 : 42|16@1+ (0.1,0) [0|0] "" Vector__XXX
 SG_ VCFRONT_autopilot1Current m8 : 43|10@1+ (0.044,0) [0|0] "" Vector__XXX
 SG_ VCFRONT_autopilot2Current m9 : 43|10@1+ (0.044,0) [0|0] "" Vector__XXX
 SG_ VCFRONT_ESPValveCurrent m7 : 44|16@1+ (0.01,0) [0|0] "" Vector__XXX
 SG_ VCFRONT_railB_5v m15 : 44|12@1+ (0.005443676098,0) [0|0] "" Vector__XXX
 SG_ VCFRONT_vbatFusedHighCurrent m13 : 46|16@1+ (0.1,0) [0|0] "" Vector__XXX
 SG_ VCFRONT_EPAS3PCurrent m4 : 47|14@1+ (0.1,0) [0|0] "" Vector__XXX
 SG_ VCFRONT_EPAS3SCurrent m5 : 47|14@1+ (0.1,0) [0|0] "" Vector__XXX
 SG_ VCFRONT_ESPMotorCurrent m6 : 47|14@1+ (0.1,0) [0|0] "" Vector__XXX
 SG_ VCFRONT_iBoosterCurrent m3 : 47|14@1+ (0.1,0) [0|0] "" Vector__XXX
 SG_ VCFRONT_leftControllerCurrent m1 : 47|14@1+ (0.1,0) [0|0] "" Vector__XXX
 SG_ VCFRONT_rightControllerCurrent m0 : 47|14@1+ (0.1,0) [0|0] "" Vector__XXX
 SG_ VCFRONT_headlampLeftTemperature m12 : 48|8@1+ (1,-40) [0|0] "" Vector__XXX
 SG_ VCFRONT_headlampRightCurrentFiltered m16 : 50|10@1+ (0.027,0) [0|0] "" Vector__XXX
 SG_ VCFRONT_pump2AndAirCompVoltage m14 : 51|12@1+ (0.1,0) [0|0] "" Vector__XXX
 SG_ VCFRONT_headlampRightTemperature m12 : 56|8@1+ (1,-40) [0|0] "" Vector__XXX

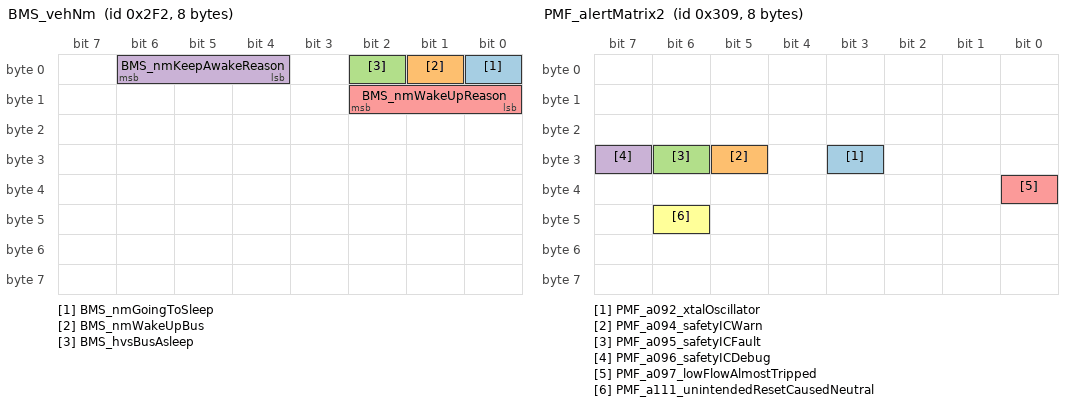
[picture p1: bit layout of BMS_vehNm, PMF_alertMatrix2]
BO_ 754 BMS_vehNm: 8 Vector__XXX
 SG_ BMS_nmGoingToSleep : 0|1@1+ (1,0) [0|0] "" Vector__XXX
 SG_ BMS_nmWakeUpBus : 1|1@1+ (1,0) [0|0] "" Vector__XXX
 SG_ BMS_hvsBusAsleep : 2|1@1+ (1,0) [0|0] "" Vector__XXX
 SG_ BMS_nmKeepAwakeReason : 4|3@1+ (1,0) [0|0] "" Vector__XXX
 SG_ BMS_nmWakeUpReason : 8|3@1+ (1,0) [0|0] "" Vector__XXX

BO_ 755 UI_hvacRequest: 8 Vector__XXX
 SG_ UI_hvacReqTempSetpointLeft : 0|5@1+ (0.5,15) [0|0] "" Vector__XXX
 SG_ UI_hvacReqAutoBlowerLevel : 5|3@1+ (1,0) [0|0] "" Vector__XXX
 SG_ UI_hvacReqTempSetpointRight : 8|5@1+ (0.5,15) [0|0] "" Vector__XXX
 SG_ UI_hvacReqAirDistributionMode : 13|3@1+ (1,0) [0|0] "" Vector__XXX
 SG_ UI_hvacReqBlowerSegment : 16|4@1+ (1,0) [0|0] "" Vector__XXX
 SG_ UI_hvacReqRecirc : 20|2@1+ (1,0) [0|0] "" Vector__XXX
 SG_ UI_hvacReqACDisable : 22|2@1+ (1,0) [0|0] "" Vector__XXX
 SG_ UI_hvacDefogState : 24|2@1+ (1,0) [0|0] "" Vector__XXX
 SG_ UI_hvacReqUserPowerState : 26|3@1+ (1,0) [0|0] "" Vector__XXX
 SG_ UI_hvacReqSecondRowState : 29|3@1+ (1,0) [0|0] "" Vector__XXX
 SG_ UI_hvacUseModeledDuctTemp : 32|1@1+ (1,0) [0|0] "" Vector__XXX
 SG_ UI_hvacReqKeepClimateOn : 33|2@1+ (1,0) [0|0] "" Vector__XXX
 SG_ UI_hvacReqBioWeaponDefMode : 35|1@1+ (1,0) [0|0] "" Vector__XXX
 SG_ UI_hvacLatchPassengerPresent : 39|1@1+ (1,0) [0|0] "" Vector__XXX
 SG_ UI_enableHvacControlsFeatures1 : 44|1@1+ (1,0) [0|0] "" Vector__XXX
 SG_ UI_enableHvacNotifications : 45|1@1+ (1,0) [0|0] "" Vector__XXX
 SG_ UI_hvacPhoneCallAirFlowAdjustEnabled : 46|1@1+ (1,0) [0|0] "" Vector__XXX
 SG_ UI_enableHvacVOCPurgeRoutine : 47|1@1+ (1,0) [0|0] "" Vector__XXX
 SG_ UI_enableCustomerTHSAlerts : 53|1@1+ (1,0) [0|0] "" Vector__XXX
 SG_ UI_evapDryingSelectiveEnable : 54|1@1+ (1,0) [0|0] "" Vector__XXX
 SG_ UI_enableHvacWeatherDataBasedHumidityControls : 55|1@1+ (1,0) [0|0] "" Vector__XXX
 SG_ UI_hvacReqTempSetpointCOP : 56|2@1+ (1,0) [0|0] "" Vector__XXX
 SG_ UI_hvacClimateNudgeStatus : 58|3@1+ (1,0) [0|0] "" Vector__XXX
 SG_ UI_enableHvacControlsFeatures2 : 61|1@1+ (1,0) [0|0] "" Vector__XXX
 SG_ UI_enableHvacAPFoggingMonitor : 62|1@1+ (1,0) [0|0] "" Vector__XXX
 SG_ UI_enableHvacLimpMode : 63|1@1+ (1,0) [0|0] "" Vector__XXX

BO_ 761 VCSEC_additionalAuthInfo: 8 Vector__XXX
 SG_ VCSEC_algoUsedForSummonRange0 m1 : 0|1@1+ (1,0) [0|0] "" Vector__XXX
 SG_ VCSEC_algoUsedForSummonRange1 m2 : 0|1@1+ (1,0) [0|0] "" Vector__XXX
 SG_ VCSEC_algoUsedForSummonRange2 m3 : 0|1@1+ (1,0) [0|0] "" Vector__XXX
 SG_ VCSEC_activeKeyDebug : 2|5@1+ (1,0) [0|0] "" Vector__XXX
 SG_ VCSEC_bleChannelDisconnected : 7|4@1+ (1,0) [0|0] "" Vector__XXX
 SG_ VCSEC_bleDisconnectionReason : 11|8@1+ (1,0) [0|0] "" Vector__XXX
 SG_ VCSEC_bleConnetionAttemptWLEntry : 19|5@1+ (1,0) [0|0] "" Vector__XXX
 SG_ VCSEC_activeKeyReason m0 : 24|3@1+ (1,0) [0|0] "" Vector__XXX
 SG_ VCSEC_AdditionalAuthInfoIndex M : 27|3@1+ (1,0) [0|0] "" Vector__XXX
 SG_ VCSEC_BLEDeviceWithinSummonRange m4 : 32|32@1+ (1,0) [0|0] "" Vector__XXX
 SG_ VCSEC_NFCAuthFromBPillarFormFactor m5 : 32|3@1+ (1,0) [0|0] "" Vector__XXX
 SG_ VCSEC_activeKeySHA1 m0 : 32|32@1+ (1,0) [0|0] "" Vector__XXX
 SG_ VCSEC_keyWithinSummonRange0 m1 : 32|32@1+ (1,0) [0|0] "" Vector__XXX
 SG_ VCSEC_keyWithinSummonRange1 m2 : 32|32@1+ (1,0) [0|0] "" Vector__XXX
 SG_ VCSEC_keyWithinSummonRange2 m3 : 32|32@1+ (1,0) [0|0] "" Vector__XXX
 SG_ VCSEC_NFCAuthFromCenterConsoleFormFactor m5 : 35|3@1+ (1,0) [0|0] "" Vector__XXX

BO_ 768 BMS_info: 8 Vector__XXX
 SG_ BMS_infoIndex M : 0|8@1+ (1,0) [0|0] "" Vector__XXX
 SG_ BMS_appGitHash m17 : 8|56@1+ (1,0) [0|0] "" Vector__XXX
 SG_ BMS_bootGitHash m18 : 8|56@1+ (1,0) [0|0] "" Vector__XXX
 SG_ BMS_bootUdsProtoVersion m20 : 8|8@1+ (1,0) [0|0] "" Vector__XXX
 SG_ BMS_buildType m10 : 8|3@1+ (1,0) [0|0] "" Vector__XXX
 SG_ BMS_platformType m13 : 8|8@1+ (1,0) [0|0] "" Vector__XXX
 SG_ BMS_buildConfigId m10 : 16|16@1+ (1,0) [0|0] "" Vector__XXX
 SG_ BMS_pcbaId m11 : 16|8@1+ (1,0) [0|0] "" Vector__XXX
 SG_ BMS_assemblyId m11 : 24|8@1+ (1,0) [0|0] "" Vector__XXX
 SG_ BMS_appCrc m13 : 32|32@1+ (1,0) [0|0] "" Vector__XXX
 SG_ BMS_bootCrc m20 : 32|32@1+ (1,0) [0|0] "" Vector__XXX
 SG_ BMS_hardwareId m10 : 32|16@1+ (1,0) [0|0] "" Vector__XXX
 SG_ BMS_usageId m11 : 32|16@1+ (1,0) [0|0] "" Vector__XXX
 SG_ BMS_componentId m10 : 48|16@1+ (1,0) [0|0] "" Vector__XXX
 SG_ BMS_subUsageId m11 : 48|16@1+ (1,0) [0|0] "" Vector__XXX

BO_ 769 VCFRONT_info: 8 Vector__XXX
 SG_ VCFRONT_infoIndex M : 0|8@1+ (1,0) [0|0] "" Vector__XXX
 SG_ VCFRONT_infoAppCrc m13 : 8|32@1+ (1,0) [0|0] "" Vector__XXX
 SG_ VCFRONT_infoAppGitHash m17 : 8|56@1+ (1,0) [0|0] "" Vector__XXX
 SG_ VCFRONT_infoBootGitHash m18 : 8|56@1+ (1,0) [0|0] "" Vector__XXX
 SG_ VCFRONT_infoBootUdsProtoVersion m20 : 8|16@1+ (1,0) [0|0] "" Vector__XXX
 SG_ VCFRONT_infoBuildType m10 : 8|3@1+ (1,0) [0|0] "" Vector__XXX
 SG_ VCFRONT_infoPcbaId m11 : 8|8@1+ (1,0) [0|0] "" Vector__XXX
 SG_ VCFRONT_infoPlatformType m19 : 8|8@1+ (1,0) [0|0] "" Vector__XXX
 SG_ VCFRONT_infoAssemblyId m11 : 16|8@1+ (1,0) [0|0] "" Vector__XXX
 SG_ VCFRONT_infoBuildConfigId m10 : 16|16@1+ (1,0) [0|0] "" Vector__XXX
 SG_ VCFRONT_infoBootCrc m20 : 24|32@1+ (1,0) [0|0] "" Vector__XXX
 SG_ VCFRONT_infoUsageId m11 : 24|16@1+ (1,0) [0|0] "" Vector__XXX
 SG_ VCFRONT_infoBattPumpAppCRC m32 : 32|32@1+ (1,0) [0|0] "" Vector__XXX
 SG_ VCFRONT_infoFanAppCRC m34 : 32|32@1+ (1,0) [0|0] "" Vector__XXX
 SG_ VCFRONT_infoHardwareId m10 : 32|16@1+ (1,0) [0|0] "" Vector__XXX
 SG_ VCFRONT_infoPtPumpAppCRC m33 : 32|32@1+ (1,0) [0|0] "" Vector__XXX
 SG_ VCFRONT_infoSubcomponent10 m37 : 32|32@1+ (1,0) [0|0] "" Vector__XXX
 SG_ VCFRONT_infoSubcomponent11 m38 : 32|32@1+ (1,0) [0|0] "" Vector__XXX
 SG_ VCFRONT_infoSubcomponent12 m39 : 32|32@1+ (1,0) [0|0] "" Vector__XXX
 SG_ VCFRONT_infoSubcomponent13 m40 : 32|32@1+ (1,0) [0|0] "" Vector__XXX
 SG_ VCFRONT_infoSubcomponent14 m41 : 32|32@1+ (1,0) [0|0] "" Vector__XXX
 SG_ VCFRONT_infoSubcomponent3 m24 : 32|32@1+ (1,0) [0|0] "" Vector__XXX
 SG_ VCFRONT_infoSubcomponent8 m35 : 32|32@1+ (1,0) [0|0] "" Vector__XXX
 SG_ VCFRONT_infoSubcomponent9 m36 : 32|32@1+ (1,0) [0|0] "" Vector__XXX
 SG_ VC_infoHCMLAppCRC m16 : 32|32@1+ (1,0) [0|0] "" Vector__XXX
 SG_ VC_infoHCMRAppCRC m23 : 32|32@1+ (1,0) [0|0] "" Vector__XXX
 SG_ VC_infoWiperAppCRC m31 : 32|32@1+ (1,0) [0|0] "" Vector__XXX
 SG_ VCFRONT_infoSubUsageId m11 : 40|16@1+ (1,0) [0|0] "" Vector__XXX
 SG_ VCFRONT_infoComponentId m10 : 48|16@1+ (1,0) [0|0] "" Vector__XXX

BO_ 770 VCLEFT_info: 8 Vector__XXX
 SG_ VCLEFT_infoIndex M : 0|8@1+ (1,0) [0|0] "" Vector__XXX
 SG_ VCLEFT_infoAppCrc m13 : 8|32@1+ (1,0) [0|0] "" Vector__XXX
 SG_ VCLEFT_infoAppGitHash m17 : 8|56@1+ (1,0) [0|0] "" Vector__XXX
 SG_ VCLEFT_infoBootGitHash m18 : 8|56@1+ (1,0) [0|0] "" Vector__XXX
 SG_ VCLEFT_infoBootUdsProtoVersion m20 : 8|16@1+ (1,0) [0|0] "" Vector__XXX
 SG_ VCLEFT_infoBuildType m10 : 8|3@1+ (1,0) [0|0] "" Vector__XXX
 SG_ VCLEFT_infoPcbaId m11 : 8|8@1+ (1,0) [0|0] "" Vector__XXX
 SG_ VCLEFT_infoPlatformType m19 : 8|8@1+ (1,0) [0|0] "" Vector__XXX
 SG_ VCLEFT_infoAssemblyId m11 : 16|8@1+ (1,0) [0|0] "" Vector__XXX
 SG_ VCLEFT_infoBuildConfigId m10 : 16|16@1+ (1,0) [0|0] "" Vector__XXX
 SG_ VCLEFT_infoBootCrc m20 : 24|32@1+ (1,0) [0|0] "" Vector__XXX
 SG_ VCLEFT_infoUsageId m11 : 24|16@1+ (1,0) [0|0] "" Vector__XXX
 SG_ VCLEFT_infoCBCAppCRC m31 : 32|32@1+ (1,0) [0|0] "" Vector__XXX
 SG_ VCLEFT_infoHardwareId m10 : 32|16@1+ (1,0) [0|0] "" Vector__XXX
 SG_ VCLEFT_infoLUMBARLAppCRC m16 : 32|32@1+ (1,0) [0|0] "" Vector__XXX
 SG_ VCLEFT_infoRGBIPFLAppCRC m38 : 32|32@1+ (1,0) [0|0] "" Vector__XXX
 SG_ VCLEFT_infoRGBIPFRAppCRC m39 : 32|32@1+ (1,0) [0|0] "" Vector__XXX
 SG_ VCLEFT_infoSubcomponent3 m24 : 32|32@1+ (1,0) [0|0] "" Vector__XXX
 SG_ VCLEFT_infoTLCAppCRC m33 : 32|32@1+ (1,0) [0|0] "" Vector__XXX
 SG_ VCLEFT_infoVCUSBAppCRC m32 : 32|32@1+ (1,0) [0|0] "" Vector__XXX
 SG_ VCLEFT_swcAppCRC m23 : 32|32@1+ (1,0) [0|0] "" Vector__XXX
 SG_ VCLEFT_infoSubUsageId m11 : 40|16@1+ (1,0) [0|0] "" Vector__XXX
 SG_ VCLEFT_infoComponentId m10 : 48|16@1+ (1,0) [0|0] "" Vector__XXX

BO_ 771 VCRIGHT_info: 8 Vector__XXX
 SG_ VCRIGHT_infoIndex M : 0|8@1+ (1,0) [0|0] "" Vector__XXX
 SG_ VCRIGHT_infoAppCrc m13 : 8|32@1+ (1,0) [0|0] "" Vector__XXX
 SG_ VCRIGHT_infoAppGitHash m17 : 8|56@1+ (1,0) [0|0] "" Vector__XXX
 SG_ VCRIGHT_infoBootGitHash m18 : 8|56@1+ (1,0) [0|0] "" Vector__XXX
 SG_ VCRIGHT_infoBootUdsProtoVersion m20 : 8|16@1+ (1,0) [0|0] "" Vector__XXX
 SG_ VCRIGHT_infoBuildType m10 : 8|3@1+ (1,0) [0|0] "" Vector__XXX
 SG_ VCRIGHT_infoPcbaId m11 : 8|8@1+ (1,0) [0|0] "" Vector__XXX
 SG_ VCRIGHT_infoPlatformType m19 : 8|8@1+ (1,0) [0|0] "" Vector__XXX
 SG_ VCRIGHT_infoAssemblyId m11 : 16|8@1+ (1,0) [0|0] "" Vector__XXX
 SG_ VCRIGHT_infoBuildConfigId m10 : 16|16@1+ (1,0) [0|0] "" Vector__XXX
 SG_ VCRIGHT_infoBootCrc m20 : 24|32@1+ (1,0) [0|0] "" Vector__XXX
 SG_ VCRIGHT_infoUsageId m11 : 24|16@1+ (1,0) [0|0] "" Vector__XXX
 SG_ VCRIGHT_infoHardwareId m10 : 32|16@1+ (1,0) [0|0] "" Vector__XXX
 SG_ VCRIGHT_infoLUMBARRAppCRC m16 : 32|32@1+ (1,0) [0|0] "" Vector__XXX
 SG_ VCRIGHT_infoSubcomponent3 m24 : 32|32@1+ (1,0) [0|0] "" Vector__XXX
 SG_ VCRIGHT_infoSubcomponent4 m31 : 32|32@1+ (1,0) [0|0] "" Vector__XXX
 SG_ VCRIGHT_infoSubcomponent5 m32 : 32|32@1+ (1,0) [0|0] "" Vector__XXX
 SG_ VCRIGHT_infoSubcomponent6 m33 : 32|32@1+ (1,0) [0|0] "" Vector__XXX
 SG_ VCRIGHT_thsAppCRC m23 : 32|32@1+ (1,0) [0|0] "" Vector__XXX
 SG_ VCRIGHT_infoSubUsageId m11 : 40|16@1+ (1,0) [0|0] "" Vector__XXX
 SG_ VCRIGHT_infoComponentId m10 : 48|16@1+ (1,0) [0|0] "" Vector__XXX

BO_ 772 PMF_alertMatrix1: 8 Vector__XXX
 SG_ PMF_a001_absoluteTorque : 0|1@1+ (1,0) [0|0] "" Vector__XXX
 SG_ PMF_a002_excessiveAccelTorque : 1|1@1+ (1,0) [0|0] "" Vector__XXX
 SG_ PMF_a003_excessiveReversalTorque : 2|1@1+ (1,0) [0|0] "" Vector__XXX
 SG_ PMF_a004_excessiveDecelTorque : 3|1@1+ (1,0) [0|0] "" Vector__XXX
 SG_ PMF_a005_torqueInNeutralOrPark : 4|1@1+ (1,0) [0|0] "" Vector__XXX
 SG_ PMF_a008_memoryError : 7|1@1+ (1,0) [0|0] "" Vector__XXX
 SG_ PMF_a010_diMIA : 9|1@1+ (1,0) [0|0] "" Vector__XXX
 SG_ PMF_a011_phaseCurrentIrrational : 10|1@1+ (1,0) [0|0] "" Vector__XXX
 SG_ PMF_a012_canDataBusA : 11|1@1+ (1,0) [0|0] "" Vector__XXX
 SG_ PMF_a013_canHardwareBusA : 12|1@1+ (1,0) [0|0] "" Vector__XXX
 SG_ PMF_a017_brakeMIA : 16|1@1+ (1,0) [0|0] "" Vector__XXX
 SG_ PMF_a018_encoderIrrational : 17|1@1+ (1,0) [0|0] "" Vector__XXX
 SG_ PMF_a019_statorTempIrrational : 18|1@1+ (1,0) [0|0] "" Vector__XXX
 SG_ PMF_a025_unintendedReset : 24|1@1+ (1,0) [0|0] "" Vector__XXX
 SG_ PMF_a026_diHeartBeatMIA : 25|1@1+ (1,0) [0|0] "" Vector__XXX
 SG_ PMF_a027_torqueEstimationOutOfBounds : 26|1@1+ (1,0) [0|0] "" Vector__XXX
 SG_ PMF_a028_torqueCmdError : 27|1@1+ (1,0) [0|0] "" Vector__XXX
 SG_ PMF_a031_highStackUsage : 30|1@1+ (1,0) [0|0] "" Vector__XXX
 SG_ PMF_a032_registerConfigError : 31|1@1+ (1,0) [0|0] "" Vector__XXX
 SG_ PMF_a033_selfTest : 32|1@1+ (1,0) [0|0] "" Vector__XXX
 SG_ PMF_a034_trqCrossCheck : 33|1@1+ (1,0) [0|0] "" Vector__XXX
 SG_ PMF_a035_udsTransactionInitiated : 34|1@1+ (1,0) [0|0] "" Vector__XXX
 SG_ PMF_a036_preWatchdog : 35|1@1+ (1,0) [0|0] "" Vector__XXX
 SG_ PMF_a037_hvpMIA : 36|1@1+ (1,0) [0|0] "" Vector__XXX
 SG_ PMF_a039_disMIA : 38|1@1+ (1,0) [0|0] "" Vector__XXX
 SG_ PMF_a040_pmMIA : 39|1@1+ (1,0) [0|0] "" Vector__XXX
 SG_ PMF_a042_gtwMIA : 41|1@1+ (1,0) [0|0] "" Vector__XXX
 SG_ PMF_a045_motorMovementDetected : 44|1@1+ (1,0) [0|0] "" Vector__XXX
 SG_ PMF_a053_vcfrontMIA : 52|1@1+ (1,0) [0|0] "" Vector__XXX
 SG_ PMF_a054_uiMIA : 53|1@1+ (1,0) [0|0] "" Vector__XXX
 SG_ PMF_a055_resolver : 54|1@1+ (1,0) [0|0] "" Vector__XXX
 SG_ PMF_a056_canHardwareBusB : 55|1@1+ (1,0) [0|0] "" Vector__XXX
 SG_ PMF_a057_canDataBusB : 56|1@1+ (1,0) [0|0] "" Vector__XXX
 SG_ PMF_a061_DIPMVersionMismatch : 60|1@1+ (1,0) [0|0] "" Vector__XXX
 SG_ PMF_a062_eccError : 61|1@1+ (1,0) [0|0] "" Vector__XXX
 SG_ PMF_a064_torqueIntervention : 63|1@1+ (1,0) [0|0] "" Vector__XXX

BO_ 775 PTC_faultsAndExtras: 8 Vector__XXX
 SG_ PTC_faultLVLow : 1|1@1+ (1,0) [0|0] "" Vector__XXX
 SG_ PTC_faultLVHigh : 2|1@1+ (1,0) [0|0] "" Vector__XXX
 SG_ PTC_faultHVLow : 3|1@1+ (1,0) [0|0] "" Vector__XXX
 SG_ PTC_faultHVHigh : 4|1@1+ (1,0) [0|0] "" Vector__XXX
 SG_ PTC_faultLeftOverCurrent : 5|1@1+ (1,0) [0|0] "" Vector__XXX
 SG_ PTC_faultRightOverCurrent : 6|1@1+ (1,0) [0|0] "" Vector__XXX
 SG_ PTC_faultLeftThermalShutOutlet : 7|1@1+ (1,0) [0|0] "" Vector__XXX
 SG_ PTC_faultRightThermalShutOutlet : 8|1@1+ (1,0) [0|0] "" Vector__XXX
 SG_ PTC_faultThermalShutPCB : 9|1@1+ (1,0) [0|0] "" Vector__XXX
 SG_ PTC_faultLeftThermalShutIGBT : 10|1@1+ (1,0) [0|0] "" Vector__XXX
 SG_ PTC_faultRightThermalShutIGBT : 12|1@1+ (1,0) [0|0] "" Vector__XXX
 SG_ PTC_faultCANTimeout : 13|1@1+ (1,0) [0|0] "" Vector__XXX
 SG_ PTC_failLowVoltageSensor : 14|1@1+ (1,0) [0|0] "" Vector__XXX
 SG_ PTC_failHighVoltageSensor : 15|1@1+ (1,0) [0|0] "" Vector__XXX
 SG_ PTC_failLeftCurrentHVSensor : 16|1@1+ (1,0) [0|0] "" Vector__XXX
 SG_ PTC_failRightCurrentHVSensor : 17|1@1+ (1,0) [0|0] "" Vector__XXX
 SG_ PTC_failLeftTempIGBT : 18|1@1+ (1,0) [0|0] "" Vector__XXX
 SG_ PTC_failTempOCP : 19|1@1+ (1,0) [0|0] "" Vector__XXX
 SG_ PTC_failRightTempIGBT : 20|1@1+ (1,0) [0|0] "" Vector__XXX
 SG_ PTC_failTempPCB : 21|1@1+ (1,0) [0|0] "" Vector__XXX
 SG_ PTC_failLeftIGBTShort : 22|1@1+ (1,0) [0|0] "" Vector__XXX
 SG_ PTC_failRightIGBTShort : 23|1@1+ (1,0) [0|0] "" Vector__XXX
 SG_ PTC_failIGBTDriverTemporary : 24|1@1+ (1,0) [0|0] "" Vector__XXX
 SG_ PTC_failIGBTDriverPermanent : 25|1@1+ (1,0) [0|0] "" Vector__XXX
 SG_ PTC_failLeftIGBTOpen : 26|1@1+ (1,0) [0|0] "" Vector__XXX
 SG_ PTC_failRightIGBTOpen : 27|1@1+ (1,0) [0|0] "" Vector__XXX
 SG_ PTC_failLeftIGBTShortWarning : 28|1@1+ (1,0) [0|0] "" Vector__XXX
 SG_ PTC_failRightIGBTShortWarning : 29|1@1+ (1,0) [0|0] "" Vector__XXX
 SG_ PTC_failRightCurrentHVSensorWng : 30|1@1+ (1,0) [0|0] "" Vector__XXX
 SG_ PTC_failLeftCurrentHVSensorWng : 31|1@1+ (1,0) [0|0] "" Vector__XXX
 SG_ PTC_igbt15V : 56|8@1+ (0.25,0) [0|0] "" Vector__XXX

BO_ 776 OCS1P_status: 8 Vector__XXX
 SG_ OCS1P_occupantClassification : 0|8@1+ (1,0) [0|0] "" Vector__XXX
 SG_ OCS1P_occupantClassificationQF : 8|1@1+ (1,0) [0|0] "" Vector__XXX
 SG_ OCS1P_occupiedState : 9|2@1+ (1,0) [0|0] "" Vector__XXX
 SG_ OCS1P_triggerSnapshot : 11|5@1+ (1,0) [0|0] "" Vector__XXX
 SG_ OCS1P_occupantClassificationRaw : 16|3@1+ (1,0) [0|0] "" Vector__XXX
 SG_ OCS1P_occupantClassificationSelf : 19|3@1+ (1,0) [0|0] "" Vector__XXX
 SG_ OCS1P_occupantClassificationRawCap : 22|3@1+ (1,0) [0|0] "" Vector__XXX
 SG_ OCS1P_occupantClassificationCap : 25|3@1+ (1,0) [0|0] "" Vector__XXX
 SG_ OCS1P_classificationHeld : 30|1@1+ (1,0) [0|0] "" Vector__XXX
 SG_ OCS1P_cushionStable : 31|1@1+ (1,0) [0|0] "" Vector__XXX
 SG_ OCS1P_classificationExtHold : 32|1@1+ (1,0) [0|0] "" Vector__XXX
 SG_ OCS1P_classificationHoldState : 33|3@1+ (1,0) [0|0] "" Vector__XXX
 SG_ OCS1P_classificationVariant : 36|3@1+ (1,0) [0|0] "" Vector__XXX
 SG_ OCS1P_sandwichDisabled : 39|1@1+ (1,0) [0|0] "" Vector__XXX
 SG_ OCS1P_noSandwichType : 40|2@1+ (1,0) [0|0] "" Vector__XXX
 SG_ OCS1P_sandwichBoundaryType : 42|1@1+ (1,0) [0|0] "" Vector__XXX
 SG_ OCS1P_sbrBoundaryType : 43|1@1+ (1,0) [0|0] "" Vector__XXX
 SG_ OCS1P_occupiedStateCap : 45|2@1+ (1,0) [0|0] "" Vector__XXX
 SG_ OCS1P_seatbackStable : 47|1@1+ (1,0) [0|0] "" Vector__XXX
 SG_ OCS1P_sandwichStable : 48|1@1+ (1,0) [0|0] "" Vector__XXX
 SG_ OCS1P_cushionStableCap : 49|1@1+ (1,0) [0|0] "" Vector__XXX
 SG_ OCS1P_seatbackStableCap : 50|1@1+ (1,0) [0|0] "" Vector__XXX
 SG_ OCS1P_classificationHeldCap : 51|1@1+ (1,0) [0|0] "" Vector__XXX
 SG_ OCS1P_statusCounter : 52|4@1+ (1,0) [0|0] "" Vector__XXX
 SG_ OCS1P_statusChecksum : 56|8@1+ (1,0) [0|0] "" Vector__XXX

BO_ 777 PMF_alertMatrix2: 8 Vector__XXX
 SG_ PMF_a092_xtalOscillator : 27|1@1+ (1,0) [0|0] "" Vector__XXX
 SG_ PMF_a094_safetyICWarn : 29|1@1+ (1,0) [0|0] "" Vector__XXX
 SG_ PMF_a095_safetyICFault : 30|1@1+ (1,0) [0|0] "" Vector__XXX
 SG_ PMF_a096_safetyICDebug : 31|1@1+ (1,0) [0|0] "" Vector__XXX
 SG_ PMF_a097_lowFlowAlmostTripped : 32|1@1+ (1,0) [0|0] "" Vector__XXX
 SG_ PMF_a111_unintendedResetCausedNeutral : 46|1@1+ (1,0) [0|0] "" Vector__XXX

BO_ 784 HVP_info: 8 Vector__XXX
 SG_ HVP_infoIndex M : 0|8@1+ (1,0) [0|0] "" Vector__XXX
 SG_ HVP_appGitHash m17 : 8|56@1+ (1,0) [0|0] "" Vector__XXX
 SG_ HVP_bootGitHash m18 : 8|56@1+ (1,0) [0|0] "" Vector__XXX
 SG_ HVP_bootUdsProtoVersion m20 : 8|8@1+ (1,0) [0|0] "" Vector__XXX
 SG_ HVP_buildType m10 : 8|3@1+ (1,0) [0|0] "" Vector__XXX
 SG_ HVP_platformType m13 : 8|8@1+ (1,0) [0|0] "" Vector__XXX
 SG_ HVP_buildConfigId m10 : 16|16@1+ (1,0) [0|0] "" Vector__XXX
 SG_ HVP_pcbaId m11 : 16|8@1+ (1,0) [0|0] "" Vector__XXX
 SG_ HVP_assemblyId m11 : 24|8@1+ (1,0) [0|0] "" Vector__XXX
 SG_ HVP_appCrc m13 : 32|32@1+ (1,0) [0|0] "" Vector__XXX
 SG_ HVP_bootCrc m20 : 32|32@1+ (1,0) [0|0] "" Vector__XXX
 SG_ HVP_hardwareId m10 : 32|16@1+ (1,0) [0|0] "" Vector__XXX
 SG_ HVP_usageId m11 : 32|16@1+ (1,0) [0|0] "" Vector__XXX
 SG_ HVP_componentId m10 : 48|16@1+ (1,0) [0|0] "" Vector__XXX
 SG_ HVP_subUsageId m11 : 48|16@1+ (1,0) [0|0] "" Vector__XXX

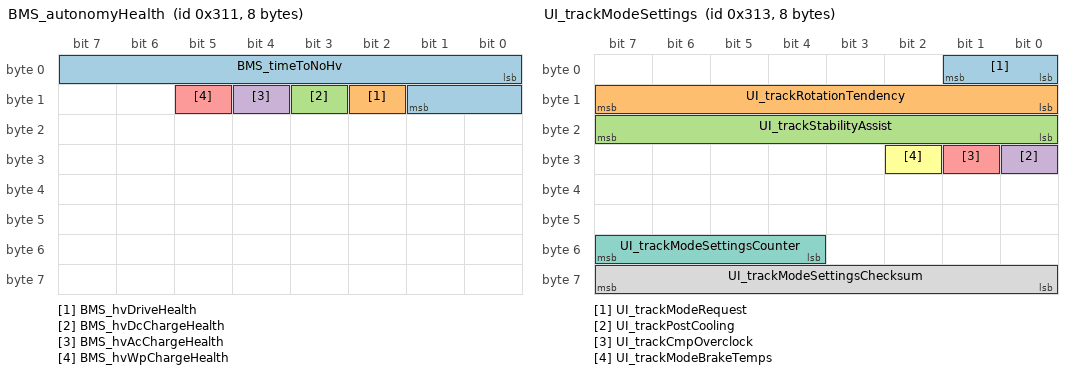
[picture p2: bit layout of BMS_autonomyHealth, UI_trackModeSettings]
BO_ 785 BMS_autonomyHealth: 8 Vector__XXX
 SG_ BMS_timeToNoHv : 0|10@1+ (1,0) [0|0] "" Vector__XXX
 SG_ BMS_hvDriveHealth : 10|1@1+ (1,0) [0|0] "" Vector__XXX
 SG_ BMS_hvDcChargeHealth : 11|1@1+ (1,0) [0|0] "" Vector__XXX
 SG_ BMS_hvAcChargeHealth : 12|1@1+ (1,0) [0|0] "" Vector__XXX
 SG_ BMS_hvWpChargeHealth : 13|1@1+ (1,0) [0|0] "" Vector__XXX

BO_ 786 BMS_thermalStatus: 8 Vector__XXX
 SG_ BMS_thermalStatusMultiplexer M : 0|2@1+ (1,0) [0|0] "" Vector__XXX
 SG_ BMS_coldStagnationLimit m1 : 2|9@1+ (0.25,-25) [0|0] "" Vector__XXX
 SG_ BMS_inletActiveCoolTargetT m0 : 2|9@1+ (0.25,-25) [0|0] "" Vector__XXX
 SG_ BMS_hotStagnationLimit m1 : 11|9@1+ (0.25,-25) [0|0] "" Vector__XXX
 SG_ BMS_inletPassiveTargetT m0 : 11|9@1+ (0.25,-25) [0|0] "" Vector__XXX
 SG_ BMS_hotCellTempLimit m1 : 20|9@1+ (0.25,-25) [0|0] "" Vector__XXX
 SG_ BMS_inletActiveHeatTargetT m0 : 20|9@1+ (0.25,-25) [0|0] "" Vector__XXX
 SG_ BMS_i2tDeratingEnabled m1 : 29|1@1+ (1,0) [0|0] "" Vector__XXX
 SG_ BMS_requestDischarge m0 : 29|1@1+ (1,0) [0|0] "" Vector__XXX
 SG_ BMS_activeHeatingWorthwhile m0 : 30|1@1+ (1,0) [0|0] "" Vector__XXX
 SG_ BMS_pcsNoFlowRequest m0 : 31|1@1+ (1,0) [0|0] "" Vector__XXX
 SG_ BMS_activeCoolCellReferenceT m1 : 32|9@1+ (0.25,-25) [0|0] "" Vector__XXX
 SG_ BMS_minPackTemperature m0 : 32|10@1+ (0.2,-40) [0|0] "" Vector__XXX
 SG_ BMS_activeHeatCellTargetT m1 : 41|9@1+ (0.25,-25) [0|0] "" Vector__XXX
 SG_ BMS_noFlowRequest m0 : 42|1@1+ (1,0) [0|0] "" Vector__XXX
 SG_ BMS_maxPackTemperature m0 : 43|11@1+ (0.1,-40) [0|0] "" Vector__XXX
 SG_ BMS_powerDissipation m1 : 50|10@1+ (0.02,0) [0|0] "" Vector__XXX
 SG_ BMS_flowRequest m0 : 56|8@1+ (0.25,0) [0|0] "" Vector__XXX

BO_ 787 UI_trackModeSettings: 8 Vector__XXX
 SG_ UI_trackModeRequest : 0|2@1+ (1,0) [0|0] "" Vector__XXX
 SG_ UI_trackRotationTendency : 8|8@1+ (0.5,0) [0|0] "" Vector__XXX
 SG_ UI_trackStabilityAssist : 16|8@1+ (0.5,0) [0|0] "" Vector__XXX
 SG_ UI_trackPostCooling : 24|1@1+ (1,0) [0|0] "" Vector__XXX
 SG_ UI_trackCmpOverclock : 25|1@1+ (1,0) [0|0] "" Vector__XXX
 SG_ UI_trackModeBrakeTemps : 26|1@1+ (1,0) [0|0] "" Vector__XXX
 SG_ UI_trackModeSettingsCounter : 52|4@1+ (1,0) [0|0] "" Vector__XXX
 SG_ UI_trackModeSettingsChecksum : 56|8@1+ (1,0) [0|0] "" Vector__XXX

BO_ 789 DIR_temperature: 8 Vector__XXX
 SG_ DIR_tempIndex M : 0|3@1+ (1,0) [0|0] "" Vector__XXX
 SG_ DIR_currentWeibullMiles m3 : 3|16@1+ (8,0) [0|0] "" Vector__XXX
 SG_ DIR_inverterTQF m0 : 3|2@1+ (1,0) [0|0] "" Vector__XXX
 SG_ DIR_fluidInTemp m2 : 8|8@1+ (1,-40) [0|0] "" Vector__XXX
 SG_ DIR_heatsink1Temp m1 : 8|8@1+ (1,-40) [0|0] "" Vector__XXX
 SG_ DIR_initialBurnInVehicleOdometer m4 : 8|32@1+ (0.001,0) [0|0] "" Vector__XXX
 SG_ DIR_pcbT m0 : 8|8@1+ (1,-40) [0|0] "" Vector__XXX
 SG_ DIR_heatsink2Temp m1 : 16|8@1+ (1,-40) [0|0] "" Vector__XXX
 SG_ DIR_inverterT m0 : 16|8@1+ (1,-40) [0|0] "" Vector__XXX
 SG_ DIR_normalFetBurnIn m2 : 16|16@1+ (0.00763,0) [0|0] "" Vector__XXX
 SG_ DIR_endOfServiceWeibullMiles m3 : 19|16@1+ (8,0) [0|0] "" Vector__XXX
 SG_ DIR_heatsink3Temp m1 : 24|8@1+ (1,-40) [0|0] "" Vector__XXX
 SG_ DIR_statorT m0 : 24|8@1+ (1,-40) [0|0] "" Vector__XXX
 SG_ DIR_additionalFetBurnIn m2 : 32|16@1+ (0.00763,0) [0|0] "" Vector__XXX
 SG_ DIR_dcCapT m0 : 32|8@1+ (1,-40) [0|0] "" Vector__XXX
 SG_ DIR_pcbTemp2 m1 : 32|8@1+ (1,-40) [0|0] "" Vector__XXX
 SG_ DIR_burnInDamageRatio m3 : 35|9@1+ (0.01,0) [0|0] "" Vector__XXX
 SG_ DIR_heatsinkT m0 : 40|8@1+ (1,-40) [0|0] "" Vector__XXX
 SG_ DIR_inverterHS2Est m4 : 40|8@1+ (1,-40) [0|0] "" Vector__XXX
 SG_ DIR_junctionTemp m1 : 40|8@1+ (1,-40) [0|0] "" Vector__XXX
 SG_ DIR_inverterSensorEst m3 : 44|8@1+ (1,-40) [0|0] "" Vector__XXX
 SG_ DIR_TPak1Temp m1 : 48|8@1+ (1,-40) [0|0] "" Vector__XXX
 SG_ DIR_inverterInletEst m4 : 48|8@1+ (1,-40) [0|0] "" Vector__XXX
 SG_ DIR_inverterTpct m0 : 48|8@1+ (0.4,0) [0|0] "" Vector__XXX
 SG_ DIR_inverterHS1Est m3 : 52|8@1+ (1,-40) [0|0] "" Vector__XXX
 SG_ DIR_TPak2Temp m1 : 56|8@1+ (1,-40) [0|0] "" Vector__XXX
 SG_ DIR_statorHousingTemp m4 : 56|8@1+ (1,-40) [0|0] "" Vector__XXX
 SG_ DIR_statorTpct m0 : 56|8@1+ (0.4,0) [0|0] "" Vector__XXX

BO_ 790 PMF_info: 8 Vector__XXX
 SG_ PMF_infoIndex M : 0|8@1+ (1,0) [0|0] "" Vector__XXX
 SG_ PMF_appGitHash m17 : 8|56@1+ (1,0) [0|0] "" Vector__XXX
 SG_ PMF_bootGitHash m18 : 8|56@1+ (1,0) [0|0] "" Vector__XXX
 SG_ PMF_buildType m10 : 8|8@1+ (1,0) [0|0] "" Vector__XXX
 SG_ PMF_diNodeBuildType m21 : 8|8@1+ (1,0) [0|0] "" Vector__XXX
 SG_ PMF_platformTyp m19 : 8|8@1+ (1,0) [0|0] "" Vector__XXX
 SG_ PMF_udsProtocolVersion m20 : 8|8@1+ (1,0) [0|0] "" Vector__XXX
 SG_ PMF_buildConfigurationId m10 : 16|16@1+ (1,0) [0|0] "" Vector__XXX
 SG_ PMF_diNodeBuildConfigurationId m21 : 16|16@1+ (1,0) [0|0] "" Vector__XXX
 SG_ PMF_pcbaId m11 : 16|8@1+ (1,0) [0|0] "" Vector__XXX
 SG_ PMF_assemblyId m11 : 24|8@1+ (1,0) [0|0] "" Vector__XXX
 SG_ PMF_applicationCrc m13 : 32|32@1+ (1,0) [0|0] "" Vector__XXX
 SG_ PMF_bootloaderCrc m20 : 32|32@1+ (1,0) [0|0] "" Vector__XXX
 SG_ PMF_diNodeApplicationCrc m21 : 32|32@1+ (1,0) [0|0] "" Vector__XXX
 SG_ PMF_hardwareId m10 : 32|8@1+ (1,0) [0|0] "" Vector__XXX
 SG_ PMF_usageId m11 : 32|16@1+ (1,0) [0|0] "" Vector__XXX
 SG_ PMF_componentId m10 : 48|16@1+ (1,0) [0|0] "" Vector__XXX
 SG_ PMF_subUsageId m11 : 48|16@1+ (1,0) [0|0] "" Vector__XXX

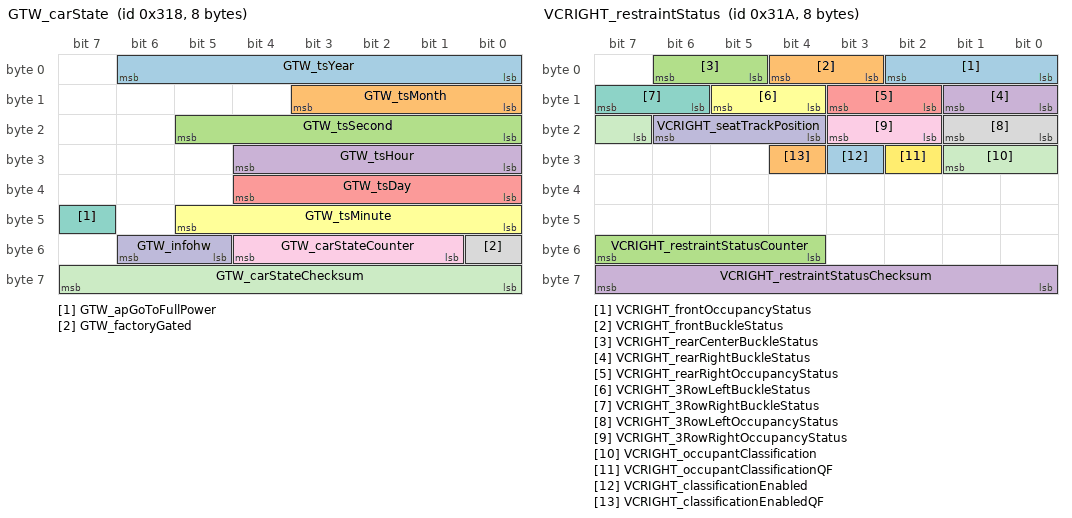
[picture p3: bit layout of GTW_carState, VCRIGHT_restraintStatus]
BO_ 792 GTW_carState: 8 Vector__XXX
 SG_ GTW_tsYear : 0|7@1+ (1,2000) [0|0] "" Vector__XXX
 SG_ GTW_tsMonth : 8|4@1+ (1,0) [0|0] "" Vector__XXX
 SG_ GTW_tsSecond : 16|6@1+ (1,0) [0|0] "" Vector__XXX
 SG_ GTW_tsHour : 24|5@1+ (1,0) [0|0] "" Vector__XXX
 SG_ GTW_tsDay : 32|5@1+ (1,0) [0|0] "" Vector__XXX
 SG_ GTW_tsMinute : 40|6@1+ (1,0) [0|0] "" Vector__XXX
 SG_ GTW_apGoToFullPower : 47|1@1+ (1,0) [0|0] "" Vector__XXX
 SG_ GTW_factoryGated : 48|1@1+ (1,0) [0|0] "" Vector__XXX
 SG_ GTW_carStateCounter : 49|4@1+ (1,0) [0|0] "" Vector__XXX
 SG_ GTW_infohw : 53|2@1+ (1,0) [0|0] "" Vector__XXX
 SG_ GTW_carStateChecksum : 56|8@1+ (1,0) [0|0] "" Vector__XXX

BO_ 793 VCSEC_info: 8 Vector__XXX
 SG_ VCSEC_infoIndex M : 0|8@1+ (1,0) [0|0] "" Vector__XXX
 SG_ VCSEC_infoAppGitHash m17 : 8|56@1+ (1,0) [0|0] "" Vector__XXX
 SG_ VCSEC_infoBootGitHash m18 : 8|56@1+ (1,0) [0|0] "" Vector__XXX
 SG_ VCSEC_infoBootUdsProtoVersion m20 : 8|16@1+ (1,0) [0|0] "" Vector__XXX
 SG_ VCSEC_infoBuildType m10 : 8|3@1+ (1,0) [0|0] "" Vector__XXX
 SG_ VCSEC_infoPcbaId m11 : 8|8@1+ (1,0) [0|0] "" Vector__XXX
 SG_ VCSEC_infoPlatformType m19 : 8|8@1+ (1,0) [0|0] "" Vector__XXX
 SG_ VCSEC_infoAssemblyId m11 : 16|8@1+ (1,0) [0|0] "" Vector__XXX
 SG_ VCSEC_infoBuildConfigId m10 : 16|16@1+ (1,0) [0|0] "" Vector__XXX
 SG_ VCSEC_infoBootCrc m20 : 24|32@1+ (1,0) [0|0] "" Vector__XXX
 SG_ VCSEC_infoAppCrc m13 : 32|32@1+ (1,0) [0|0] "" Vector__XXX
 SG_ VCSEC_infoHardwareId m10 : 32|16@1+ (1,0) [0|0] "" Vector__XXX
 SG_ VCSEC_infoSubcomponent1 m16 : 32|32@1+ (1,0) [0|0] "" Vector__XXX
 SG_ VCSEC_infoSubcomponent10 m37 : 32|32@1+ (1,0) [0|0] "" Vector__XXX
 SG_ VCSEC_infoSubcomponent11 m38 : 32|32@1+ (1,0) [0|0] "" Vector__XXX
 SG_ VCSEC_infoSubcomponent12 m39 : 32|32@1+ (1,0) [0|0] "" Vector__XXX
 SG_ VCSEC_infoSubcomponent13 m40 : 32|32@1+ (1,0) [0|0] "" Vector__XXX
 SG_ VCSEC_infoSubcomponent14 m41 : 32|32@1+ (1,0) [0|0] "" Vector__XXX
 SG_ VCSEC_infoSubcomponent2 m23 : 32|32@1+ (1,0) [0|0] "" Vector__XXX
 SG_ VCSEC_infoSubcomponent3 m24 : 32|32@1+ (1,0) [0|0] "" Vector__XXX
 SG_ VCSEC_infoSubcomponent4 m31 : 32|32@1+ (1,0) [0|0] "" Vector__XXX
 SG_ VCSEC_infoSubcomponent5 m32 : 32|32@1+ (1,0) [0|0] "" Vector__XXX
 SG_ VCSEC_infoSubcomponent6 m33 : 32|32@1+ (1,0) [0|0] "" Vector__XXX
 SG_ VCSEC_infoSubcomponent7 m34 : 32|32@1+ (1,0) [0|0] "" Vector__XXX
 SG_ VCSEC_infoSubcomponent8 m35 : 32|32@1+ (1,0) [0|0] "" Vector__XXX
 SG_ VCSEC_infoSubcomponent9 m36 : 32|32@1+ (1,0) [0|0] "" Vector__XXX
 SG_ VCSEC_infoUsageId m11 : 32|16@1+ (1,0) [0|0] "" Vector__XXX
 SG_ VCSEC_infoComponentId m10 : 48|16@1+ (1,0) [0|0] "" Vector__XXX
 SG_ VCSEC_infoSubUsageId m11 : 48|16@1+ (1,0) [0|0] "" Vector__XXX

BO_ 794 VCRIGHT_restraintStatus: 8 Vector__XXX
 SG_ VCRIGHT_frontOccupancyStatus : 0|3@1+ (1,0) [0|0] "" Vector__XXX
 SG_ VCRIGHT_frontBuckleStatus : 3|2@1+ (1,0) [0|0] "" Vector__XXX
 SG_ VCRIGHT_rearCenterBuckleStatus : 5|2@1+ (1,0) [0|0] "" Vector__XXX
 SG_ VCRIGHT_rearRightBuckleStatus : 8|2@1+ (1,0) [0|0] "" Vector__XXX
 SG_ VCRIGHT_rearRightOccupancyStatus : 10|2@1+ (1,0) [0|0] "" Vector__XXX
 SG_ VCRIGHT_3RowLeftBuckleStatus : 12|2@1+ (1,0) [0|0] "" Vector__XXX
 SG_ VCRIGHT_3RowRightBuckleStatus : 14|2@1+ (1,0) [0|0] "" Vector__XXX
 SG_ VCRIGHT_3RowLeftOccupancyStatus : 16|2@1+ (1,0) [0|0] "" Vector__XXX
 SG_ VCRIGHT_3RowRightOccupancyStatus : 18|2@1+ (1,0) [0|0] "" Vector__XXX
 SG_ VCRIGHT_seatTrackPosition : 20|3@1+ (1,0) [0|0] "" Vector__XXX
 SG_ VCRIGHT_occupantClassification : 23|3@1+ (1,0) [0|0] "" Vector__XXX
 SG_ VCRIGHT_occupantClassificationQF : 26|1@1+ (1,0) [0|0] "" Vector__XXX
 SG_ VCRIGHT_classificationEnabled : 27|1@1+ (1,0) [0|0] "" Vector__XXX
 SG_ VCRIGHT_classificationEnabledQF : 28|1@1+ (1,0) [0|0] "" Vector__XXX
 SG_ VCRIGHT_restraintStatusCounter : 52|4@1+ (1,0) [0|0] "" Vector__XXX
 SG_ VCRIGHT_restraintStatusChecksum : 56|8@1+ (1,0) [0|0] "" Vector__XXX

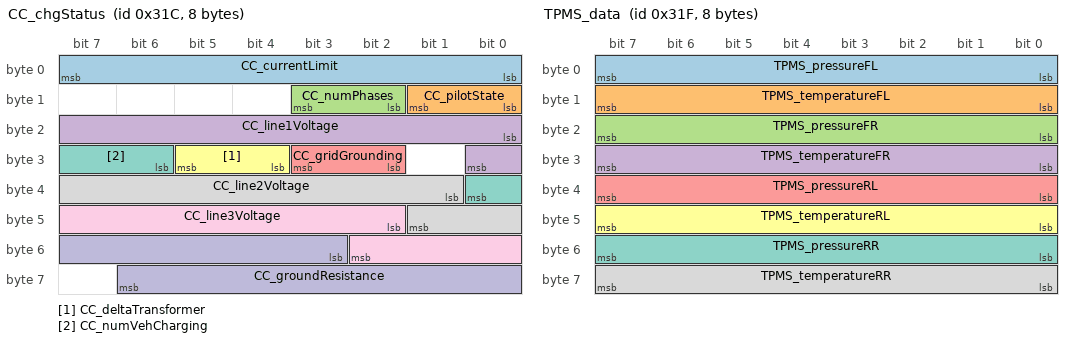
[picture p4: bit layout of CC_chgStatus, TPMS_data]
BO_ 796 CC_chgStatus: 8 Vector__XXX
 SG_ CC_currentLimit : 0|8@1+ (0.5,0) [0|0] "" Vector__XXX
 SG_ CC_pilotState : 8|2@1+ (1,0) [0|0] "" Vector__XXX
 SG_ CC_numPhases : 10|2@1+ (1,0) [0|0] "" Vector__XXX
 SG_ CC_line1Voltage : 16|9@1+ (1,0) [0|0] "" Vector__XXX
 SG_ CC_gridGrounding : 26|2@1+ (1,0) [0|0] "" Vector__XXX
 SG_ CC_deltaTransformer : 28|2@1+ (1,0) [0|0] "" Vector__XXX
 SG_ CC_numVehCharging : 30|3@1+ (1,0) [0|0] "" Vector__XXX
 SG_ CC_line2Voltage : 33|9@1+ (1,0) [0|0] "" Vector__XXX
 SG_ CC_line3Voltage : 42|9@1+ (1,0) [0|0] "" Vector__XXX
 SG_ CC_groundResistance : 51|12@1+ (1,0) [0|0] "" Vector__XXX

BO_ 797 CC_chgStatus2: 8 Vector__XXX
 SG_ CC_chgStatus2Index M : 0|8@1+ (1,0) [0|0] "" Vector__XXX
 SG_ CC_buttonState m0 : 8|1@1+ (1,0) [0|0] "" Vector__XXX
 SG_ EVSE_v2xSupport m0 : 9|2@1+ (1,0) [0|0] "" Vector__XXX
 SG_ EVSE_v2xHandshakeStart m0 : 12|1@1+ (1,0) [0|0] "" Vector__XXX

BO_ 798 CP_alertMatrix: 8 Vector__XXX
 SG_ CP_matrixIndex M : 0|4@1+ (1,0) [0|0] "" Vector__XXX
 SG_ CP_a001_canRx m0 : 4|1@1+ (1,0) [0|0] "" Vector__XXX
 SG_ CP_a061_uhfReceiverMIA m1 : 4|1@1+ (1,0) [0|0] "" Vector__XXX
 SG_ CP_a121_PLCRLY_lostCommsCP m2 : 4|1@1+ (1,0) [0|0] "" Vector__XXX
 SG_ CP_a002_canTx m0 : 5|1@1+ (1,0) [0|0] "" Vector__XXX
 SG_ CP_a062_scOutOfService m1 : 5|1@1+ (1,0) [0|0] "" Vector__XXX
 SG_ CP_a122_plcModemFailure m2 : 5|1@1+ (1,0) [0|0] "" Vector__XXX
 SG_ CP_a182_pncdCommsError m3 : 5|1@1+ (1,0) [0|0] "" Vector__XXX
 SG_ CP_a003_canError m0 : 6|1@1+ (1,0) [0|0] "" Vector__XXX
 SG_ CP_a063_scUpdateInProgress m1 : 6|1@1+ (1,0) [0|0] "" Vector__XXX
 SG_ CP_a123_latchPotIrrational m2 : 6|1@1+ (1,0) [0|0] "" Vector__XXX
 SG_ CP_a183_certManagerError m3 : 6|1@1+ (1,0) [0|0] "" Vector__XXX
 SG_ CP_a004_proximityRationality m0 : 7|1@1+ (1,0) [0|0] "" Vector__XXX
 SG_ CP_a064_superchargingBlocked m1 : 7|1@1+ (1,0) [0|0] "" Vector__XXX
 SG_ CP_a124_ivledFault m2 : 7|1@1+ (1,0) [0|0] "" Vector__XXX
 SG_ CP_a184_certChangeEvent m3 : 7|1@1+ (1,0) [0|0] "" Vector__XXX
 SG_ CP_a005_gbdcLiveDisconnect m0 : 8|1@1+ (1,0) [0|0] "" Vector__XXX
 SG_ CP_a065_selfTestFailed m1 : 8|1@1+ (1,0) [0|0] "" Vector__XXX
 SG_ CP_a125_unexpectedLVJuiceState m2 : 8|1@1+ (1,0) [0|0] "" Vector__XXX
 SG_ CP_a185_pncAuthRejection m3 : 8|1@1+ (1,0) [0|0] "" Vector__XXX
 SG_ CP_a006_lostCommsBMS m0 : 9|1@1+ (1,0) [0|0] "" Vector__XXX
 SG_ CP_a066_proxLatchedIdlePilot m1 : 9|1@1+ (1,0) [0|0] "" Vector__XXX
 SG_ CP_a126_wakeOnUhfFault m2 : 9|1@1+ (1,0) [0|0] "" Vector__XXX
 SG_ CP_a186_spiDmaFailure m3 : 9|1@1+ (1,0) [0|0] "" Vector__XXX
 SG_ CP_a007_watchdog m0 : 10|1@1+ (1,0) [0|0] "" Vector__XXX
 SG_ CP_a067_gbdcConnFault m1 : 10|1@1+ (1,0) [0|0] "" Vector__XXX
 SG_ CP_a127_lostCommsHVLINK m2 : 10|1@1+ (1,0) [0|0] "" Vector__XXX
 SG_ CP_a187_highStackUsage m3 : 10|1@1+ (1,0) [0|0] "" Vector__XXX
 SG_ CP_a008_memoryError m0 : 11|1@1+ (1,0) [0|0] "" Vector__XXX
 SG_ CP_a068_doorSensorMismatch m1 : 11|1@1+ (1,0) [0|0] "" Vector__XXX
 SG_ CP_a128_lostCommsVC m2 : 11|1@1+ (1,0) [0|0] "" Vector__XXX
 SG_ CP_a188_v2lEvseRequiresUpdate m3 : 11|1@1+ (1,0) [0|0] "" Vector__XXX
 SG_ CP_a009_coverOpenAllChgBlocked m0 : 12|1@1+ (1,0) [0|0] "" Vector__XXX
 SG_ CP_a069_doorInductiveSensorError m1 : 12|1@1+ (1,0) [0|0] "" Vector__XXX
 SG_ CP_a129_bldcDriverCommsFailed m2 : 12|1@1+ (1,0) [0|0] "" Vector__XXX
 SG_ CP_a189_resistivePresenceRationality m3 : 12|1@1+ (1,0) [0|0] "" Vector__XXX
 SG_ CP_a010_pilotRationality m0 : 13|1@1+ (1,0) [0|0] "" Vector__XXX
 SG_ CP_a070_doorInductiveSensorReset m1 : 13|1@1+ (1,0) [0|0] "" Vector__XXX
 SG_ CP_a130_bldcDriverCommsRecovered m2 : 13|1@1+ (1,0) [0|0] "" Vector__XXX
 SG_ CP_d190_backCoverCircuitIssue m3 : 13|1@1+ (1,0) [0|0] "" Vector__XXX
 SG_ CP_a011_eeprom m0 : 14|1@1+ (1,0) [0|0] "" Vector__XXX
 SG_ CP_a071_exiDecodeFailure m1 : 14|1@1+ (1,0) [0|0] "" Vector__XXX
 SG_ CP_a131_evseCommTimeout m2 : 14|1@1+ (1,0) [0|0] "" Vector__XXX
 SG_ CP_d191_latchConnectionIssue m3 : 14|1@1+ (1,0) [0|0] "" Vector__XXX
 SG_ CP_a012_ledDriver m0 : 15|1@1+ (1,0) [0|0] "" Vector__XXX
 SG_ CP_a072_v2gEvccTimeout m1 : 15|1@1+ (1,0) [0|0] "" Vector__XXX
 SG_ CP_a132_contractAuthTimeout m2 : 15|1@1+ (1,0) [0|0] "" Vector__XXX
 SG_ CP_d192_couplerTempHigh m3 : 15|1@1+ (1,0) [0|0] "" Vector__XXX
 SG_ CP_a013_lostCommsGTW m0 : 16|1@1+ (1,0) [0|0] "" Vector__XXX
 SG_ CP_a073_iecComboShutdown m1 : 16|1@1+ (1,0) [0|0] "" Vector__XXX
 SG_ CP_a133_proxNeverLatched m2 : 16|1@1+ (1,0) [0|0] "" Vector__XXX
 SG_ CP_d193_proximityCircuitErratic m3 : 16|1@1+ (1,0) [0|0] "" Vector__XXX
 SG_ CP_a014_lostCommsCHG m0 : 17|1@1+ (1,0) [0|0] "" Vector__XXX
 SG_ CP_a074_failedToEstablishV2gComm m1 : 17|1@1+ (1,0) [0|0] "" Vector__XXX
 SG_ CP_a134_plcModemNotExpected m2 : 17|1@1+ (1,0) [0|0] "" Vector__XXX
 SG_ CP_d194_proximityCircuitRangeIssue m3 : 17|1@1+ (1,0) [0|0] "" Vector__XXX
 SG_ CP_a015_apsVov m0 : 18|1@1+ (1,0) [0|0] "" Vector__XXX
 SG_ CP_a075_v2gCommsFailure m1 : 18|1@1+ (1,0) [0|0] "" Vector__XXX
 SG_ CP_a135_sdpAttemptsFailed m2 : 18|1@1+ (1,0) [0|0] "" Vector__XXX
 SG_ CP_d195_couplerLockActuatorIssue m3 : 18|1@1+ (1,0) [0|0] "" Vector__XXX
 SG_ CP_a016_apsVuv m0 : 19|1@1+ (1,0) [0|0] "" Vector__XXX
 SG_ CP_a076_LDC1612errorWatchdog m1 : 19|1@1+ (1,0) [0|0] "" Vector__XXX
 SG_ CP_a136_sdpSideReqFailed m2 : 19|1@1+ (1,0) [0|0] "" Vector__XXX
 SG_ CP_d196_doorActuatorPerformanceIssue m3 : 19|1@1+ (1,0) [0|0] "" Vector__XXX
 SG_ CP_a017_fiveVov m0 : 20|1@1+ (1,0) [0|0] "" Vector__XXX
 SG_ CP_a077_invalidMacAddress m1 : 20|1@1+ (1,0) [0|0] "" Vector__XXX
 SG_ CP_a137_plcForwardError m2 : 20|1@1+ (1,0) [0|0] "" Vector__XXX
 SG_ CP_d197_doorSensorCircuitErratic m3 : 20|1@1+ (1,0) [0|0] "" Vector__XXX
 SG_ CP_a018_fiveVuv m0 : 21|1@1+ (1,0) [0|0] "" Vector__XXX
 SG_ CP_a078_latchNotDisengagedCold m1 : 21|1@1+ (1,0) [0|0] "" Vector__XXX
 SG_ CP_a138_swcanCommsAcEvseFaulted m2 : 21|1@1+ (1,0) [0|0] "" Vector__XXX
 SG_ CP_d198_couplerTempSensorCircuitErratic m3 : 21|1@1+ (1,0) [0|0] "" Vector__XXX
 SG_ CP_a019_threeVov m0 : 22|1@1+ (1,0) [0|0] "" Vector__XXX
 SG_ CP_a079_cableNotSecuredCold m1 : 22|1@1+ (1,0) [0|0] "" Vector__XXX
 SG_ CP_a139_pilotFaulted m2 : 22|1@1+ (1,0) [0|0] "" Vector__XXX
 SG_ CP_d199_hardwareConfigMismatch m3 : 22|1@1+ (1,0) [0|0] "" Vector__XXX
 SG_ CP_a020_threeVuv m0 : 23|1@1+ (1,0) [0|0] "" Vector__XXX
 SG_ CP_a080_taskStackOverflow m1 : 23|1@1+ (1,0) [0|0] "" Vector__XXX
 SG_ CP_a140_superchargerFaulted m2 : 23|1@1+ (1,0) [0|0] "" Vector__XXX
 SG_ CP_d200_pilotCircuitIssue m3 : 23|1@1+ (1,0) [0|0] "" Vector__XXX
 SG_ CP_a021_zeroVov m0 : 24|1@1+ (1,0) [0|0] "" Vector__XXX
 SG_ CP_a081_swException m1 : 24|1@1+ (1,0) [0|0] "" Vector__XXX
 SG_ CP_a141_chademoAdapterFault m2 : 24|1@1+ (1,0) [0|0] "" Vector__XXX
 SG_ CP_a201_uhfDoorOpenRepeatedlyOverLimit m3 : 24|1@1+ (1,0) [0|0] "" Vector__XXX
 SG_ CP_a022_zeroVuv m0 : 25|1@1+ (1,0) [0|0] "" Vector__XXX
 SG_ CP_a082_powerOnReset m1 : 25|1@1+ (1,0) [0|0] "" Vector__XXX
 SG_ CP_a142_gbdcScConnFault m2 : 25|1@1+ (1,0) [0|0] "" Vector__XXX
 SG_ CP_a202_failedToEstablishV2gComm2 m3 : 25|1@1+ (1,0) [0|0] "" Vector__XXX
 SG_ CP_a023_gbdcSessionFailed m0 : 26|1@1+ (1,0) [0|0] "" Vector__XXX
 SG_ CP_a083_watchdogTraceData m1 : 26|1@1+ (1,0) [0|0] "" Vector__XXX
 SG_ CP_a143_unsupportedChargeAdapter m2 : 26|1@1+ (1,0) [0|0] "" Vector__XXX
 SG_ CP_a203_evseCommTimeout2 m3 : 26|1@1+ (1,0) [0|0] "" Vector__XXX
 SG_ CP_a024_ledsUC m0 : 27|1@1+ (1,0) [0|0] "" Vector__XXX
 SG_ CP_a084_proxPeDisconnected_gb m1 : 27|1@1+ (1,0) [0|0] "" Vector__XXX
 SG_ CP_a144_nvmInitFailed m2 : 27|1@1+ (1,0) [0|0] "" Vector__XXX
 SG_ CP_a204_sdpAttemptsFailed2 m3 : 27|1@1+ (1,0) [0|0] "" Vector__XXX
 SG_ CP_a025_ledsOC m0 : 28|1@1+ (1,0) [0|0] "" Vector__XXX
 SG_ CP_a085_dcPinTempFaulted m1 : 28|1@1+ (1,0) [0|0] "" Vector__XXX
 SG_ CP_a145_modemAppLoadFailedNA m2 : 28|1@1+ (1,0) [0|0] "" Vector__XXX
 SG_ CP_a205_doorPositionUndetectable m3 : 28|1@1+ (1,0) [0|0] "" Vector__XXX
 SG_ CP_a026_networkManagement m0 : 29|1@1+ (1,0) [0|0] "" Vector__XXX
 SG_ CP_a086_dcPinTempIrrational m1 : 29|1@1+ (1,0) [0|0] "" Vector__XXX
 SG_ CP_a146_ccsEvseMalfunction m2 : 29|1@1+ (1,0) [0|0] "" Vector__XXX
 SG_ CP_a027_doorSensorOutOfSpec m0 : 30|1@1+ (1,0) [0|0] "" Vector__XXX
 SG_ CP_a087_dcTempModelFault m1 : 30|1@1+ (1,0) [0|0] "" Vector__XXX
 SG_ CP_a147_inductiveRecoveredMia m2 : 30|1@1+ (1,0) [0|0] "" Vector__XXX
 SG_ CP_a028_insertEnableMismatch m0 : 31|1@1+ (1,0) [0|0] "" Vector__XXX
 SG_ CP_a088_dcTempModelDeviation m1 : 31|1@1+ (1,0) [0|0] "" Vector__XXX
 SG_ CP_a148_bldcTachFeedbackMia m2 : 31|1@1+ (1,0) [0|0] "" Vector__XXX
 SG_ CP_a029_doorClosedProxPilot m0 : 32|1@1+ (1,0) [0|0] "" Vector__XXX
 SG_ CP_a089_plcConfigMismatch m1 : 32|1@1+ (1,0) [0|0] "" Vector__XXX
 SG_ CP_a149_pilotPeriodInvalid m2 : 32|1@1+ (1,0) [0|0] "" Vector__XXX
 SG_ CP_a030_busOff m0 : 33|1@1+ (1,0) [0|0] "" Vector__XXX
 SG_ CP_a090_ccsEvseLowIso m1 : 33|1@1+ (1,0) [0|0] "" Vector__XXX
 SG_ CP_a150_railToggleTimeout m2 : 33|1@1+ (1,0) [0|0] "" Vector__XXX
 SG_ CP_a031_doorClosedCommandedOpen m0 : 34|1@1+ (1,0) [0|0] "" Vector__XXX
 SG_ CP_a091_wrongSuperchargerHandle m1 : 34|1@1+ (1,0) [0|0] "" Vector__XXX
 SG_ CP_a151_badPilotDiodeDetected m2 : 34|1@1+ (1,0) [0|0] "" Vector__XXX
 SG_ CP_a032_doorOpenExpectedClosed m0 : 35|1@1+ (1,0) [0|0] "" Vector__XXX
 SG_ CP_a092_modemAppLoadFailed m1 : 35|1@1+ (1,0) [0|0] "" Vector__XXX
 SG_ CP_a152_pilotEdgeDetectionFailed m2 : 35|1@1+ (1,0) [0|0] "" Vector__XXX
 SG_ CP_a033_spiOpen m0 : 36|1@1+ (1,0) [0|0] "" Vector__XXX
 SG_ CP_a093_modemLoadedWithReset m1 : 36|1@1+ (1,0) [0|0] "" Vector__XXX
 SG_ CP_a153_thermalAcLimitActive m2 : 36|1@1+ (1,0) [0|0] "" Vector__XXX
 SG_ CP_a034_calibrationIncomplete m0 : 37|1@1+ (1,0) [0|0] "" Vector__XXX
 SG_ CP_a094_inductiveResetSuccessful m1 : 37|1@1+ (1,0) [0|0] "" Vector__XXX
 SG_ CP_a154_acChargingStoppedOT m2 : 37|1@1+ (1,0) [0|0] "" Vector__XXX
 SG_ CP_a035_latchMovement_1 m0 : 38|1@1+ (1,0) [0|0] "" Vector__XXX
 SG_ CP_a095_thermalDcLimitActive m1 : 38|1@1+ (1,0) [0|0] "" Vector__XXX
 SG_ CP_a155_hallPresenceRationality m2 : 38|1@1+ (1,0) [0|0] "" Vector__XXX
 SG_ CP_a036_latchNotDisengaged m0 : 39|1@1+ (1,0) [0|0] "" Vector__XXX
 SG_ CP_a096_pilotWake m1 : 39|1@1+ (1,0) [0|0] "" Vector__XXX
 SG_ CP_a156_gbdcPrechargingConcern m2 : 39|1@1+ (1,0) [0|0] "" Vector__XXX
 SG_ CP_a037_latchNotEngaged m0 : 40|1@1+ (1,0) [0|0] "" Vector__XXX
 SG_ CP_a097_modeTransitionFailure m1 : 40|1@1+ (1,0) [0|0] "" Vector__XXX
 SG_ CP_a157_doorOpenRateLimiter m2 : 40|1@1+ (1,0) [0|0] "" Vector__XXX
 SG_ CP_a038_latchNotBlocking m0 : 41|1@1+ (1,0) [0|0] "" Vector__XXX
 SG_ CP_a098_proximityWake m1 : 41|1@1+ (1,0) [0|0] "" Vector__XXX
 SG_ CP_a158_doorCloseRateLimiter m2 : 41|1@1+ (1,0) [0|0] "" Vector__XXX
 SG_ CP_a039_latchMovement_2 m0 : 42|1@1+ (1,0) [0|0] "" Vector__XXX
 SG_ CP_a099_cableStateUnknown m1 : 42|1@1+ (1,0) [0|0] "" Vector__XXX
 SG_ CP_a159_swcanHealthCheckFailed m2 : 42|1@1+ (1,0) [0|0] "" Vector__XXX
 SG_ CP_a040_doNotUse m0 : 43|1@1+ (1,0) [0|0] "" Vector__XXX
 SG_ CP_a100_inletHarnessIdIrrational m1 : 43|1@1+ (1,0) [0|0] "" Vector__XXX
 SG_ CP_a160_latchDisengageInDcCharge m2 : 43|1@1+ (1,0) [0|0] "" Vector__XXX
 SG_ CP_a041_doorSensorUnplugged m0 : 44|1@1+ (1,0) [0|0] "" Vector__XXX
 SG_ CP_a101_wcFoldbackActive m1 : 44|1@1+ (1,0) [0|0] "" Vector__XXX
 SG_ CP_a161_badPilotDiodeDetectedCN m2 : 44|1@1+ (1,0) [0|0] "" Vector__XXX
 SG_ CP_a042_doorAssemblyBroken m0 : 45|1@1+ (1,0) [0|0] "" Vector__XXX
 SG_ CP_a102_wcOvertempFault m1 : 45|1@1+ (1,0) [0|0] "" Vector__XXX
 SG_ CP_a162_pilotEdgeDetectionFailedCN m2 : 45|1@1+ (1,0) [0|0] "" Vector__XXX
 SG_ CP_a043_doorPotIrrational m0 : 46|1@1+ (1,0) [0|0] "" Vector__XXX
 SG_ CP_a103_proximityPeDisconnected m1 : 46|1@1+ (1,0) [0|0] "" Vector__XXX
 SG_ CP_a163_coverOpenDcChgBlocked m2 : 46|1@1+ (1,0) [0|0] "" Vector__XXX
 SG_ CP_a044_lostCommsHVP m0 : 47|1@1+ (1,0) [0|0] "" Vector__XXX
 SG_ CP_a104_uhfResetSuccessful m1 : 47|1@1+ (1,0) [0|0] "" Vector__XXX
 SG_ CP_a164_latchRedisengageRequested m2 : 47|1@1+ (1,0) [0|0] "" Vector__XXX
 SG_ CP_a045_lostCommsVCSEC m0 : 48|1@1+ (1,0) [0|0] "" Vector__XXX
 SG_ CP_a105_hwUnableToSleep m1 : 48|1@1+ (1,0) [0|0] "" Vector__XXX
 SG_ CP_a165_proxWiggleDetected m2 : 48|1@1+ (1,0) [0|0] "" Vector__XXX
 SG_ CP_a046_lostCommsEVSE m0 : 49|1@1+ (1,0) [0|0] "" Vector__XXX
 SG_ CP_a106_uhfReceiverReset m1 : 49|1@1+ (1,0) [0|0] "" Vector__XXX
 SG_ CP_a166_faultLineMismatchDetected m2 : 49|1@1+ (1,0) [0|0] "" Vector__XXX
 SG_ CP_a047_lostCommsVCFRONT m0 : 50|1@1+ (1,0) [0|0] "" Vector__XXX
 SG_ CP_a107_chademoFoldbackActive m1 : 50|1@1+ (1,0) [0|0] "" Vector__XXX
 SG_ CP_a167_doorIdIrrational m2 : 50|1@1+ (1,0) [0|0] "" Vector__XXX
 SG_ CP_a048_lostCommsUI m0 : 51|1@1+ (1,0) [0|0] "" Vector__XXX
 SG_ CP_a108_chademoOvertempFault m1 : 51|1@1+ (1,0) [0|0] "" Vector__XXX
 SG_ CP_a168_pilotHSDFaulted m2 : 51|1@1+ (1,0) [0|0] "" Vector__XXX
 SG_ CP_a049_multipleCablesDetected m0 : 52|1@1+ (1,0) [0|0] "" Vector__XXX
 SG_ CP_a109_thermistorIrrational m1 : 52|1@1+ (1,0) [0|0] "" Vector__XXX
 SG_ CP_a050_latchNotConnected m0 : 53|1@1+ (1,0) [0|0] "" Vector__XXX
 SG_ CP_a110_thermalVelocityHigh m1 : 53|1@1+ (1,0) [0|0] "" Vector__XXX
 SG_ CP_a051_doorInductiveSensorMIA m0 : 54|1@1+ (1,0) [0|0] "" Vector__XXX
 SG_ CP_a111_inletHeaterUnableToHeat m1 : 54|1@1+ (1,0) [0|0] "" Vector__XXX
 SG_ CP_a052_chademoNotSupported m0 : 55|1@1+ (1,0) [0|0] "" Vector__XXX
 SG_ CP_a112_inletHeaterIrrationalTemperature m1 : 55|1@1+ (1,0) [0|0] "" Vector__XXX
 SG_ CP_a172_triggerOdin m2 : 55|1@1+ (1,0) [0|0] "" Vector__XXX
 SG_ CP_a053_proxLatchedNoPilot m0 : 56|1@1+ (1,0) [0|0] "" Vector__XXX
 SG_ CP_a113_inletHeaterShortCircuit m1 : 56|1@1+ (1,0) [0|0] "" Vector__XXX
 SG_ CP_a173_coverOpenAcChgBlocked m2 : 56|1@1+ (1,0) [0|0] "" Vector__XXX
 SG_ CP_a054_cableNotSecured m0 : 57|1@1+ (1,0) [0|0] "" Vector__XXX
 SG_ CP_a114_ccsEvseFailed m1 : 57|1@1+ (1,0) [0|0] "" Vector__XXX
 SG_ CP_a174_fwdedMsgLoadWarning m2 : 57|1@1+ (1,0) [0|0] "" Vector__XXX
 SG_ CP_a055_chargeStoppedNoPilot m0 : 58|1@1+ (1,0) [0|0] "" Vector__XXX
 SG_ CP_a115_unexpectedTcan1145State m1 : 58|1@1+ (1,0) [0|0] "" Vector__XXX
 SG_ CP_a175_fwdedMsgDropped m2 : 58|1@1+ (1,0) [0|0] "" Vector__XXX
 SG_ CP_a056_proxDisconnected m0 : 59|1@1+ (1,0) [0|0] "" Vector__XXX
 SG_ CP_a116_misconfigurationDetected m1 : 59|1@1+ (1,0) [0|0] "" Vector__XXX
 SG_ CP_a176_lostCommsV2l m2 : 59|1@1+ (1,0) [0|0] "" Vector__XXX
 SG_ CP_a057_ccs1AdapterBtnPress m0 : 60|1@1+ (1,0) [0|0] "" Vector__XXX
 SG_ CP_a117_inletHeaterUnableToRegulate m1 : 60|1@1+ (1,0) [0|0] "" Vector__XXX
 SG_ CP_a177_incompatibleV2lDeviceDetected m2 : 60|1@1+ (1,0) [0|0] "" Vector__XXX
 SG_ CP_a058_acChargeRetryPending m0 : 61|1@1+ (1,0) [0|0] "" Vector__XXX
 SG_ CP_a118_iecComboLockUp m1 : 61|1@1+ (1,0) [0|0] "" Vector__XXX
 SG_ CP_a178_v2xPlcCommsFault m2 : 61|1@1+ (1,0) [0|0] "" Vector__XXX
 SG_ CP_a059_swcanError m0 : 62|1@1+ (1,0) [0|0] "" Vector__XXX
 SG_ CP_a119_plcTransmitFailure m1 : 62|1@1+ (1,0) [0|0] "" Vector__XXX
 SG_ CP_a179_evseCommsTlsError m2 : 62|1@1+ (1,0) [0|0] "" Vector__XXX
 SG_ CP_a060_lostCommsPCS m0 : 63|1@1+ (1,0) [0|0] "" Vector__XXX
 SG_ CP_a120_comboAdapterFoldback m1 : 63|1@1+ (1,0) [0|0] "" Vector__XXX

BO_ 799 TPMS_data: 8 Vector__XXX
 SG_ TPMS_pressureFL : 0|8@1+ (0.025,0) [0|0] "" Vector__XXX
 SG_ TPMS_temperatureFL : 8|8@1+ (1,-40) [0|0] "" Vector__XXX
 SG_ TPMS_pressureFR : 16|8@1+ (0.025,0) [0|0] "" Vector__XXX
 SG_ TPMS_temperatureFR : 24|8@1+ (1,-40) [0|0] "" Vector__XXX
 SG_ TPMS_pressureRL : 32|8@1+ (0.025,0) [0|0] "" Vector__XXX
 SG_ TPMS_temperatureRL : 40|8@1+ (1,-40) [0|0] "" Vector__XXX
 SG_ TPMS_pressureRR : 48|8@1+ (0.025,0) [0|0] "" Vector__XXX
 SG_ TPMS_temperatureRR : 56|8@1+ (1,-40) [0|0] "" Vector__XXX

BO_ 800 BMS_alertMatrix: 8 Vector__XXX
 SG_ BMS_matrixIndex M : 0|4@1+ (1,0) [0|0] "" Vector__XXX
 SG_ BMS_a001_Pack_Config_Mismatch m0 : 4|1@1+ (1,0) [0|0] "" Vector__XXX
 SG_ BMS_a061_SW_BrickV_Change m1 : 4|1@1+ (1,0) [0|0] "" Vector__XXX
 SG_ BMS_a121_SW_NVRAM_Config_Error m2 : 4|1@1+ (1,0) [0|0] "" Vector__XXX
 SG_ BMS_a181_SW_Shunt_Over_Temperature m3 : 4|1@1+ (1,0) [0|0] "" Vector__XXX
 SG_ BMS_a002_Pack_Performance_Config_Mismatch m0 : 5|1@1+ (1,0) [0|0] "" Vector__XXX
 SG_ BMS_a062_SW_BrickV_Imbalance m1 : 5|1@1+ (1,0) [0|0] "" Vector__XXX
 SG_ BMS_a122_SW_BMS_Therm_Irrational m2 : 5|1@1+ (1,0) [0|0] "" Vector__XXX
 SG_ BMS_a182_LifeModel_NoCurrentLoss_Change m3 : 5|1@1+ (1,0) [0|0] "" Vector__XXX
 SG_ BMS_a003_SW_Pack_Birth_Date_Missing m0 : 6|1@1+ (1,0) [0|0] "" Vector__XXX
 SG_ BMS_a063_SW_ChargePort_Fault m1 : 6|1@1+ (1,0) [0|0] "" Vector__XXX
 SG_ BMS_a123_SW_Internal_Isolation m2 : 6|1@1+ (1,0) [0|0] "" Vector__XXX
 SG_ BMS_a183_LifeModel_StoDcrGrowth_Change m3 : 6|1@1+ (1,0) [0|0] "" Vector__XXX
 SG_ BMS_a004_Cal_Vs_Serial_Birth_Date_Mismatch m0 : 7|1@1+ (1,0) [0|0] "" Vector__XXX
 SG_ BMS_a064_SW_SOC_Imbalance m1 : 7|1@1+ (1,0) [0|0] "" Vector__XXX
 SG_ BMS_a124_Battery_Coolant_Flood m2 : 7|1@1+ (1,0) [0|0] "" Vector__XXX
 SG_ BMS_a184_LifeModel_CyclingLoss_Change m3 : 7|1@1+ (1,0) [0|0] "" Vector__XXX
 SG_ BMS_a065_SW_CAC_Imbalance m1 : 8|1@1+ (1,0) [0|0] "" Vector__XXX
 SG_ BMS_a185_LifeModel_CyclingDcrGrowth_Change m3 : 8|1@1+ (1,0) [0|0] "" Vector__XXX
 SG_ BMS_a066_SOC_Imbalance_Warning m1 : 9|1@1+ (1,0) [0|0] "" Vector__XXX
 SG_ BMS_a126_SW_Thermistor_Failure m2 : 9|1@1+ (1,0) [0|0] "" Vector__XXX
 SG_ BMS_a186_RippleHeatingChargeFault m3 : 9|1@1+ (1,0) [0|0] "" Vector__XXX
 SG_ BMS_a067_CAC_Imbalance_Limiting m1 : 10|1@1+ (1,0) [0|0] "" Vector__XXX
 SG_ BMS_a127_SW_shunt_SNA m2 : 10|1@1+ (1,0) [0|0] "" Vector__XXX
 SG_ BMS_a187_RippleHeatingEmergencyShutdown m3 : 10|1@1+ (1,0) [0|0] "" Vector__XXX
 SG_ BMS_a068_CAC_Imbalance_Limp m1 : 11|1@1+ (1,0) [0|0] "" Vector__XXX
 SG_ BMS_a128_SW_shunt_MIA m2 : 11|1@1+ (1,0) [0|0] "" Vector__XXX
 SG_ BMS_a188_PowershareChargeCurrentViolation m3 : 11|1@1+ (1,0) [0|0] "" Vector__XXX
 SG_ BMS_a069_SW_Low_Power m1 : 12|1@1+ (1,0) [0|0] "" Vector__XXX
 SG_ BMS_a129_SW_VSH_Failure m2 : 12|1@1+ (1,0) [0|0] "" Vector__XXX
 SG_ BMS_a189_PowershareDischargeCurrentViolation m3 : 12|1@1+ (1,0) [0|0] "" Vector__XXX
 SG_ BMS_a070_BrickV_Imbalance_Limiting m1 : 13|1@1+ (1,0) [0|0] "" Vector__XXX
 SG_ BMS_a130_IO_CAN_Error m2 : 13|1@1+ (1,0) [0|0] "" Vector__XXX
 SG_ BMS_a190_PowershareMaxVoltageViolation m3 : 13|1@1+ (1,0) [0|0] "" Vector__XXX
 SG_ BMS_a071_SW_SM_TransCon_Not_Met m1 : 14|1@1+ (1,0) [0|0] "" Vector__XXX
 SG_ BMS_a131_Bleed_FET_Failure m2 : 14|1@1+ (1,0) [0|0] "" Vector__XXX
 SG_ BMS_a191_PowershareMinVoltageViolation m3 : 14|1@1+ (1,0) [0|0] "" Vector__XXX
 SG_ BMS_a072_Module_Brick_Split m1 : 15|1@1+ (1,0) [0|0] "" Vector__XXX
 SG_ BMS_a132_HW_BMB_OTP_Uncorrctbl m2 : 15|1@1+ (1,0) [0|0] "" Vector__XXX
 SG_ BMS_a192_PowershareExternalChargeRegulation m3 : 15|1@1+ (1,0) [0|0] "" Vector__XXX
 SG_ BMS_a073_Unexpected_Loss_Of_Lv m1 : 16|1@1+ (1,0) [0|0] "" Vector__XXX
 SG_ BMS_a133_IO_CAN_Bus_Off m2 : 16|1@1+ (1,0) [0|0] "" Vector__XXX
 SG_ BMS_a193_PowershareMaxBrickVoltageViolation m3 : 16|1@1+ (1,0) [0|0] "" Vector__XXX
 SG_ BMS_a074_Max_Charge_Level_Reduced m1 : 17|1@1+ (1,0) [0|0] "" Vector__XXX
 SG_ BMS_a134_SW_Delayed_Ctr_Off m2 : 17|1@1+ (1,0) [0|0] "" Vector__XXX
 SG_ BMS_a194_PowershareLimitViolation m3 : 17|1@1+ (1,0) [0|0] "" Vector__XXX
 SG_ BMS_a075_SW_Chg_Disable_Failure m1 : 18|1@1+ (1,0) [0|0] "" Vector__XXX
 SG_ BMS_a135_HW_BMB_Diagnostics_Failure m2 : 18|1@1+ (1,0) [0|0] "" Vector__XXX
 SG_ BMS_a195_SW_DeltaTempOverThreshold m3 : 18|1@1+ (1,0) [0|0] "" Vector__XXX
 SG_ BMS_a016_Pack_Module_Id_Mismatch m0 : 19|1@1+ (1,0) [0|0] "" Vector__XXX
 SG_ BMS_a076_SW_Dch_While_Charging m1 : 19|1@1+ (1,0) [0|0] "" Vector__XXX
 SG_ BMS_a136_SW_Module_OT_Warning m2 : 19|1@1+ (1,0) [0|0] "" Vector__XXX
 SG_ BMS_a196_SW_PackVoltageUnderThreshold m3 : 19|1@1+ (1,0) [0|0] "" Vector__XXX
 SG_ BMS_a017_SW_Brick_OV m0 : 20|1@1+ (1,0) [0|0] "" Vector__XXX
 SG_ BMS_a077_SW_Charger_Regulation m1 : 20|1@1+ (1,0) [0|0] "" Vector__XXX
 SG_ BMS_a137_SW_Brick_UV_Warning m2 : 20|1@1+ (1,0) [0|0] "" Vector__XXX
 SG_ BMS_a197_SW_High_SOC_OV m3 : 20|1@1+ (1,0) [0|0] "" Vector__XXX
 SG_ BMS_d257_internalIsolationFault m4 : 20|1@1+ (1,0) [0|0] "" Vector__XXX
 SG_ BMS_a018_SW_Brick_UV m0 : 21|1@1+ (1,0) [0|0] "" Vector__XXX
 SG_ BMS_a078_Rapid_Dch_While_Charging m1 : 21|1@1+ (1,0) [0|0] "" Vector__XXX
 SG_ BMS_a138_SW_Brick_OV_Warning m2 : 21|1@1+ (1,0) [0|0] "" Vector__XXX
 SG_ BMS_a198_SW_SOC_Abrupt_Change m3 : 21|1@1+ (1,0) [0|0] "" Vector__XXX
 SG_ BMS_d258_externalIsolationFault m4 : 21|1@1+ (1,0) [0|0] "" Vector__XXX
 SG_ BMS_a019_SW_Module_OT m0 : 22|1@1+ (1,0) [0|0] "" Vector__XXX
 SG_ BMS_a079_Max_Charge_Level_Exceeded m1 : 22|1@1+ (1,0) [0|0] "" Vector__XXX
 SG_ BMS_a139_SW_DC_Link_V_Irrational m2 : 22|1@1+ (1,0) [0|0] "" Vector__XXX
 SG_ BMS_d259_highVoltageInterlockFailure m4 : 22|1@1+ (1,0) [0|0] "" Vector__XXX
 SG_ BMS_a020_SW_Brick_Instability m0 : 23|1@1+ (1,0) [0|0] "" Vector__XXX
 SG_ BMS_a080_SW_Pack_Ctr_Impedance m1 : 23|1@1+ (1,0) [0|0] "" Vector__XXX
 SG_ BMS_a140_HW_BMB_Status_Fault m2 : 23|1@1+ (1,0) [0|0] "" Vector__XXX
 SG_ BMS_d260_chargePortInterlockFailure m4 : 23|1@1+ (1,0) [0|0] "" Vector__XXX
 SG_ BMS_a021_SW_Dr_Limits_Regulation m0 : 24|1@1+ (1,0) [0|0] "" Vector__XXX
 SG_ BMS_a081_SW_Ctr_Close_Blocked m1 : 24|1@1+ (1,0) [0|0] "" Vector__XXX
 SG_ BMS_a141_SW_BMB_Status_Warning m2 : 24|1@1+ (1,0) [0|0] "" Vector__XXX
 SG_ BMS_d261_batteryPackCellVoltageHigh m4 : 24|1@1+ (1,0) [0|0] "" Vector__XXX
 SG_ BMS_a022_SW_Over_Current m0 : 25|1@1+ (1,0) [0|0] "" Vector__XXX
 SG_ BMS_a082_SW_Ctr_Force_Open m1 : 25|1@1+ (1,0) [0|0] "" Vector__XXX
 SG_ BMS_a142_SW_Isolation_Degradation m2 : 25|1@1+ (1,0) [0|0] "" Vector__XXX
 SG_ BMS_d262_batteryPackLowStateOfCharge m4 : 25|1@1+ (1,0) [0|0] "" Vector__XXX
 SG_ BMS_a023_SW_Stack_OV m0 : 26|1@1+ (1,0) [0|0] "" Vector__XXX
 SG_ BMS_a083_SW_Ctr_Close_Failure m1 : 26|1@1+ (1,0) [0|0] "" Vector__XXX
 SG_ BMS_a143_SW_CAC_Change m2 : 26|1@1+ (1,0) [0|0] "" Vector__XXX
 SG_ BMS_d263_batterySystemCurrentHigh m4 : 26|1@1+ (1,0) [0|0] "" Vector__XXX
 SG_ BMS_a024_SW_Islanded_Brick m0 : 27|1@1+ (1,0) [0|0] "" Vector__XXX
 SG_ BMS_a084_SW_Sleep_Wake_Aborted m1 : 27|1@1+ (1,0) [0|0] "" Vector__XXX
 SG_ BMS_a144_Hvp_Config_Mismatch m2 : 27|1@1+ (1,0) [0|0] "" Vector__XXX
 SG_ BMS_d264_invalidFirmwareConfig m4 : 27|1@1+ (1,0) [0|0] "" Vector__XXX
 SG_ BMS_a025_SW_PwrBalance_Anomaly m0 : 28|1@1+ (1,0) [0|0] "" Vector__XXX
 SG_ BMS_a085_SW_Pack_Contactor_Mismatch m1 : 28|1@1+ (1,0) [0|0] "" Vector__XXX
 SG_ BMS_a145_SW_SOC_Change m2 : 28|1@1+ (1,0) [0|0] "" Vector__XXX
 SG_ BMS_d265_replaceBatteryPack m4 : 28|1@1+ (1,0) [0|0] "" Vector__XXX
 SG_ BMS_a026_SW_HFCurrent_Anomaly m0 : 29|1@1+ (1,0) [0|0] "" Vector__XXX
 SG_ BMS_a086_SW_FC_Contactor_Mismatch m1 : 29|1@1+ (1,0) [0|0] "" Vector__XXX
 SG_ BMS_a146_SW_Brick_Overdischarged m2 : 29|1@1+ (1,0) [0|0] "" Vector__XXX
 SG_ BMS_d266_energyReserveVoltageLow m4 : 29|1@1+ (1,0) [0|0] "" Vector__XXX
 SG_ BMS_a027_SW_Repeated_Isolation_Failure_In_Drive m0 : 30|1@1+ (1,0) [0|0] "" Vector__XXX
 SG_ BMS_a087_SW_Feim_Test_Blocked m1 : 30|1@1+ (1,0) [0|0] "" Vector__XXX
 SG_ BMS_a147_SW_SOC_High_Ah_Error m2 : 30|1@1+ (1,0) [0|0] "" Vector__XXX
 SG_ BMS_d267_batteryPackCellVoltageSenseHarnessFailure m4 : 30|1@1+ (1,0) [0|0] "" Vector__XXX
 SG_ BMS_a028_ShuntAsicCurrentOffsetDeviation m0 : 31|1@1+ (1,0) [0|0] "" Vector__XXX
 SG_ BMS_a088_SW_VcFront_MIA_InDrive m1 : 31|1@1+ (1,0) [0|0] "" Vector__XXX
 SG_ BMS_a148_SW_Unsupported_BMB_ASIC_Type m2 : 31|1@1+ (1,0) [0|0] "" Vector__XXX
 SG_ BMS_d268_hvpInvalidFirmwareConfig m4 : 31|1@1+ (1,0) [0|0] "" Vector__XXX
 SG_ BMS_a029_dSoc_Limiting m0 : 32|1@1+ (1,0) [0|0] "" Vector__XXX
 SG_ BMS_a089_SW_VcFront_MIA m1 : 32|1@1+ (1,0) [0|0] "" Vector__XXX
 SG_ BMS_a149_SW_Missing_Config_Block m2 : 32|1@1+ (1,0) [0|0] "" Vector__XXX
 SG_ BMS_d269_highVoltageFuseABlown m4 : 32|1@1+ (1,0) [0|0] "" Vector__XXX
 SG_ BMS_a030_Impedance_Deviation m0 : 33|1@1+ (1,0) [0|0] "" Vector__XXX
 SG_ BMS_a090_SW_Gateway_MIA m1 : 33|1@1+ (1,0) [0|0] "" Vector__XXX
 SG_ BMS_a150_SW_Missing_Part_Number m2 : 33|1@1+ (1,0) [0|0] "" Vector__XXX
 SG_ BMS_d270_hvpCommsLost m4 : 33|1@1+ (1,0) [0|0] "" Vector__XXX
 SG_ BMS_a031_AlertsSetDuringSleep m0 : 34|1@1+ (1,0) [0|0] "" Vector__XXX
 SG_ BMS_a091_SW_ChargePort_MIA m1 : 34|1@1+ (1,0) [0|0] "" Vector__XXX
 SG_ BMS_a151_SW_external_isolation m2 : 34|1@1+ (1,0) [0|0] "" Vector__XXX
 SG_ BMS_d271_batteryPackSensorFailure m4 : 34|1@1+ (1,0) [0|0] "" Vector__XXX
 SG_ BMS_a032_VoltageLoss m0 : 35|1@1+ (1,0) [0|0] "" Vector__XXX
 SG_ BMS_a092_SW_ChargePort_Mia_On_Hvs m1 : 35|1@1+ (1,0) [0|0] "" Vector__XXX
 SG_ BMS_a152_Isolation_In_Dc_Charge m2 : 35|1@1+ (1,0) [0|0] "" Vector__XXX
 SG_ BMS_d272_batteryPackSensorCommsLost m4 : 35|1@1+ (1,0) [0|0] "" Vector__XXX
 SG_ BMS_a033_VoltageDeviation m0 : 36|1@1+ (1,0) [0|0] "" Vector__XXX
 SG_ BMS_a153_CpGridFormFault m2 : 36|1@1+ (1,0) [0|0] "" Vector__XXX
 SG_ BMS_d273_vcFrontCommsLost m4 : 36|1@1+ (1,0) [0|0] "" Vector__XXX
 SG_ BMS_a034_SW_Passive_Isolation m0 : 37|1@1+ (1,0) [0|0] "" Vector__XXX
 SG_ BMS_a094_SW_Drive_Inverter_MIA m1 : 37|1@1+ (1,0) [0|0] "" Vector__XXX
 SG_ BMS_a154_SW_Brick_OV_Warning_Stop_Charge m2 : 37|1@1+ (1,0) [0|0] "" Vector__XXX
 SG_ BMS_d274_packCurrentSensorACircuitFailure m4 : 37|1@1+ (1,0) [0|0] "" Vector__XXX
 SG_ BMS_a035_SW_Isolation m0 : 38|1@1+ (1,0) [0|0] "" Vector__XXX
 SG_ BMS_a095_SW_UI_MIA m1 : 38|1@1+ (1,0) [0|0] "" Vector__XXX
 SG_ BMS_a155_SW_Weak_short_impedence m2 : 38|1@1+ (1,0) [0|0] "" Vector__XXX
 SG_ BMS_d275_packPosContactorACircuitFailure m4 : 38|1@1+ (1,0) [0|0] "" Vector__XXX
 SG_ BMS_a036_SW_HvpHvilFault m0 : 39|1@1+ (1,0) [0|0] "" Vector__XXX
 SG_ BMS_a156_SW_BMB_Vref_bad m2 : 39|1@1+ (1,0) [0|0] "" Vector__XXX
 SG_ BMS_d276_packPosContactorAStuckClosed m4 : 39|1@1+ (1,0) [0|0] "" Vector__XXX
 SG_ BMS_a037_SW_Flood_Port_Open m0 : 40|1@1+ (1,0) [0|0] "" Vector__XXX
 SG_ BMS_a097_SW_BMB_Over_CAN_Communication m1 : 40|1@1+ (1,0) [0|0] "" Vector__XXX
 SG_ BMS_a157_SW_Hist_Update_Missed m2 : 40|1@1+ (1,0) [0|0] "" Vector__XXX
 SG_ BMS_d277_packNegContactorACircuitFailure m4 : 40|1@1+ (1,0) [0|0] "" Vector__XXX
 SG_ BMS_a098_SW_BMB_Data_Integrity_Loss m1 : 41|1@1+ (1,0) [0|0] "" Vector__XXX
 SG_ BMS_a158_SW_HVP_HVI_Comms m2 : 41|1@1+ (1,0) [0|0] "" Vector__XXX
 SG_ BMS_d278_packNegContactorAStuckClosed m4 : 41|1@1+ (1,0) [0|0] "" Vector__XXX
 SG_ BMS_a039_SW_DC_Link_Over_Voltage m0 : 42|1@1+ (1,0) [0|0] "" Vector__XXX
 SG_ BMS_a099_SW_BMB_Communication m1 : 42|1@1+ (1,0) [0|0] "" Vector__XXX
 SG_ BMS_a159_SW_HVP_ECU_Error m2 : 42|1@1+ (1,0) [0|0] "" Vector__XXX
 SG_ BMS_d279_fastChargePosContactorACircuitFailure m4 : 42|1@1+ (1,0) [0|0] "" Vector__XXX
 SG_ BMS_a040_SW_Watch_Dog_HW_Triggered m0 : 43|1@1+ (1,0) [0|0] "" Vector__XXX
 SG_ BMS_a100_ThermalEventSuspected m1 : 43|1@1+ (1,0) [0|0] "" Vector__XXX
 SG_ BMS_a160_SW_FC_Ctr_Clean_Failed m2 : 43|1@1+ (1,0) [0|0] "" Vector__XXX
 SG_ BMS_d280_fastChargePosContactorAStuckClosed m4 : 43|1@1+ (1,0) [0|0] "" Vector__XXX
 SG_ BMS_a041_SW_Destructive_Reset_Source m0 : 44|1@1+ (1,0) [0|0] "" Vector__XXX
 SG_ BMS_a161_SW_BMB_Vref_warning m2 : 44|1@1+ (1,0) [0|0] "" Vector__XXX
 SG_ BMS_d281_fastChargePosContactorAStuckOpen m4 : 44|1@1+ (1,0) [0|0] "" Vector__XXX
 SG_ BMS_a042_SW_MPU_Error m0 : 45|1@1+ (1,0) [0|0] "" Vector__XXX
 SG_ BMS_a162_SW_No_Power_For_Support m2 : 45|1@1+ (1,0) [0|0] "" Vector__XXX
 SG_ BMS_d282_fastChargeNegContactorACircuitFailure m4 : 45|1@1+ (1,0) [0|0] "" Vector__XXX
 SG_ BMS_a043_SW_Watch_Dog_Reset m0 : 46|1@1+ (1,0) [0|0] "" Vector__XXX
 SG_ BMS_d283_fastChargeNegContactorAStuckClosed m4 : 46|1@1+ (1,0) [0|0] "" Vector__XXX
 SG_ BMS_a044_SW_Assertion m0 : 47|1@1+ (1,0) [0|0] "" Vector__XXX
 SG_ BMS_a164_SW_Uncontrolled_Regen m2 : 47|1@1+ (1,0) [0|0] "" Vector__XXX
 SG_ BMS_d284_fastChargeNegContactorAStuckOpen m4 : 47|1@1+ (1,0) [0|0] "" Vector__XXX
 SG_ BMS_a045_SW_Exception m0 : 48|1@1+ (1,0) [0|0] "" Vector__XXX
 SG_ BMS_a105_SW_One_Module_Tsense m1 : 48|1@1+ (1,0) [0|0] "" Vector__XXX
 SG_ BMS_a165_SW_Pack_Partial_Weld m2 : 48|1@1+ (1,0) [0|0] "" Vector__XXX
 SG_ BMS_d285_packVoltageSensorACircuitFailure m4 : 48|1@1+ (1,0) [0|0] "" Vector__XXX
 SG_ BMS_a046_SW_Task_Stack_Usage m0 : 49|1@1+ (1,0) [0|0] "" Vector__XXX
 SG_ BMS_a106_SW_All_Module_Tsense m1 : 49|1@1+ (1,0) [0|0] "" Vector__XXX
 SG_ BMS_a166_SW_Pack_Full_Weld m2 : 49|1@1+ (1,0) [0|0] "" Vector__XXX
 SG_ BMS_d286_dcLinkVoltageHigh m4 : 49|1@1+ (1,0) [0|0] "" Vector__XXX
 SG_ BMS_a047_SW_Task_Stack_Overflow m0 : 50|1@1+ (1,0) [0|0] "" Vector__XXX
 SG_ BMS_a107_SW_Stack_Voltage_MIA m1 : 50|1@1+ (1,0) [0|0] "" Vector__XXX
 SG_ BMS_a167_SW_FC_Partial_Weld m2 : 50|1@1+ (1,0) [0|0] "" Vector__XXX
 SG_ BMS_d287_systemIsolationWarning m4 : 50|1@1+ (1,0) [0|0] "" Vector__XXX
 SG_ BMS_a048_SW_Watch_Dog_Warning m0 : 51|1@1+ (1,0) [0|0] "" Vector__XXX
 SG_ BMS_a108_SW_BMB_Device_OT m1 : 51|1@1+ (1,0) [0|0] "" Vector__XXX
 SG_ BMS_a168_SW_FC_Full_Weld m2 : 51|1@1+ (1,0) [0|0] "" Vector__XXX
 SG_ BMS_d288_batteryPackCellVoltageLow m4 : 51|1@1+ (1,0) [0|0] "" Vector__XXX
 SG_ BMS_a049_SW_Thermal_Event m0 : 52|1@1+ (1,0) [0|0] "" Vector__XXX
 SG_ BMS_a109_HW_BMB_Mute_Status_Mismatch m1 : 52|1@1+ (1,0) [0|0] "" Vector__XXX
 SG_ BMS_a169_SW_FC_Pack_Weld m2 : 52|1@1+ (1,0) [0|0] "" Vector__XXX
 SG_ BMS_d289_batteryPackAOverTemperature m4 : 52|1@1+ (1,0) [0|0] "" Vector__XXX
 SG_ BMS_a050_SW_Brick_Voltage_MIA m0 : 53|1@1+ (1,0) [0|0] "" Vector__XXX
 SG_ BMS_a110_LifeModel_AvgOffset_Change m1 : 53|1@1+ (1,0) [0|0] "" Vector__XXX
 SG_ BMS_a170_SW_Limp_Mode m2 : 53|1@1+ (1,0) [0|0] "" Vector__XXX
 SG_ BMS_d290_batteryPackTempSensorACircuitFailure m4 : 53|1@1+ (1,0) [0|0] "" Vector__XXX
 SG_ BMS_a051_SW_HVC_Vref_Bad m0 : 54|1@1+ (1,0) [0|0] "" Vector__XXX
 SG_ BMS_a111_LifeModel_Spread_Change m1 : 54|1@1+ (1,0) [0|0] "" Vector__XXX
 SG_ BMS_a171_SW_Stack_Voltage_Sense m2 : 54|1@1+ (1,0) [0|0] "" Vector__XXX
 SG_ BMS_a052_SW_PCS_MIA m0 : 55|1@1+ (1,0) [0|0] "" Vector__XXX
 SG_ BMS_a112_LifeModel_Discontinuity m1 : 55|1@1+ (1,0) [0|0] "" Vector__XXX
 SG_ BMS_a172_SW_Isolation_Failure_In_Drive_Warning m2 : 55|1@1+ (1,0) [0|0] "" Vector__XXX
 SG_ BMS_a173_FullPackEnergyDegraded m2 : 56|1@1+ (1,0) [0|0] "" Vector__XXX
 SG_ BMS_a054_SW_Ver_Supply_Fault m0 : 57|1@1+ (1,0) [0|0] "" Vector__XXX
 SG_ BMS_a174_SW_Charge_Failure m2 : 57|1@1+ (1,0) [0|0] "" Vector__XXX
 SG_ BMS_a055_SW_HvChain_Model_Fault m0 : 58|1@1+ (1,0) [0|0] "" Vector__XXX
 SG_ BMS_a115_Energy_Rubberbanding_Reset m1 : 58|1@1+ (1,0) [0|0] "" Vector__XXX
 SG_ BMS_a175_Charge_Failure_External m2 : 58|1@1+ (1,0) [0|0] "" Vector__XXX
 SG_ BMS_a056_SW_Standby_Supply_Fault m0 : 59|1@1+ (1,0) [0|0] "" Vector__XXX
 SG_ BMS_a176_SW_GracefulPowerOff m2 : 59|1@1+ (1,0) [0|0] "" Vector__XXX
 SG_ BMS_a057_SW_Bandolier_Model_Warning m0 : 60|1@1+ (1,0) [0|0] "" Vector__XXX
 SG_ BMS_a117_SW_Delta_SOC_Weak_Short m1 : 60|1@1+ (1,0) [0|0] "" Vector__XXX
 SG_ BMS_a177_SW_Energy_Buffer_Size m2 : 60|1@1+ (1,0) [0|0] "" Vector__XXX
 SG_ BMS_a058_SW_Bandolier_Model_Reset m0 : 61|1@1+ (1,0) [0|0] "" Vector__XXX
 SG_ BMS_a178_SW_Uncontrolled_Regen_PwrB m2 : 61|1@1+ (1,0) [0|0] "" Vector__XXX
 SG_ BMS_a059_SW_Pack_Voltage_Sensing m0 : 62|1@1+ (1,0) [0|0] "" Vector__XXX
 SG_ BMS_a119_Fast_Open_Vsh_Detected m1 : 62|1@1+ (1,0) [0|0] "" Vector__XXX
 SG_ BMS_a179_HvpGpoRequestActive m2 : 62|1@1+ (1,0) [0|0] "" Vector__XXX
 SG_ BMS_a060_SW_Leakage_Test_Failure m0 : 63|1@1+ (1,0) [0|0] "" Vector__XXX
 SG_ BMS_a180_SW_ECU_reset_blocked m2 : 63|1@1+ (1,0) [0|0] "" Vector__XXX

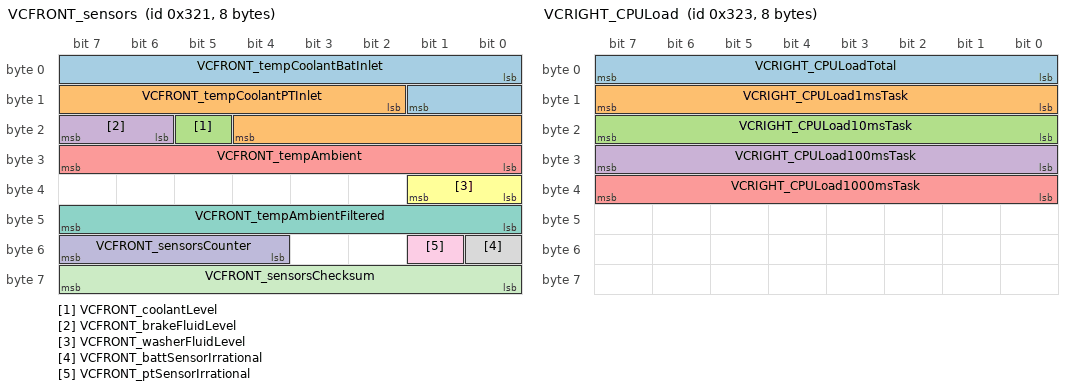
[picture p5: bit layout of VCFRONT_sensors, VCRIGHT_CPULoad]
BO_ 801 VCFRONT_sensors: 8 Vector__XXX
 SG_ VCFRONT_tempCoolantBatInlet : 0|10@1+ (0.125,-40) [0|0] "" Vector__XXX
 SG_ VCFRONT_tempCoolantPTInlet : 10|11@1+ (0.125,-40) [0|0] "" Vector__XXX
 SG_ VCFRONT_coolantLevel : 21|1@1+ (1,0) [0|0] "" Vector__XXX
 SG_ VCFRONT_brakeFluidLevel : 22|2@1+ (1,0) [0|0] "" Vector__XXX
 SG_ VCFRONT_tempAmbient : 24|8@1+ (0.5,-40) [0|0] "" Vector__XXX
 SG_ VCFRONT_washerFluidLevel : 32|2@1+ (1,0) [0|0] "" Vector__XXX
 SG_ VCFRONT_tempAmbientFiltered : 40|8@1+ (0.5,-40) [0|0] "" Vector__XXX
 SG_ VCFRONT_battSensorIrrational : 48|1@1+ (1,0) [0|0] "" Vector__XXX
 SG_ VCFRONT_ptSensorIrrational : 49|1@1+ (1,0) [0|0] "" Vector__XXX
 SG_ VCFRONT_sensorsCounter : 52|4@1+ (1,0) [0|0] "" Vector__XXX
 SG_ VCFRONT_sensorsChecksum : 56|8@1+ (1,0) [0|0] "" Vector__XXX

BO_ 803 VCRIGHT_CPULoad: 8 Vector__XXX
 SG_ VCRIGHT_CPULoadTotal : 0|8@1+ (1,0) [0|0] "" Vector__XXX
 SG_ VCRIGHT_CPULoad1msTask : 8|8@1+ (1,0) [0|0] "" Vector__XXX
 SG_ VCRIGHT_CPULoad10msTask : 16|8@1+ (1,0) [0|0] "" Vector__XXX
 SG_ VCRIGHT_CPULoad100msTask : 24|8@1+ (1,0) [0|0] "" Vector__XXX
 SG_ VCRIGHT_CPULoad1000msTask : 32|8@1+ (1,0) [0|0] "" Vector__XXX

BO_ 804 UI_gpsTime: 8 Vector__XXX
 SG_ UI_gpsTime : 0|64@1+ (1,0) [0|0] "" Vector__XXX

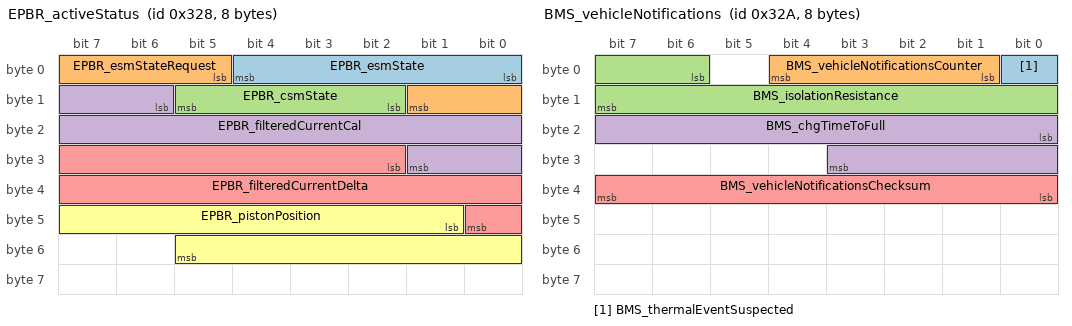
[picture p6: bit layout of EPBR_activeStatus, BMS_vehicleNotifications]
BO_ 808 EPBR_activeStatus: 8 Vector__XXX
 SG_ EPBR_esmState : 0|5@1+ (1,0) [0|0] "" Vector__XXX
 SG_ EPBR_esmStateRequest : 5|5@1+ (1,0) [0|0] "" Vector__XXX
 SG_ EPBR_csmState : 10|4@1+ (1,0) [0|0] "" Vector__XXX
 SG_ EPBR_filteredCurrentCal : 14|12@1+ (0.01,0) [0|0] "" Vector__XXX
 SG_ EPBR_filteredCurrentDelta : 26|15@1- (0.01,0) [0|0] "" Vector__XXX
 SG_ EPBR_pistonPosition : 41|13@1- (9.768009768009769,0) [0|0] "" Vector__XXX

BO_ 810 BMS_vehicleNotifications: 8 Vector__XXX
 SG_ BMS_thermalEventSuspected : 0|1@1+ (1,0) [0|0] "" Vector__XXX
 SG_ BMS_vehicleNotificationsCounter : 1|4@1+ (1,0) [0|0] "" Vector__XXX
 SG_ BMS_isolationResistance : 6|10@1+ (10,0) [0|0] "" Vector__XXX
 SG_ BMS_chgTimeToFull : 16|12@1+ (0.01666667,0) [0|0] "" Vector__XXX
 SG_ BMS_vehicleNotificationsChecksum : 32|8@1+ (1,0) [0|0] "" Vector__XXX

BO_ 812 CC_logData: 8 Vector__XXX
 SG_ CC_logIndex M : 0|8@1+ (1,0) [0|0] "" Vector__XXX
 SG_ CC_activeConnectorID m0 : 8|8@1+ (1,0) [0|0] "" Vector__XXX
 SG_ CC_conn1Current m1 : 8|8@1+ (0.5,0) [0|0] "" Vector__XXX
 SG_ CC_conn2Current m2 : 8|8@1+ (0.5,0) [0|0] "" Vector__XXX
 SG_ CC_conn3Current m3 : 8|8@1+ (0.5,0) [0|0] "" Vector__XXX
 SG_ CC_conn4Current m4 : 8|8@1+ (0.5,0) [0|0] "" Vector__XXX
 SG_ CC_lifetimeAlertCount m12 : 8|28@1+ (1,0) [0|0] "" Vector__XXX
 SG_ CC_lifetimeCtrCycles m11 : 8|28@1+ (1,0) [0|0] "" Vector__XXX
 SG_ CC_temperature1 m0 : 16|8@1- (1,88) [0|0] "" Vector__XXX
 SG_ CC_temperature2 m0 : 24|8@1- (1,88) [0|0] "" Vector__XXX
 SG_ CC_lifetimei2t m10 : 32|32@1+ (0.1,0) [0|0] "" Vector__XXX
 SG_ CC_temperature3 m0 : 32|8@1- (1,88) [0|0] "" Vector__XXX
 SG_ CC_lifetimeAvgStartupTemp m13 : 36|28@1- (0.1,0) [0|0] "" Vector__XXX
 SG_ CC_lifetimeCtrCyclesLoaded m11 : 36|28@1+ (1,0) [0|0] "" Vector__XXX
 SG_ CC_lifetimeThermalFoldbacks m12 : 36|28@1+ (1,0) [0|0] "" Vector__XXX
 SG_ CC_contactor1Closed m0 : 40|2@1+ (1,0) [0|0] "" Vector__XXX
 SG_ CC_contactor2Closed m0 : 42|2@1+ (1,0) [0|0] "" Vector__XXX
 SG_ CC_temperature4 m0 : 44|8@1- (1,88) [0|0] "" Vector__XXX

BO_ 815 SCM_alertMatrix1: 8 Vector__XXX
 SG_ SCM_a027_externalIsolationLow : 26|1@1+ (1,0) [0|0] "" Vector__XXX
 SG_ SCM_a044_proximityRationality : 43|1@1+ (1,0) [0|0] "" Vector__XXX

BO_ 816 SCCM_info: 8 Vector__XXX
 SG_ SCCM_infoIndex M : 0|8@1+ (1,0) [0|0] "" Vector__XXX
 SG_ SCCM_infoAppSvnHash m17 : 8|56@1+ (1,0) [0|0] "" Vector__XXX
 SG_ SCCM_infoBootSvnHash m18 : 8|56@1+ (1,0) [0|0] "" Vector__XXX
 SG_ SCCM_infoBootSvnRev m14 : 8|24@1+ (1,0) [0|0] "" Vector__XXX
 SG_ SCCM_infoBuildType m10 : 8|8@1+ (1,0) [0|0] "" Vector__XXX
 SG_ SCCM_infoPlatformType m13 : 8|8@1+ (1,0) [0|0] "" Vector__XXX
 SG_ SCCM_infoUdsProtoVersion m20 : 8|8@1+ (1,0) [0|0] "" Vector__XXX
 SG_ SCCM_infoBuildConfigId m10 : 16|16@1+ (1,0) [0|0] "" Vector__XXX
 SG_ SCCM_infoPcbaId m11 : 16|8@1+ (1,0) [0|0] "" Vector__XXX
 SG_ SCCM_infoSubcomponent1Version m16 : 16|32@1+ (1,0) [0|0] "" Vector__XXX
 SG_ SCCM_infoAssemblyId m11 : 24|8@1+ (1,0) [0|0] "" Vector__XXX
 SG_ SCCM_infoBootCrc m20 : 32|32@1+ (1,0) [0|0] "" Vector__XXX
 SG_ SCCM_infoBootSvnUrlHash m14 : 32|32@1+ (1,0) [0|0] "" Vector__XXX
 SG_ SCCM_infoHardwareId m10 : 32|16@1+ (1,0) [0|0] "" Vector__XXX
 SG_ SCCM_infoUsageId m11 : 32|16@1+ (1,0) [0|0] "" Vector__XXX
 SG_ SCCM_infoAppCrc m13 : 39|32@0+ (1,0) [0|0] "" Vector__XXX
 SG_ SCCM_infoComponentId m10 : 48|16@1+ (1,0) [0|0] "" Vector__XXX
 SG_ SCCM_infoSubUsageId m11 : 48|16@1+ (1,0) [0|0] "" Vector__XXX

BO_ 818 BMS_bmbMinMax: 8 Vector__XXX
 SG_ BMS_bmbMinMaxMultiplexer M : 0|2@1+ (1,0) [0|0] "" Vector__XXX
 SG_ BMS_brickVoltageMax m1 : 2|12@1+ (0.002,0) [0|0] "" Vector__XXX
 SG_ BMS_thermistorNumTMin m0 : 2|4@1+ (1,0) [0|0] "" Vector__XXX
 SG_ BMS_thermistorNumTMax m0 : 8|4@1+ (1,0) [0|0] "" Vector__XXX
 SG_ BMS_brickVoltageMin m1 : 16|12@1+ (0.002,0) [0|0] "" Vector__XXX
 SG_ BMS_thermistorTMax m0 : 16|8@1+ (0.5,-40) [0|0] "" Vector__XXX
 SG_ BMS_thermistorTMin m0 : 24|8@1+ (0.5,-40) [0|0] "" Vector__XXX
 SG_ BMS_brickNumVoltageMax m1 : 32|7@1+ (1,1) [0|0] "" Vector__XXX
 SG_ BMS_thermistorTAvg m0 : 32|8@1+ (0.5,-40) [0|0] "" Vector__XXX
 SG_ BMS_brickNumVoltageMin m1 : 40|7@1+ (1,1) [0|0] "" Vector__XXX

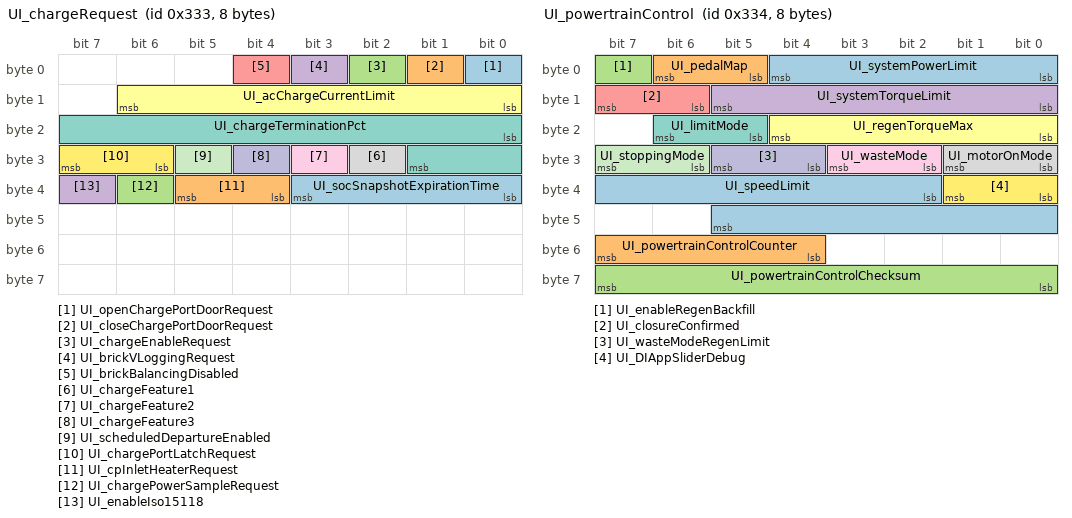
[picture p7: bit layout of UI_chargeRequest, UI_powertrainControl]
BO_ 819 UI_chargeRequest: 8 Vector__XXX
 SG_ UI_openChargePortDoorRequest : 0|1@1+ (1,0) [0|0] "" Vector__XXX
 SG_ UI_closeChargePortDoorRequest : 1|1@1+ (1,0) [0|0] "" Vector__XXX
 SG_ UI_chargeEnableRequest : 2|1@1+ (1,0) [0|0] "" Vector__XXX
 SG_ UI_brickVLoggingRequest : 3|1@1+ (1,0) [0|0] "" Vector__XXX
 SG_ UI_brickBalancingDisabled : 4|1@1+ (1,0) [0|0] "" Vector__XXX
 SG_ UI_acChargeCurrentLimit : 8|7@1+ (1,0) [0|0] "" Vector__XXX
 SG_ UI_chargeTerminationPct : 16|10@1+ (0.1,0) [0|0] "" Vector__XXX
 SG_ UI_chargeFeature1 : 26|1@1+ (1,0) [0|0] "" Vector__XXX
 SG_ UI_chargeFeature2 : 27|1@1+ (1,0) [0|0] "" Vector__XXX
 SG_ UI_chargeFeature3 : 28|1@1+ (1,0) [0|0] "" Vector__XXX
 SG_ UI_scheduledDepartureEnabled : 29|1@1+ (1,0) [0|0] "" Vector__XXX
 SG_ UI_chargePortLatchRequest : 30|2@1+ (1,0) [0|0] "" Vector__XXX
 SG_ UI_socSnapshotExpirationTime : 32|4@1+ (2,2) [0|0] "" Vector__XXX
 SG_ UI_cpInletHeaterRequest : 36|2@1+ (1,0) [0|0] "" Vector__XXX
 SG_ UI_chargePowerSampleRequest : 38|1@1+ (1,0) [0|0] "" Vector__XXX
 SG_ UI_enableIso15118 : 39|1@1+ (1,0) [0|0] "" Vector__XXX

BO_ 820 UI_powertrainControl: 8 Vector__XXX
 SG_ UI_systemPowerLimit : 0|5@1+ (20,20) [0|0] "" Vector__XXX
 SG_ UI_pedalMap : 5|2@1+ (1,0) [0|0] "" Vector__XXX
 SG_ UI_enableRegenBackfill : 7|1@1+ (1,0) [0|0] "" Vector__XXX
 SG_ UI_systemTorqueLimit : 8|6@1+ (150,1000) [0|0] "" Vector__XXX
 SG_ UI_closureConfirmed : 14|2@1+ (1,0) [0|0] "" Vector__XXX
 SG_ UI_regenTorqueMax : 16|5@1+ (5,0) [0|0] "" Vector__XXX
 SG_ UI_limitMode : 21|2@1+ (1,0) [0|0] "" Vector__XXX
 SG_ UI_motorOnMode : 24|2@1+ (1,0) [0|0] "" Vector__XXX
 SG_ UI_wasteMode : 26|2@1+ (1,0) [0|0] "" Vector__XXX
 SG_ UI_wasteModeRegenLimit : 28|2@1+ (1,0) [0|0] "" Vector__XXX
 SG_ UI_stoppingMode : 30|2@1+ (1,0) [0|0] "" Vector__XXX
 SG_ UI_DIAppSliderDebug : 32|2@1+ (1,0) [0|0] "" Vector__XXX
 SG_ UI_speedLimit : 34|12@1+ (0.1,0) [0|0] "" Vector__XXX
 SG_ UI_powertrainControlCounter : 52|4@1+ (1,0) [0|0] "" Vector__XXX
 SG_ UI_powertrainControlChecksum : 56|8@1+ (1,0) [0|0] "" Vector__XXX

BO_ 821 DIR_info: 8 Vector__XXX
 SG_ DIR_infoIndex M : 0|8@1+ (1,0) [0|0] "" Vector__XXX
 SG_ DIR_appGitHash m17 : 8|56@1+ (1,0) [0|0] "" Vector__XXX
 SG_ DIR_bootGitHash m18 : 8|56@1+ (1,0) [0|0] "" Vector__XXX
 SG_ DIR_buildType m10 : 8|3@1+ (1,0) [0|0] "" Vector__XXX
 SG_ DIR_infoBootLdUdsProtocolVersion m20 : 8|8@1+ (1,0) [0|0] "" Vector__XXX
 SG_ DIR_motorType m12 : 8|6@1+ (1,0) [0|0] "" Vector__XXX
 SG_ DIR_oilPumpBuildType m16 : 8|3@1+ (1,0) [0|0] "" Vector__XXX
 SG_ DIR_oilPumpPcbaId m33 : 8|8@1+ (1,0) [0|0] "" Vector__XXX
 SG_ DIR_platformTyp m19 : 8|8@1+ (1,0) [0|0] "" Vector__XXX
 SG_ DIR_refRotorFlux m35 : 8|16@1+ (0.0001,0) [0|0] "" Vector__XXX
 SG_ DIR_speedWearTotal m36 : 8|8@1+ (0.4,0) [0|0] "" Vector__XXX
 SG_ DIR_subcomponentGitHash m31 : 8|56@1+ (1,0) [0|0] "" Vector__XXX
 SG_ DIR_buildConfigurationId m10 : 16|16@1+ (1,0) [0|0] "" Vector__XXX
 SG_ DIR_oilPumpAppCrc m16 : 16|32@1+ (1,0) [0|0] "" Vector__XXX
 SG_ DIR_oilPumpAssemblyId m33 : 16|8@1+ (1,0) [0|0] "" Vector__XXX
 SG_ DIR_pcbaId m11 : 16|8@1+ (1,0) [0|0] "" Vector__XXX
 SG_ DIR_siliconType m12 : 16|1@1+ (1,0) [0|0] "" Vector__XXX
 SG_ DIR_assemblyId m11 : 24|8@1+ (1,0) [0|0] "" Vector__XXX
 SG_ DIR_mechSafeStateType m12 : 24|2@1+ (1,0) [0|0] "" Vector__XXX
 SG_ DIR_oilPumpUsageId m33 : 24|16@1+ (1,0) [0|0] "" Vector__XXX
 SG_ DIR_refRotorOffset m35 : 24|12@1- (0.1,0) [0|0] "" Vector__XXX
 SG_ DIR_torqueWearTotal m36 : 24|8@1+ (0.02,0) [0|0] "" Vector__XXX
 SG_ DIR_applicationCrc m13 : 32|32@1+ (1,0) [0|0] "" Vector__XXX
 SG_ DIR_bootloaderCrc m20 : 32|32@1+ (1,0) [0|0] "" Vector__XXX
 SG_ DIR_hardwareId m10 : 32|8@1+ (1,0) [0|0] "" Vector__XXX
 SG_ DIR_usageId m11 : 32|16@1+ (1,0) [0|0] "" Vector__XXX
 SG_ DIR_FPGA_version m16 : 48|8@1+ (1,0) [0|0] "" Vector__XXX
 SG_ DIR_componentId m10 : 48|16@1+ (1,0) [0|0] "" Vector__XXX
 SG_ DIR_subUsageId m11 : 48|16@1+ (1,0) [0|0] "" Vector__XXX

BO_ 824 UMC_alertMatrix1: 8 Vector__XXX
 SG_ UMC_a001_gndMonIntrptLineSide : 0|1@1+ (1,0) [0|0] "" Vector__XXX
 SG_ UMC_a002_GFCITripped : 1|1@1+ (1,0) [0|0] "" Vector__XXX
 SG_ UMC_a003_GFCISelfTestFault : 2|1@1+ (1,0) [0|0] "" Vector__XXX
 SG_ UMC_a004_inputOverVoltage : 3|1@1+ (1,0) [0|0] "" Vector__XXX
 SG_ UMC_a005_inputUnderVoltage : 4|1@1+ (1,0) [0|0] "" Vector__XXX
 SG_ UMC_a006_contactorWelded : 5|1@1+ (1,0) [0|0] "" Vector__XXX
 SG_ UMC_a007_pcbaOT : 6|1@1+ (1,0) [0|0] "" Vector__XXX
 SG_ UMC_a008_wallPlugOT : 7|1@1+ (1,0) [0|0] "" Vector__XXX
 SG_ UMC_a009_vehConnOT : 8|1@1+ (1,0) [0|0] "" Vector__XXX
 SG_ UMC_a010_inputOT : 9|1@1+ (1,0) [0|0] "" Vector__XXX
 SG_ UMC_a011_proxDisconnected : 10|1@1+ (1,0) [0|0] "" Vector__XXX
 SG_ UMC_a012_pilotFault : 11|1@1+ (1,0) [0|0] "" Vector__XXX
 SG_ UMC_a013_SA_Temperature : 12|1@1+ (1,0) [0|0] "" Vector__XXX
 SG_ UMC_a014_SA_Genealogy : 13|1@1+ (1,0) [0|0] "" Vector__XXX
 SG_ UMC_a015_SA_Connection : 14|1@1+ (1,0) [0|0] "" Vector__XXX
 SG_ UMC_a016_pcbaOTFoldback : 15|1@1+ (1,0) [0|0] "" Vector__XXX
 SG_ UMC_a017_wallPlugOTFoldback : 16|1@1+ (1,0) [0|0] "" Vector__XXX
 SG_ UMC_a018_vehConnOTFoldback : 17|1@1+ (1,0) [0|0] "" Vector__XXX
 SG_ UMC_a019_inputOTFoldback : 18|1@1+ (1,0) [0|0] "" Vector__XXX
 SG_ UMC_a020_applicationCRC : 19|1@1+ (1,0) [0|0] "" Vector__XXX
 SG_ UMC_a021_dataBus : 20|1@1+ (1,0) [0|0] "" Vector__XXX
 SG_ UMC_a022_criticalRAM : 21|1@1+ (1,0) [0|0] "" Vector__XXX
 SG_ UMC_a023_adcSelfTest : 22|1@1+ (1,0) [0|0] "" Vector__XXX
 SG_ UMC_a024_gndResistanceHigh : 23|1@1+ (1,0) [0|0] "" Vector__XXX
 SG_ UMC_a025_cntrOpenExpectedClose : 24|1@1+ (1,0) [0|0] "" Vector__XXX
 SG_ UMC_a026_vRefOutOfRange : 25|1@1+ (1,0) [0|0] "" Vector__XXX
 SG_ UMC_a027_watchdogExpired : 26|1@1+ (1,0) [0|0] "" Vector__XXX
 SG_ UMC_a028_processorBooted : 27|1@1+ (1,0) [0|0] "" Vector__XXX
 SG_ UMC_a029_acPowerLoss : 28|1@1+ (1,0) [0|0] "" Vector__XXX
 SG_ UMC_a030_acLostPllLock : 29|1@1+ (1,0) [0|0] "" Vector__XXX
 SG_ UMC_a031_relayCoilVIrrational : 30|1@1+ (1,0) [0|0] "" Vector__XXX
 SG_ UMC_a032_chcVitalsRequestFailure : 31|1@1+ (1,0) [0|0] "" Vector__XXX
 SG_ UMC_a033_chcUpdateFault : 32|1@1+ (1,0) [0|0] "" Vector__XXX
 SG_ UMC_a034_v2lSAUnsupported : 33|1@1+ (1,0) [0|0] "" Vector__XXX
 SG_ UMC_a035_v2lHVACDetected : 34|1@1+ (1,0) [0|0] "" Vector__XXX
 SG_ UMC_a037_GFCICalibration : 36|1@1+ (1,0) [0|0] "" Vector__XXX
 SG_ UMC_a038_chcVitalsFault : 37|1@1+ (1,0) [0|0] "" Vector__XXX
 SG_ UMC_a039_inputOverCurrent : 38|1@1+ (1,0) [0|0] "" Vector__XXX
 SG_ UMC_a040_gndDisconnected : 39|1@1+ (1,0) [0|0] "" Vector__XXX
 SG_ UMC_a041_handleTempIrrational : 40|1@1+ (1,0) [0|0] "" Vector__XXX

BO_ 825 VCSEC_authentication: 8 Vector__XXX
 SG_ VCSEC_BLEConnectionCounter : 0|4@1+ (1,0) [0|0] "" Vector__XXX
 SG_ VCSEC_authRejectionReason : 4|3@1+ (1,0) [0|0] "" Vector__XXX
 SG_ VCSEC_IDRequested : 7|1@1+ (1,0) [0|0] "" Vector__XXX
 SG_ VCSEC_operationMode : 8|2@1+ (1,0) [0|0] "" Vector__XXX
 SG_ VCSEC_vehicleLockStatus : 12|4@1+ (1,0) [0|0] "" Vector__XXX
 SG_ VCSEC_authenticationStatus : 16|2@1+ (1,0) [0|0] "" Vector__XXX
 SG_ VCSEC_chargePortLockStatus : 18|1@1+ (1,0) [0|0] "" Vector__XXX
 SG_ VCSEC_leftFrontLockStatus : 19|1@1+ (1,0) [0|0] "" Vector__XXX
 SG_ VCSEC_leftRearLockStatus : 20|1@1+ (1,0) [0|0] "" Vector__XXX
 SG_ VCSEC_rightFrontLockStatus : 21|1@1+ (1,0) [0|0] "" Vector__XXX
 SG_ VCSEC_rightRearLockStatus : 22|1@1+ (1,0) [0|0] "" Vector__XXX
 SG_ VCSEC_trunkLockStatus : 23|1@1+ (1,0) [0|0] "" Vector__XXX
 SG_ VCSEC_lockRequestType : 24|5@1+ (1,0) [0|0] "" Vector__XXX
 SG_ VCSEC_summonRequest : 29|3@1+ (1,0) [0|0] "" Vector__XXX
 SG_ VCSEC_3rdPartyPLGRequest : 32|2@1+ (1,0) [0|0] "" Vector__XXX
 SG_ VCSEC_3rdPartyFrunkPLGRequest : 34|2@1+ (1,0) [0|0] "" Vector__XXX
 SG_ VCSEC_MCUCommandType : 36|3@1+ (1,0) [0|0] "" Vector__XXX
 SG_ VCSEC_frunkLockStatus : 39|1@1+ (1,0) [0|0] "" Vector__XXX
 SG_ VCSEC_usingModifiedMACAddress : 40|1@1+ (1,0) [0|0] "" Vector__XXX
 SG_ VCSEC_isKeyWithinSummonRange : 41|1@1+ (1,0) [0|0] "" Vector__XXX
 SG_ VCSEC_isBLEDeviceWithinSummonRange : 42|1@1+ (1,0) [0|0] "" Vector__XXX
 SG_ VCSEC_alarmStatus : 43|4@1+ (1,0) [0|0] "" Vector__XXX
 SG_ VCSEC_serviceDiagnosticRequest : 47|1@1+ (1,0) [0|0] "" Vector__XXX
 SG_ VCSEC_immobilizerState : 48|3@1+ (1,0) [0|0] "" Vector__XXX
 SG_ VCSEC_lockIndicationRequest : 51|3@1+ (1,0) [0|0] "" Vector__XXX
 SG_ VCSEC_simpleLockStatus : 54|2@1+ (1,0) [0|0] "" Vector__XXX
 SG_ VCSEC_keyChannelIndexed : 56|4@1+ (1,0) [0|0] "" Vector__XXX
 SG_ VCSEC_authRequested : 60|1@1+ (1,0) [0|0] "" Vector__XXX
 SG_ VCSEC_remoteStartActive : 61|2@1+ (1,0) [0|0] "" Vector__XXX
 SG_ VCSEC_keyPairDesired : 63|1@1+ (1,0) [0|0] "" Vector__XXX

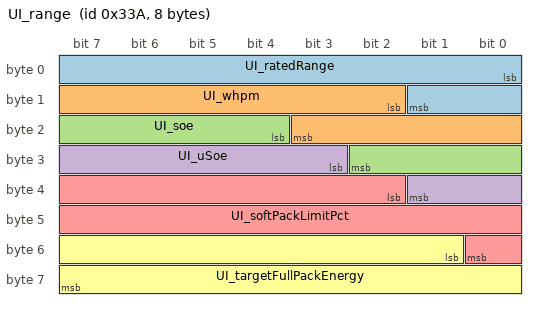
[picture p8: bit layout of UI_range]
BO_ 826 UI_range: 8 Vector__XXX
 SG_ UI_ratedRange : 0|10@1+ (1,0) [0|0] "" Vector__XXX
 SG_ UI_whpm : 10|10@1+ (1,0) [0|0] "" Vector__XXX
 SG_ UI_soe : 20|7@1+ (1,0) [0|0] "" Vector__XXX
 SG_ UI_uSoe : 27|7@1+ (1,0) [0|0] "" Vector__XXX
 SG_ UI_softPackLimitPct : 34|15@1+ (0.0030518509475997192,0) [0|0] "" Vector__XXX
 SG_ UI_targetFullPackEnergy : 49|15@1+ (0.0061037018951994385,0) [0|0] "" Vector__XXX

BO_ 829 CP_plcInfo: 8 Vector__XXX
 SG_ CP_plcFwCrc : 0|32@1+ (1,0) [0|0] "" Vector__XXX
 SG_ CP_plcPibCrc : 32|32@1+ (1,0) [0|0] "" Vector__XXX

BO_ 832 VCFRONT_alertMatrix: 8 Vector__XXX
 SG_ VCFRONT_matrixIndex M : 0|4@1+ (1,0) [0|0] "" Vector__XXX
 SG_ VCFRONT_a001_WatchdogReset m0 : 4|1@1+ (1,0) [0|0] "" Vector__XXX
 SG_ VCFRONT_a061_XCPConnected m1 : 4|1@1+ (1,0) [0|0] "" Vector__XXX
 SG_ VCFRONT_a121_pumpBatICLatchFault m2 : 4|1@1+ (1,0) [0|0] "" Vector__XXX
 SG_ VCFRONT_a181_homelinkMIA m3 : 4|1@1+ (1,0) [0|0] "" Vector__XXX
 SG_ VCFRONT_a301_wipersFactoryDisabled m5 : 4|1@1+ (1,0) [0|0] "" Vector__XXX
 SG_ VCFRONT_a361_washerFluidLowMomentary m6 : 4|1@1+ (1,0) [0|0] "" Vector__XXX
 SG_ VCFRONT_a421_leftHeadlampUartCondition m7 : 4|1@1+ (1,0) [0|0] "" Vector__XXX
 SG_ VCFRONT_a481_vnf1048SelfTestFailure m8 : 4|1@1+ (1,0) [0|0] "" Vector__XXX
 SG_ VCFRONT_a541_LVBatteryChargeOCLevel1 m9 : 4|1@1+ (1,0) [0|0] "" Vector__XXX
 SG_ VCFRONT_a601_autopilotAirPurgeLimitReached m10 : 4|1@1+ (1,0) [0|0] "" Vector__XXX
 SG_ VCFRONT_a661_mculessLeftHeadlampCurrentAlertDbg m11 : 4|1@1+ (1,0) [0|0] "" Vector__XXX
 SG_ VCFRONT_a002_PowerLossReset m0 : 5|1@1+ (1,0) [0|0] "" Vector__XXX
 SG_ VCFRONT_a062_XCPWasConnected m1 : 5|1@1+ (1,0) [0|0] "" Vector__XXX
 SG_ VCFRONT_a122_pumpBatICWarning m2 : 5|1@1+ (1,0) [0|0] "" Vector__XXX
 SG_ VCFRONT_a182_replaceLVBattery m3 : 5|1@1+ (1,0) [0|0] "" Vector__XXX
 SG_ VCFRONT_a242_drveBlckdVltgeTooLow m4 : 5|1@1+ (1,0) [0|0] "" Vector__XXX
 SG_ VCFRONT_a302_wiperCommError m5 : 5|1@1+ (1,0) [0|0] "" Vector__XXX
 SG_ VCFRONT_a362_TLVBMS_AllSocCorrectionTimeout m6 : 5|1@1+ (1,0) [0|0] "" Vector__XXX
 SG_ VCFRONT_a482_rightHeadlampMigrationDebug m8 : 5|1@1+ (1,0) [0|0] "" Vector__XXX
 SG_ VCFRONT_a542_refrigerantReclaim m9 : 5|1@1+ (1,0) [0|0] "" Vector__XXX
 SG_ VCFRONT_a662_mculessRightHeadlampCurrentAlertDbg m11 : 5|1@1+ (1,0) [0|0] "" Vector__XXX
 SG_ VCFRONT_a003_SWAssertion m0 : 6|1@1+ (1,0) [0|0] "" Vector__XXX
 SG_ VCFRONT_a063_SwitchFault m1 : 6|1@1+ (1,0) [0|0] "" Vector__XXX
 SG_ VCFRONT_a123_pumpPtICLatchFault m2 : 6|1@1+ (1,0) [0|0] "" Vector__XXX
 SG_ VCFRONT_a183_replaceLVBattery2 m3 : 6|1@1+ (1,0) [0|0] "" Vector__XXX
 SG_ VCFRONT_a243_LVOverchargeInstc m4 : 6|1@1+ (1,0) [0|0] "" Vector__XXX
 SG_ VCFRONT_a303_frunkAccessPostActive m5 : 6|1@1+ (1,0) [0|0] "" Vector__XXX
 SG_ VCFRONT_a363_TLVBMS_BleedBasedWeakShort m6 : 6|1@1+ (1,0) [0|0] "" Vector__XXX
 SG_ VCFRONT_a423_TLVBMS_BrickUnderVoltageFault m7 : 6|1@1+ (1,0) [0|0] "" Vector__XXX
 SG_ VCFRONT_a483_leftHeadlampStepperMotorFault m8 : 6|1@1+ (1,0) [0|0] "" Vector__XXX
 SG_ VCFRONT_a543_compressorLowFlowDeliveryDetected m9 : 6|1@1+ (1,0) [0|0] "" Vector__XXX
 SG_ VCFRONT_a663_leftHeadlampUartWaterMarkWarning m11 : 6|1@1+ (1,0) [0|0] "" Vector__XXX
 SG_ VCFRONT_a004_adaptiveHeadlightsUnavailable m0 : 7|1@1+ (1,0) [0|0] "" Vector__XXX
 SG_ VCFRONT_a064_busSleepReqTimeout m1 : 7|1@1+ (1,0) [0|0] "" Vector__XXX
 SG_ VCFRONT_a124_pumpPtICWarning m2 : 7|1@1+ (1,0) [0|0] "" Vector__XXX
 SG_ VCFRONT_a184_cabinCoolingPerformanceAbnormal m3 : 7|1@1+ (1,0) [0|0] "" Vector__XXX
 SG_ VCFRONT_a244_sleepBypassFault m4 : 7|1@1+ (1,0) [0|0] "" Vector__XXX
 SG_ VCFRONT_a304_frunkReleaseFailed m5 : 7|1@1+ (1,0) [0|0] "" Vector__XXX
 SG_ VCFRONT_a364_heaterTypeEstimationChanged m6 : 7|1@1+ (1,0) [0|0] "" Vector__XXX
 SG_ VCFRONT_a424_TLVBMS_BrickUnderVoltageOcv m7 : 7|1@1+ (1,0) [0|0] "" Vector__XXX
 SG_ VCFRONT_a484_headlampLevelingRideHeightDebug m8 : 7|1@1+ (1,0) [0|0] "" Vector__XXX
 SG_ VCFRONT_a544_LVBatteryCommsBusTurnedOff m9 : 7|1@1+ (1,0) [0|0] "" Vector__XXX
 SG_ VCFRONT_a664_rightHeadlampUartWaterMarkWarning m11 : 7|1@1+ (1,0) [0|0] "" Vector__XXX
 SG_ VCFRONT_a005_CANTXError m0 : 8|1@1+ (1,0) [0|0] "" Vector__XXX
 SG_ VCFRONT_a125_thmlFanICLatchFault m2 : 8|1@1+ (1,0) [0|0] "" Vector__XXX
 SG_ VCFRONT_a185_washerFluidLow m3 : 8|1@1+ (1,0) [0|0] "" Vector__XXX
 SG_ VCFRONT_a245_pump1EFuseFault m4 : 8|1@1+ (1,0) [0|0] "" Vector__XXX
 SG_ VCFRONT_a305_frunkPriOverCurrent m5 : 8|1@1+ (1,0) [0|0] "" Vector__XXX
 SG_ VCFRONT_a365_burnInRoutineEntered m6 : 8|1@1+ (1,0) [0|0] "" Vector__XXX
 SG_ VCFRONT_a425_TLVBMS_BusVoltageTooHigh m7 : 8|1@1+ (1,0) [0|0] "" Vector__XXX
 SG_ VCFRONT_a485_leftHeadlampMigrationDebug m8 : 8|1@1+ (1,0) [0|0] "" Vector__XXX
 SG_ VCFRONT_a545_LVBatteryTypeUnknown m9 : 8|1@1+ (1,0) [0|0] "" Vector__XXX
 SG_ VCFRONT_a605_sleepBypassPowerOff m10 : 8|1@1+ (1,0) [0|0] "" Vector__XXX
 SG_ VCFRONT_a665_leftHeadlampRetryInfo m11 : 8|1@1+ (1,0) [0|0] "" Vector__XXX
 SG_ VCFRONT_a006_CANTX_cyclicError m0 : 9|1@1+ (1,0) [0|0] "" Vector__XXX
 SG_ VCFRONT_a126_thmlFanICWarning m2 : 9|1@1+ (1,0) [0|0] "" Vector__XXX
 SG_ VCFRONT_a186_noDriveChgCableCon m3 : 9|1@1+ (1,0) [0|0] "" Vector__XXX
 SG_ VCFRONT_a246_pump2EFuseFault m4 : 9|1@1+ (1,0) [0|0] "" Vector__XXX
 SG_ VCFRONT_a306_frunkPriUnderCurrent m5 : 9|1@1+ (1,0) [0|0] "" Vector__XXX
 SG_ VCFRONT_a366_burnInRoutineExited m6 : 9|1@1+ (1,0) [0|0] "" Vector__XXX
 SG_ VCFRONT_a426_TLVBMS_BusVoltageTooLow m7 : 9|1@1+ (1,0) [0|0] "" Vector__XXX
 SG_ VCFRONT_a486_mcuGraphicsEFuseFault m8 : 9|1@1+ (1,0) [0|0] "" Vector__XXX
 SG_ VCFRONT_a546_leftLowOrHighBeamLightCondition m9 : 9|1@1+ (1,0) [0|0] "" Vector__XXX
 SG_ VCFRONT_a606_chillerBattHeatingExit m10 : 9|1@1+ (1,0) [0|0] "" Vector__XXX
 SG_ VCFRONT_a666_rightHeadlampRetryInfo m11 : 9|1@1+ (1,0) [0|0] "" Vector__XXX
 SG_ VCFRONT_a127_vcleftEFuseTrip m2 : 10|1@1+ (1,0) [0|0] "" Vector__XXX
 SG_ VCFRONT_a187_busesNotSleeping m3 : 10|1@1+ (1,0) [0|0] "" Vector__XXX
 SG_ VCFRONT_a247_evapSolenoidFault m4 : 10|1@1+ (1,0) [0|0] "" Vector__XXX
 SG_ VCFRONT_a307_frunkSecOverCurrent m5 : 10|1@1+ (1,0) [0|0] "" Vector__XXX
 SG_ VCFRONT_a367_dischargeRoutineEntered m6 : 10|1@1+ (1,0) [0|0] "" Vector__XXX
 SG_ VCFRONT_a427_TLVBMS_CacChange m7 : 10|1@1+ (1,0) [0|0] "" Vector__XXX
 SG_ VCFRONT_a487_leftHeadlampLastPositionUpdate m8 : 10|1@1+ (1,0) [0|0] "" Vector__XXX
 SG_ VCFRONT_a547_postCrashLoadShed m9 : 10|1@1+ (1,0) [0|0] "" Vector__XXX
 SG_ VCFRONT_a607_sleepPowerDebug m10 : 10|1@1+ (1,0) [0|0] "" Vector__XXX
 SG_ VCFRONT_a667_leftHeadlampRegionOrSideMismatch m11 : 10|1@1+ (1,0) [0|0] "" Vector__XXX
 SG_ VCFRONT_a008_adaptiveHeadlightsUnavailableStalk m0 : 11|1@1+ (1,0) [0|0] "" Vector__XXX
 SG_ VCFRONT_a128_vcrightEFuseTrip m2 : 11|1@1+ (1,0) [0|0] "" Vector__XXX
 SG_ VCFRONT_a188_sleepFailed m3 : 11|1@1+ (1,0) [0|0] "" Vector__XXX
 SG_ VCFRONT_a248_voltageOutOfSpec m4 : 11|1@1+ (1,0) [0|0] "" Vector__XXX
 SG_ VCFRONT_a308_frunkSecUnderCurrent m5 : 11|1@1+ (1,0) [0|0] "" Vector__XXX
 SG_ VCFRONT_a368_dischargeRoutineExited m6 : 11|1@1+ (1,0) [0|0] "" Vector__XXX
 SG_ VCFRONT_a428_TLVBMS_CacImbalance m7 : 11|1@1+ (1,0) [0|0] "" Vector__XXX
 SG_ VCFRONT_a488_rightHeadlampStepperMotorFault m8 : 11|1@1+ (1,0) [0|0] "" Vector__XXX
 SG_ VCFRONT_a548_HVFaultLoadShed m9 : 11|1@1+ (1,0) [0|0] "" Vector__XXX
 SG_ VCFRONT_a608_TLVBMS_BleedFetFailure m10 : 11|1@1+ (1,0) [0|0] "" Vector__XXX
 SG_ VCFRONT_a668_rightHeadlampRegionOrSideMismatch m11 : 11|1@1+ (1,0) [0|0] "" Vector__XXX
 SG_ VCFRONT_a009_LCCPurgeAttempted m0 : 12|1@1+ (1,0) [0|0] "" Vector__XXX
 SG_ VCFRONT_a129_pcsEFuseTrip m2 : 12|1@1+ (1,0) [0|0] "" Vector__XXX
 SG_ VCFRONT_a189_IBSMIA m3 : 12|1@1+ (1,0) [0|0] "" Vector__XXX
 SG_ VCFRONT_a249_coolantValveBadMode m4 : 12|1@1+ (1,0) [0|0] "" Vector__XXX
 SG_ VCFRONT_a309_frunkEmergencyReleasePressed m5 : 12|1@1+ (1,0) [0|0] "" Vector__XXX
 SG_ VCFRONT_a369_reducedPowerDischarge m6 : 12|1@1+ (1,0) [0|0] "" Vector__XXX
 SG_ VCFRONT_a429_TLVBMS_CapacityTestResults m7 : 12|1@1+ (1,0) [0|0] "" Vector__XXX
 SG_ VCFRONT_a489_ValveStuckFlagged m8 : 12|1@1+ (1,0) [0|0] "" Vector__XXX
 SG_ VCFRONT_a609_autopilotDriveNotAuthed m10 : 12|1@1+ (1,0) [0|0] "" Vector__XXX
 SG_ VCFRONT_a669_thermalHVPowerBudgetActive m11 : 12|1@1+ (1,0) [0|0] "" Vector__XXX
 SG_ VCFRONT_a010_ExtSupplyVoltError m0 : 13|1@1+ (1,0) [0|0] "" Vector__XXX
 SG_ VCFRONT_a130_epas3pEFuseTrip m2 : 13|1@1+ (1,0) [0|0] "" Vector__XXX
 SG_ VCFRONT_a190_linSchedulingInfo m3 : 13|1@1+ (1,0) [0|0] "" Vector__XXX
 SG_ VCFRONT_a250_headlampsNotAimed m4 : 13|1@1+ (1,0) [0|0] "" Vector__XXX
 SG_ VCFRONT_a310_vcleftOvertempSlope m5 : 13|1@1+ (1,0) [0|0] "" Vector__XXX
 SG_ VCFRONT_a370_noLVSupportSocTooLow m6 : 13|1@1+ (1,0) [0|0] "" Vector__XXX
 SG_ VCFRONT_a430_TLVBMS_ChargeCurrentLimitExceeded m7 : 13|1@1+ (1,0) [0|0] "" Vector__XXX
 SG_ VCFRONT_a490_coolantPumpsNotIdentified m8 : 13|1@1+ (1,0) [0|0] "" Vector__XXX
 SG_ VCFRONT_a610_frunkOpenFailureMetricSet m10 : 13|1@1+ (1,0) [0|0] "" Vector__XXX
 SG_ VCFRONT_a131_epas3sEFuseTrip m2 : 14|1@1+ (1,0) [0|0] "" Vector__XXX
 SG_ VCFRONT_a191_exitDriveLowLVBusVoltage m3 : 14|1@1+ (1,0) [0|0] "" Vector__XXX
 SG_ VCFRONT_a251_UIWakeupTrigger m4 : 14|1@1+ (1,0) [0|0] "" Vector__XXX
 SG_ VCFRONT_a311_vcrightOvertempSlope m5 : 14|1@1+ (1,0) [0|0] "" Vector__XXX
 SG_ VCFRONT_a371_failureToPrechargeRisk m6 : 14|1@1+ (1,0) [0|0] "" Vector__XXX
 SG_ VCFRONT_a431_TLVBMS_ChargeOverCurrent m7 : 14|1@1+ (1,0) [0|0] "" Vector__XXX
 SG_ VCFRONT_a491_rightHeadlampLastPositionUpdate m8 : 14|1@1+ (1,0) [0|0] "" Vector__XXX
 SG_ VCFRONT_a551_leftHeadlampSoftShort m9 : 14|1@1+ (1,0) [0|0] "" Vector__XXX
 SG_ VCFRONT_a611_poorRadiatorHeatRejection m10 : 14|1@1+ (1,0) [0|0] "" Vector__XXX
 SG_ VCFRONT_a012_CPUReset m0 : 15|1@1+ (1,0) [0|0] "" Vector__XXX
 SG_ VCFRONT_a132_iBoosterEFuseTrip m2 : 15|1@1+ (1,0) [0|0] "" Vector__XXX
 SG_ VCFRONT_a192_vehicleLoadShed m3 : 15|1@1+ (1,0) [0|0] "" Vector__XXX
 SG_ VCFRONT_a252_controllerWakeup m4 : 15|1@1+ (1,0) [0|0] "" Vector__XXX
 SG_ VCFRONT_a312_pcsOvertempSlope m5 : 15|1@1+ (1,0) [0|0] "" Vector__XXX
 SG_ VCFRONT_a372_TLVBMS_BmbHwOverVoltageFault m6 : 15|1@1+ (1,0) [0|0] "" Vector__XXX
 SG_ VCFRONT_a432_TLVBMS_ChargeRegulationFault m7 : 15|1@1+ (1,0) [0|0] "" Vector__XXX
 SG_ VCFRONT_a492_TLVBMS_SocImbalance m8 : 15|1@1+ (1,0) [0|0] "" Vector__XXX
 SG_ VCFRONT_a552_eFuseSelfTestFailure m9 : 15|1@1+ (1,0) [0|0] "" Vector__XXX
 SG_ VCFRONT_a612_LVUnhealthyLoadShed m10 : 15|1@1+ (1,0) [0|0] "" Vector__XXX
 SG_ VCFRONT_a013_AlertManagerFault m0 : 16|1@1+ (1,0) [0|0] "" Vector__XXX
 SG_ VCFRONT_a133_espEFuseTrip m2 : 16|1@1+ (1,0) [0|0] "" Vector__XXX
 SG_ VCFRONT_a193_mcuAudioRetry m3 : 16|1@1+ (1,0) [0|0] "" Vector__XXX
 SG_ VCFRONT_a253_maxChrgeSssionTmeout m4 : 16|1@1+ (1,0) [0|0] "" Vector__XXX
 SG_ VCFRONT_a313_epas3pOvertempSlope m5 : 16|1@1+ (1,0) [0|0] "" Vector__XXX
 SG_ VCFRONT_a373_chillerControlFlooding m6 : 16|1@1+ (1,0) [0|0] "" Vector__XXX
 SG_ VCFRONT_a433_TLVBMS_ConfigFromBmbModIdFailed m7 : 16|1@1+ (1,0) [0|0] "" Vector__XXX
 SG_ VCFRONT_a493_TLVBMS_SocImbalanceWarning m8 : 16|1@1+ (1,0) [0|0] "" Vector__XXX
 SG_ VCFRONT_a553_rightHeadlampSoftShort m9 : 16|1@1+ (1,0) [0|0] "" Vector__XXX
 SG_ VCFRONT_a613_selfTestsBlockingDrive m10 : 16|1@1+ (1,0) [0|0] "" Vector__XXX
 SG_ VCFRONT_a134_fusedHighEFuseTrip m2 : 17|1@1+ (1,0) [0|0] "" Vector__XXX
 SG_ VCFRONT_a194_iBoosterRetry m3 : 17|1@1+ (1,0) [0|0] "" Vector__XXX
 SG_ VCFRONT_a254_pumpBatStopped m4 : 17|1@1+ (1,0) [0|0] "" Vector__XXX
 SG_ VCFRONT_a314_epas3sOvertempSlope m5 : 17|1@1+ (1,0) [0|0] "" Vector__XXX
 SG_ VCFRONT_a374_lccInletSolenoidFault m6 : 17|1@1+ (1,0) [0|0] "" Vector__XXX
 SG_ VCFRONT_a434_TLVBMS_ConfigInitFailed m7 : 17|1@1+ (1,0) [0|0] "" Vector__XXX
 SG_ VCFRONT_a494_LVBatteryTempBlockingOTA m8 : 17|1@1+ (1,0) [0|0] "" Vector__XXX
 SG_ VCFRONT_a614_coolantSysDriverlessSelfTest m10 : 17|1@1+ (1,0) [0|0] "" Vector__XXX
 SG_ VCFRONT_a015_NVMMError m0 : 18|1@1+ (1,0) [0|0] "" Vector__XXX
 SG_ VCFRONT_a135_coolantLevelLow m2 : 18|1@1+ (1,0) [0|0] "" Vector__XXX
 SG_ VCFRONT_a195_drveBlckdVltgeTooHgh m3 : 18|1@1+ (1,0) [0|0] "" Vector__XXX
 SG_ VCFRONT_a255_pumpPtStopped m4 : 18|1@1+ (1,0) [0|0] "" Vector__XXX
 SG_ VCFRONT_a315_iboosterOvertempSlope m5 : 18|1@1+ (1,0) [0|0] "" Vector__XXX
 SG_ VCFRONT_a375_refVoltageOutOfSpec m6 : 18|1@1+ (1,0) [0|0] "" Vector__XXX
 SG_ VCFRONT_a435_TLVBMS_DchgCurrentLimitExceeded m7 : 18|1@1+ (1,0) [0|0] "" Vector__XXX
 SG_ VCFRONT_a495_LVBatteryRecoveryBlocked m8 : 18|1@1+ (1,0) [0|0] "" Vector__XXX
 SG_ VCFRONT_a555_LVBatteryCellRebalancing m9 : 18|1@1+ (1,0) [0|0] "" Vector__XXX
 SG_ VCFRONT_a615_TLVBMS_BatteryHeaterFault m10 : 18|1@1+ (1,0) [0|0] "" Vector__XXX
 SG_ VCFRONT_a016_NVMMRecordError m0 : 19|1@1+ (1,0) [0|0] "" Vector__XXX
 SG_ VCFRONT_a136_refrigDischTempSns m2 : 19|1@1+ (1,0) [0|0] "" Vector__XXX
 SG_ VCFRONT_a196_discnctdLVBattery m3 : 19|1@1+ (1,0) [0|0] "" Vector__XXX
 SG_ VCFRONT_a256_compTornShaftSeal m4 : 19|1@1+ (1,0) [0|0] "" Vector__XXX
 SG_ VCFRONT_a316_espOvertempSlope m5 : 19|1@1+ (1,0) [0|0] "" Vector__XXX
 SG_ VCFRONT_a376_controllerWakeupDebug m6 : 19|1@1+ (1,0) [0|0] "" Vector__XXX
 SG_ VCFRONT_a436_TLVBMS_DischargeOverCurrent m7 : 19|1@1+ (1,0) [0|0] "" Vector__XXX
 SG_ VCFRONT_a496_LVBatteryExitDriveWarning m8 : 19|1@1+ (1,0) [0|0] "" Vector__XXX
 SG_ VCFRONT_a556_falseTriggerOfDiscnctdBatteryTest m9 : 19|1@1+ (1,0) [0|0] "" Vector__XXX
 SG_ VCFRONT_a017_NVMMStatusDbg m0 : 20|1@1+ (1,0) [0|0] "" Vector__XXX
 SG_ VCFRONT_a137_refrigDischPresSns m2 : 20|1@1+ (1,0) [0|0] "" Vector__XXX
 SG_ VCFRONT_a197_prechargeDCRData3 m3 : 20|1@1+ (1,0) [0|0] "" Vector__XXX
 SG_ VCFRONT_a257_portExpanderVOR m4 : 20|1@1+ (1,0) [0|0] "" Vector__XXX
 SG_ VCFRONT_a317_vbatFusedOvertempSlope m5 : 20|1@1+ (1,0) [0|0] "" Vector__XXX
 SG_ VCFRONT_a377_wiperParkFault m6 : 20|1@1+ (1,0) [0|0] "" Vector__XXX
 SG_ VCFRONT_a437_TLVBMS_NvmRegistrationError m7 : 20|1@1+ (1,0) [0|0] "" Vector__XXX
 SG_ VCFRONT_a497_LVBatteryWarnDisconnect m8 : 20|1@1+ (1,0) [0|0] "" Vector__XXX
 SG_ VCFRONT_a138_refrigSuctTempSns m2 : 21|1@1+ (1,0) [0|0] "" Vector__XXX
 SG_ VCFRONT_a198_PRVCANOverterminate m3 : 21|1@1+ (1,0) [0|0] "" Vector__XXX
 SG_ VCFRONT_a258_resistanceEstimationRun m4 : 21|1@1+ (1,0) [0|0] "" Vector__XXX
 SG_ VCFRONT_a318_vcleftOvertempMax m5 : 21|1@1+ (1,0) [0|0] "" Vector__XXX
 SG_ VCFRONT_a378_wiperECUDebug m6 : 21|1@1+ (1,0) [0|0] "" Vector__XXX
 SG_ VCFRONT_a438_TLVBMS_PackOverTemperatureFault m7 : 21|1@1+ (1,0) [0|0] "" Vector__XXX
 SG_ VCFRONT_a498_TLVBMS_ImpedanceTestResults m8 : 21|1@1+ (1,0) [0|0] "" Vector__XXX
 SG_ VCFRONT_a558_rightHeadlampAimingDebug m9 : 21|1@1+ (1,0) [0|0] "" Vector__XXX
 SG_ VCFRONT_a618_cabinCoolingCapacityLimited m10 : 21|1@1+ (1,0) [0|0] "" Vector__XXX
 SG_ VCFRONT_a139_refrigSuctPresSns m2 : 22|1@1+ (1,0) [0|0] "" Vector__XXX
 SG_ VCFRONT_a199_PRVCANUndertrminate m3 : 22|1@1+ (1,0) [0|0] "" Vector__XXX
 SG_ VCFRONT_a259_LVVoltageDropOnHighLoadCurrent m4 : 22|1@1+ (1,0) [0|0] "" Vector__XXX
 SG_ VCFRONT_a319_vcrightOvertempMax m5 : 22|1@1+ (1,0) [0|0] "" Vector__XXX
 SG_ VCFRONT_a379_shortedCellTestRunDebug m6 : 22|1@1+ (1,0) [0|0] "" Vector__XXX
 SG_ VCFRONT_a439_TLVBMS_PackOverTemperatureWarning m7 : 22|1@1+ (1,0) [0|0] "" Vector__XXX
 SG_ VCFRONT_a499_loadShedPumpFlowRequest m8 : 22|1@1+ (1,0) [0|0] "" Vector__XXX
 SG_ VCFRONT_a559_LVBatteryLowSOC m9 : 22|1@1+ (1,0) [0|0] "" Vector__XXX
 SG_ VCFRONT_a619_frunkSwitchReleaseTimeDBG m10 : 22|1@1+ (1,0) [0|0] "" Vector__XXX
 SG_ VCFRONT_a140_coolantTempPtSns m2 : 23|1@1+ (1,0) [0|0] "" Vector__XXX
 SG_ VCFRONT_a200_vcleftSelfTestFail m3 : 23|1@1+ (1,0) [0|0] "" Vector__XXX
 SG_ VCFRONT_a260_deadLVBattery m4 : 23|1@1+ (1,0) [0|0] "" Vector__XXX
 SG_ VCFRONT_a320_pcsOvertempMax m5 : 23|1@1+ (1,0) [0|0] "" Vector__XXX
 SG_ VCFRONT_a380_chillerExvWarning m6 : 23|1@1+ (1,0) [0|0] "" Vector__XXX
 SG_ VCFRONT_a440_TLVBMS_PackSNInvalidForNvm m7 : 23|1@1+ (1,0) [0|0] "" Vector__XXX
 SG_ VCFRONT_a500_eFuseASICStateMismatch m8 : 23|1@1+ (1,0) [0|0] "" Vector__XXX
 SG_ VCFRONT_a560_compressorHighSuperheat m9 : 23|1@1+ (1,0) [0|0] "" Vector__XXX
 SG_ VCFRONT_a021_TaskSchedulerError m0 : 24|1@1+ (1,0) [0|0] "" Vector__XXX
 SG_ VCFRONT_a141_coolantTempBatSns m2 : 24|1@1+ (1,0) [0|0] "" Vector__XXX
 SG_ VCFRONT_a201_vcrightSelfTestFail m3 : 24|1@1+ (1,0) [0|0] "" Vector__XXX
 SG_ VCFRONT_a261_vcleftVoltageMismatch m4 : 24|1@1+ (1,0) [0|0] "" Vector__XXX
 SG_ VCFRONT_a321_epas3pOvertempMax m5 : 24|1@1+ (1,0) [0|0] "" Vector__XXX
 SG_ VCFRONT_a381_evaporatorExvWarning m6 : 24|1@1+ (1,0) [0|0] "" Vector__XXX
 SG_ VCFRONT_a441_TLVBMS_ResetNeededForNvmPackSwap m7 : 24|1@1+ (1,0) [0|0] "" Vector__XXX
 SG_ VCFRONT_a501_vnf1048ConfigurationMismatch m8 : 24|1@1+ (1,0) [0|0] "" Vector__XXX
 SG_ VCFRONT_a561_LVBMSEFuseOvertemperature m9 : 24|1@1+ (1,0) [0|0] "" Vector__XXX
 SG_ VCFRONT_a022_TaskInitError m0 : 25|1@1+ (1,0) [0|0] "" Vector__XXX
 SG_ VCFRONT_a082_VCRIGHT_IPC_MIA m1 : 25|1@1+ (1,0) [0|0] "" Vector__XXX
 SG_ VCFRONT_a142_exvMotorFault m2 : 25|1@1+ (1,0) [0|0] "" Vector__XXX
 SG_ VCFRONT_a202_pcsSelfTestFail m3 : 25|1@1+ (1,0) [0|0] "" Vector__XXX
 SG_ VCFRONT_a262_vcrightVoltageMismatch m4 : 25|1@1+ (1,0) [0|0] "" Vector__XXX
 SG_ VCFRONT_a322_epas3sOvertempMax m5 : 25|1@1+ (1,0) [0|0] "" Vector__XXX
 SG_ VCFRONT_a382_recircExvWarning m6 : 25|1@1+ (1,0) [0|0] "" Vector__XXX
 SG_ VCFRONT_a442_TLVBMS_SocChange m7 : 25|1@1+ (1,0) [0|0] "" Vector__XXX
 SG_ VCFRONT_a502_TLVBMS_WeakShortImpedance m8 : 25|1@1+ (1,0) [0|0] "" Vector__XXX
 SG_ VCFRONT_a562_LVBMSModuleOvertemperature m9 : 25|1@1+ (1,0) [0|0] "" Vector__XXX
 SG_ VCFRONT_a083_VCLEFT_IPC_MIA m1 : 26|1@1+ (1,0) [0|0] "" Vector__XXX
 SG_ VCFRONT_a143_pumpBatICTransFault m2 : 26|1@1+ (1,0) [0|0] "" Vector__XXX
 SG_ VCFRONT_a203_epas3pSelfTestFail m3 : 26|1@1+ (1,0) [0|0] "" Vector__XXX
 SG_ VCFRONT_a263_pcsVoltageMismatch m4 : 26|1@1+ (1,0) [0|0] "" Vector__XXX
 SG_ VCFRONT_a323_iboosterOvertempMax m5 : 26|1@1+ (1,0) [0|0] "" Vector__XXX
 SG_ VCFRONT_a383_lccExvWarning m6 : 26|1@1+ (1,0) [0|0] "" Vector__XXX
 SG_ VCFRONT_a443_TLVBMS_BmbDieOverTemperature m7 : 26|1@1+ (1,0) [0|0] "" Vector__XXX
 SG_ VCFRONT_a503_TLVBMS_BrickExtendedOvFault m8 : 26|1@1+ (1,0) [0|0] "" Vector__XXX
 SG_ VCFRONT_a563_chargePortDoorOpenBlockedByBrake m9 : 26|1@1+ (1,0) [0|0] "" Vector__XXX
 SG_ VCFRONT_a623_LVUnhealthy m10 : 26|1@1+ (1,0) [0|0] "" Vector__XXX
 SG_ VCFRONT_a084_TPMS_MIA m1 : 27|1@1+ (1,0) [0|0] "" Vector__XXX
 SG_ VCFRONT_a144_pumpPtICTransFault m2 : 27|1@1+ (1,0) [0|0] "" Vector__XXX
 SG_ VCFRONT_a204_epas3sSelfTestFail m3 : 27|1@1+ (1,0) [0|0] "" Vector__XXX
 SG_ VCFRONT_a264_iBoosterVoltageMismatch m4 : 27|1@1+ (1,0) [0|0] "" Vector__XXX
 SG_ VCFRONT_a324_espOvertempMax m5 : 27|1@1+ (1,0) [0|0] "" Vector__XXX
 SG_ VCFRONT_a384_ccLeftExvWarning m6 : 27|1@1+ (1,0) [0|0] "" Vector__XXX
 SG_ VCFRONT_a444_drv8703Fault m7 : 27|1@1+ (1,0) [0|0] "" Vector__XXX
 SG_ VCFRONT_a504_airInRefrigerantDetected m8 : 27|1@1+ (1,0) [0|0] "" Vector__XXX
 SG_ VCFRONT_a564_leftHeadlampAimingDebug m9 : 27|1@1+ (1,0) [0|0] "" Vector__XXX
 SG_ VCFRONT_a085_CCCM_MIA m1 : 28|1@1+ (1,0) [0|0] "" Vector__XXX
 SG_ VCFRONT_a145_thmlFanICTransFault m2 : 28|1@1+ (1,0) [0|0] "" Vector__XXX
 SG_ VCFRONT_a205_iBoosterSelfTestFail m3 : 28|1@1+ (1,0) [0|0] "" Vector__XXX
 SG_ VCFRONT_a265_ESPVoltageMismatch m4 : 28|1@1+ (1,0) [0|0] "" Vector__XXX
 SG_ VCFRONT_a325_vbatFusedOvertempMax m5 : 28|1@1+ (1,0) [0|0] "" Vector__XXX
 SG_ VCFRONT_a385_ccRightExvWarning m6 : 28|1@1+ (1,0) [0|0] "" Vector__XXX
 SG_ VCFRONT_a445_drv8703SpiFaultDBG m7 : 28|1@1+ (1,0) [0|0] "" Vector__XXX
 SG_ VCFRONT_a505_BLEFrontUnderVoltage m8 : 28|1@1+ (1,0) [0|0] "" Vector__XXX
 SG_ VCFRONT_a565_userPresenceDisplayStateMismatch m9 : 28|1@1+ (1,0) [0|0] "" Vector__XXX
 SG_ VCFRONT_a086_VCBATT_MIA m1 : 29|1@1+ (1,0) [0|0] "" Vector__XXX
 SG_ VCFRONT_a146_pumpBatSoftStall m2 : 29|1@1+ (1,0) [0|0] "" Vector__XXX
 SG_ VCFRONT_a206_espSelfTestFail m3 : 29|1@1+ (1,0) [0|0] "" Vector__XXX
 SG_ VCFRONT_a266_EPAS3pVoltageMismatch m4 : 29|1@1+ (1,0) [0|0] "" Vector__XXX
 SG_ VCFRONT_a326_vcleftSlowTripOC m5 : 29|1@1+ (1,0) [0|0] "" Vector__XXX
 SG_ VCFRONT_a386_exvMotorWarning m6 : 29|1@1+ (1,0) [0|0] "" Vector__XXX
 SG_ VCFRONT_a446_cabinHVACUnavailableContext m7 : 29|1@1+ (1,0) [0|0] "" Vector__XXX
 SG_ VCFRONT_a506_invalidRefrigerantSystemConfig m8 : 29|1@1+ (1,0) [0|0] "" Vector__XXX
 SG_ VCFRONT_a566_leftFrontTurnLightFault m9 : 29|1@1+ (1,0) [0|0] "" Vector__XXX
 SG_ VCFRONT_a626_LVBatteryResistanceIncrease m10 : 29|1@1+ (1,0) [0|0] "" Vector__XXX
 SG_ VCFRONT_a087_DIREL_MIA m1 : 30|1@1+ (1,0) [0|0] "" Vector__XXX
 SG_ VCFRONT_a147_pumpPtSoftStall m2 : 30|1@1+ (1,0) [0|0] "" Vector__XXX
 SG_ VCFRONT_a207_vbatFusdSelfTestFail m3 : 30|1@1+ (1,0) [0|0] "" Vector__XXX
 SG_ VCFRONT_a267_EPAS3sVoltageMismatch m4 : 30|1@1+ (1,0) [0|0] "" Vector__XXX
 SG_ VCFRONT_a327_vcrightSlowTripOC m5 : 30|1@1+ (1,0) [0|0] "" Vector__XXX
 SG_ VCFRONT_a387_shortedCellInstc m6 : 30|1@1+ (1,0) [0|0] "" Vector__XXX
 SG_ VCFRONT_a447_cabinHVACUnavailable m7 : 30|1@1+ (1,0) [0|0] "" Vector__XXX
 SG_ VCFRONT_a507_leftHeadlampAimingFault m8 : 30|1@1+ (1,0) [0|0] "" Vector__XXX
 SG_ VCFRONT_a567_rightFrontTurnLightFault m9 : 30|1@1+ (1,0) [0|0] "" Vector__XXX
 SG_ VCFRONT_a627_LVBatteryUnrecoverableByAnyDevice m10 : 30|1@1+ (1,0) [0|0] "" Vector__XXX
 SG_ VCFRONT_a088_DIRER_MIA m1 : 31|1@1+ (1,0) [0|0] "" Vector__XXX
 SG_ VCFRONT_a148_thmlFanSoftStall m2 : 31|1@1+ (1,0) [0|0] "" Vector__XXX
 SG_ VCFRONT_a208_brakeFluidLow m3 : 31|1@1+ (1,0) [0|0] "" Vector__XXX
 SG_ VCFRONT_a268_vbatFusedVoltageMismatch m4 : 31|1@1+ (1,0) [0|0] "" Vector__XXX
 SG_ VCFRONT_a328_pcsSlowTripOC m5 : 31|1@1+ (1,0) [0|0] "" Vector__XXX
 SG_ VCFRONT_a388_shortedCell m6 : 31|1@1+ (1,0) [0|0] "" Vector__XXX
 SG_ VCFRONT_a448_gtwSteeringBtnReset m7 : 31|1@1+ (1,0) [0|0] "" Vector__XXX
 SG_ VCFRONT_a508_TLVBMS_ImpedanceGrowth m8 : 31|1@1+ (1,0) [0|0] "" Vector__XXX
 SG_ VCFRONT_a568_leftDaytimeRunningLightFault m9 : 31|1@1+ (1,0) [0|0] "" Vector__XXX
 SG_ VCFRONT_a628_TLVBMS_BmbThermistorFault m10 : 31|1@1+ (1,0) [0|0] "" Vector__XXX
 SG_ VCFRONT_a029_CoreDump m0 : 32|1@1+ (1,0) [0|0] "" Vector__XXX
 SG_ VCFRONT_a089_IBST_MIA m1 : 32|1@1+ (1,0) [0|0] "" Vector__XXX
 SG_ VCFRONT_a149_BLEFrontPowerCycled m2 : 32|1@1+ (1,0) [0|0] "" Vector__XXX
 SG_ VCFRONT_a209_brakeFluidSNA m3 : 32|1@1+ (1,0) [0|0] "" Vector__XXX
 SG_ VCFRONT_a269_drveBlckdVltgeTooLow2 m4 : 32|1@1+ (1,0) [0|0] "" Vector__XXX
 SG_ VCFRONT_a329_epas3pSlowTripOC m5 : 32|1@1+ (1,0) [0|0] "" Vector__XXX
 SG_ VCFRONT_a389_frunkInhibitingReleaseAtSpeed m6 : 32|1@1+ (1,0) [0|0] "" Vector__XXX
 SG_ VCFRONT_a449_hornSwitchStuckOn m7 : 32|1@1+ (1,0) [0|0] "" Vector__XXX
 SG_ VCFRONT_a509_vcrightEFuseLoadShed m8 : 32|1@1+ (1,0) [0|0] "" Vector__XXX
 SG_ VCFRONT_a569_rightDaytimeRunningLightFault m9 : 32|1@1+ (1,0) [0|0] "" Vector__XXX
 SG_ VCFRONT_a629_TLVBMS_PackTemperatureIrrational m10 : 32|1@1+ (1,0) [0|0] "" Vector__XXX
 SG_ VCFRONT_a030_ECULogUploadRequest m0 : 33|1@1+ (1,0) [0|0] "" Vector__XXX
 SG_ VCFRONT_a090_APS_MIA m1 : 33|1@1+ (1,0) [0|0] "" Vector__XXX
 SG_ VCFRONT_a150_pumpBatLowRPMCBang m2 : 33|1@1+ (1,0) [0|0] "" Vector__XXX
 SG_ VCFRONT_a210_coolantValveCalib m3 : 33|1@1+ (1,0) [0|0] "" Vector__XXX
 SG_ VCFRONT_a330_epas3sSlowTripOC m5 : 33|1@1+ (1,0) [0|0] "" Vector__XXX
 SG_ VCFRONT_a390_heatPumpModeConvergence m6 : 33|1@1+ (1,0) [0|0] "" Vector__XXX
 SG_ VCFRONT_a450_hornSwitchNotPressedFactory m7 : 33|1@1+ (1,0) [0|0] "" Vector__XXX
 SG_ VCFRONT_a510_LVBatteryRecoveryTimeout m8 : 33|1@1+ (1,0) [0|0] "" Vector__XXX
 SG_ VCFRONT_a570_headlampsAdaptedToLeftHandTraffic m9 : 33|1@1+ (1,0) [0|0] "" Vector__XXX
 SG_ VCFRONT_a630_leftHeadlampFactoryFault m10 : 33|1@1+ (1,0) [0|0] "" Vector__XXX
 SG_ VCFRONT_a031_UDSActive m0 : 34|1@1+ (1,0) [0|0] "" Vector__XXX
 SG_ VCFRONT_a091_CMPD_MIA m1 : 34|1@1+ (1,0) [0|0] "" Vector__XXX
 SG_ VCFRONT_a151_pumpPtLowRPMCBang m2 : 34|1@1+ (1,0) [0|0] "" Vector__XXX
 SG_ VCFRONT_a211_I2CFault m3 : 34|1@1+ (1,0) [0|0] "" Vector__XXX
 SG_ VCFRONT_a271_LVBatteryPermSupported m4 : 34|1@1+ (1,0) [0|0] "" Vector__XXX
 SG_ VCFRONT_a331_iboosterSlowTripOC m5 : 34|1@1+ (1,0) [0|0] "" Vector__XXX
 SG_ VCFRONT_a391_frunkLatchSwitchFault m6 : 34|1@1+ (1,0) [0|0] "" Vector__XXX
 SG_ VCFRONT_a451_refrigerantNotCommissioned m7 : 34|1@1+ (1,0) [0|0] "" Vector__XXX
 SG_ VCFRONT_a511_DCDCSaturationLoadShed m8 : 34|1@1+ (1,0) [0|0] "" Vector__XXX
 SG_ VCFRONT_a571_headlampsAdaptedToRightHandTraffic m9 : 34|1@1+ (1,0) [0|0] "" Vector__XXX
 SG_ VCFRONT_a631_rightHeadlampFactoryFault m10 : 34|1@1+ (1,0) [0|0] "" Vector__XXX
 SG_ VCFRONT_a032_ipcWatchdogExpired m0 : 35|1@1+ (1,0) [0|0] "" Vector__XXX
 SG_ VCFRONT_a092_VCSEATD_MIA m1 : 35|1@1+ (1,0) [0|0] "" Vector__XXX
 SG_ VCFRONT_a152_thmlFanLowRPMCBang m2 : 35|1@1+ (1,0) [0|0] "" Vector__XXX
 SG_ VCFRONT_a212_IBSOverTemp m3 : 35|1@1+ (1,0) [0|0] "" Vector__XXX
 SG_ VCFRONT_a332_espSlowTripOC m5 : 35|1@1+ (1,0) [0|0] "" Vector__XXX
 SG_ VCFRONT_a392_TLVBMS_BmbHwUnderVoltageFault m6 : 35|1@1+ (1,0) [0|0] "" Vector__XXX
 SG_ VCFRONT_a452_dischargePresSensIntermittent m7 : 35|1@1+ (1,0) [0|0] "" Vector__XXX
 SG_ VCFRONT_a512_LVBMSFault_MOS_Open_hardwareOC m8 : 35|1@1+ (1,0) [0|0] "" Vector__XXX
 SG_ VCFRONT_a572_hvacCompressorEFuseTrip m9 : 35|1@1+ (1,0) [0|0] "" Vector__XXX
 SG_ VCFRONT_a033_eccNonCorrectableError m0 : 36|1@1+ (1,0) [0|0] "" Vector__XXX
 SG_ VCFRONT_a093_VCSEATP_MIA m1 : 36|1@1+ (1,0) [0|0] "" Vector__XXX
 SG_ VCFRONT_a153_userPresenceDisplayMismatchClrd m2 : 36|1@1+ (1,0) [0|0] "" Vector__XXX
 SG_ VCFRONT_a213_LVOvercharge m3 : 36|1@1+ (1,0) [0|0] "" Vector__XXX
 SG_ VCFRONT_a273_wiperFrictionModelFault m4 : 36|1@1+ (1,0) [0|0] "" Vector__XXX
 SG_ VCFRONT_a333_vbatFusedSlowTripOC m5 : 36|1@1+ (1,0) [0|0] "" Vector__XXX
 SG_ VCFRONT_a393_ambientTempNetworkSna m6 : 36|1@1+ (1,0) [0|0] "" Vector__XXX
 SG_ VCFRONT_a453_dischargeTempSensIntermittent m7 : 36|1@1+ (1,0) [0|0] "" Vector__XXX
 SG_ VCFRONT_a513_LVBMSFault_MOS_Open_chgOC m8 : 36|1@1+ (1,0) [0|0] "" Vector__XXX
 SG_ VCFRONT_a573_radarEFuseTrip m9 : 36|1@1+ (1,0) [0|0] "" Vector__XXX
 SG_ VCFRONT_a094_EPAS3P_MIA m1 : 37|1@1+ (1,0) [0|0] "" Vector__XXX
 SG_ VCFRONT_a154_prechargeDCRData1 m2 : 37|1@1+ (1,0) [0|0] "" Vector__XXX
 SG_ VCFRONT_a274_failureToPrechargeRisk2 m4 : 37|1@1+ (1,0) [0|0] "" Vector__XXX
 SG_ VCFRONT_a334_vcleftFastTripOCMax m5 : 37|1@1+ (1,0) [0|0] "" Vector__XXX
 SG_ VCFRONT_a394_pressureSensorCheckFault m6 : 37|1@1+ (1,0) [0|0] "" Vector__XXX
 SG_ VCFRONT_a454_suctionPresSensIntermittent m7 : 37|1@1+ (1,0) [0|0] "" Vector__XXX
 SG_ VCFRONT_a514_LVBMSFault_MOS_Open_cellUV m8 : 37|1@1+ (1,0) [0|0] "" Vector__XXX
 SG_ VCFRONT_a574_frontDriveInverterEFuseTrip m9 : 37|1@1+ (1,0) [0|0] "" Vector__XXX
 SG_ VCFRONT_a634_indeterminateSwitchTransitionDetectedDbg m10 : 37|1@1+ (1,0) [0|0] "" Vector__XXX
 SG_ VCFRONT_a095_CHG_MIA m1 : 38|1@1+ (1,0) [0|0] "" Vector__XXX
 SG_ VCFRONT_a155_prechargeDCRData2 m2 : 38|1@1+ (1,0) [0|0] "" Vector__XXX
 SG_ VCFRONT_a275_TLVBMS_BmbCommunication m4 : 38|1@1+ (1,0) [0|0] "" Vector__XXX
 SG_ VCFRONT_a335_vcrightFastTripOCMax m5 : 38|1@1+ (1,0) [0|0] "" Vector__XXX
 SG_ VCFRONT_a395_pressureSensorCheckInconclusive m6 : 38|1@1+ (1,0) [0|0] "" Vector__XXX
 SG_ VCFRONT_a455_suctionTempSensIntermittent m7 : 38|1@1+ (1,0) [0|0] "" Vector__XXX
 SG_ VCFRONT_a515_LVBMSFault_MOS_Open_cellOV m8 : 38|1@1+ (1,0) [0|0] "" Vector__XXX
 SG_ VCFRONT_a575_frontOilPumpEFuseTrip m9 : 38|1@1+ (1,0) [0|0] "" Vector__XXX
 SG_ VCFRONT_a635_rtosSleepFailed m10 : 38|1@1+ (1,0) [0|0] "" Vector__XXX
 SG_ VCFRONT_a096_OCS1P_MIA m1 : 39|1@1+ (1,0) [0|0] "" Vector__XXX
 SG_ VCFRONT_a156_louverBlockage m2 : 39|1@1+ (1,0) [0|0] "" Vector__XXX
 SG_ VCFRONT_a216_powerCutoffImminent m3 : 39|1@1+ (1,0) [0|0] "" Vector__XXX
 SG_ VCFRONT_a276_TLVBMS_BmbDataIntegrityLoss m4 : 39|1@1+ (1,0) [0|0] "" Vector__XXX
 SG_ VCFRONT_a336_pcsFastTripOCMax m5 : 39|1@1+ (1,0) [0|0] "" Vector__XXX
 SG_ VCFRONT_a396_coolantLevelLowUserFacing m6 : 39|1@1+ (1,0) [0|0] "" Vector__XXX
 SG_ VCFRONT_a456_liquidPresSensIntermittent m7 : 39|1@1+ (1,0) [0|0] "" Vector__XXX
 SG_ VCFRONT_a516_hibernationActive m8 : 39|1@1+ (1,0) [0|0] "" Vector__XXX
 SG_ VCFRONT_a576_mcuLogicEFuseTrip m9 : 39|1@1+ (1,0) [0|0] "" Vector__XXX
 SG_ VCFRONT_d636_ptCoolantPumpDetectsAirInSystem m10 : 39|1@1+ (1,0) [0|0] "" Vector__XXX
 SG_ VCFRONT_a097_CMP_MIA m1 : 40|1@1+ (1,0) [0|0] "" Vector__XXX
 SG_ VCFRONT_a157_louverBreakage m2 : 40|1@1+ (1,0) [0|0] "" Vector__XXX
 SG_ VCFRONT_a277_TLVBMS_BmbStatusRegError m4 : 40|1@1+ (1,0) [0|0] "" Vector__XXX
 SG_ VCFRONT_a337_epas3pFastTripOCMax m5 : 40|1@1+ (1,0) [0|0] "" Vector__XXX
 SG_ VCFRONT_a397_temperatureSensorCheckFault m6 : 40|1@1+ (1,0) [0|0] "" Vector__XXX
 SG_ VCFRONT_a457_liquidTempSensIntermittent m7 : 40|1@1+ (1,0) [0|0] "" Vector__XXX
 SG_ VCFRONT_a517_hibernationRecovery m8 : 40|1@1+ (1,0) [0|0] "" Vector__XXX
 SG_ VCFRONT_a577_tasEFuseTrip m9 : 40|1@1+ (1,0) [0|0] "" Vector__XXX
 SG_ VCFRONT_a697_leftHeadlampNotAimed m11 : 40|1@1+ (1,0) [0|0] "" Vector__XXX
 SG_ VCFRONT_d637_battCoolantPumpDetectsAirInSystem m10 : 40|1@1+ (1,0) [0|0] "" Vector__XXX
 SG_ VCFRONT_a038_ProtFaultInfo m0 : 41|1@1+ (1,0) [0|0] "" Vector__XXX
 SG_ VCFRONT_a098_DIR_MIA m1 : 41|1@1+ (1,0) [0|0] "" Vector__XXX
 SG_ VCFRONT_a158_louverDisconnected m2 : 41|1@1+ (1,0) [0|0] "" Vector__XXX
 SG_ VCFRONT_a218_socMonitorDetectedThresholdSoc m3 : 41|1@1+ (1,0) [0|0] "" Vector__XXX
 SG_ VCFRONT_a278_TLVBMS_BmbHwOverCurrentFault m4 : 41|1@1+ (1,0) [0|0] "" Vector__XXX
 SG_ VCFRONT_a338_epas3sFastTripOCMax m5 : 41|1@1+ (1,0) [0|0] "" Vector__XXX
 SG_ VCFRONT_a398_tempSensorCheckInconclusive m6 : 41|1@1+ (1,0) [0|0] "" Vector__XXX
 SG_ VCFRONT_a458_grosslyLowRefrigerant m7 : 41|1@1+ (1,0) [0|0] "" Vector__XXX
 SG_ VCFRONT_a518_LVBMSFault_MOS_Open_packOV m8 : 41|1@1+ (1,0) [0|0] "" Vector__XXX
 SG_ VCFRONT_a578_vbatFusedLowCurrentFeedEFuseTrip m9 : 41|1@1+ (1,0) [0|0] "" Vector__XXX
 SG_ VCFRONT_a698_rightHeadlampNotAimed m11 : 41|1@1+ (1,0) [0|0] "" Vector__XXX
 SG_ VCFRONT_d638_ptCoolantTempSensorIssue m10 : 41|1@1+ (1,0) [0|0] "" Vector__XXX
 SG_ VCFRONT_a039_ProtFaultAddress m0 : 42|1@1+ (1,0) [0|0] "" Vector__XXX
 SG_ VCFRONT_a099_PARK_MIA m1 : 42|1@1+ (1,0) [0|0] "" Vector__XXX
 SG_ VCFRONT_a159_coolantValveFault m2 : 42|1@1+ (1,0) [0|0] "" Vector__XXX
 SG_ VCFRONT_a219_LVVoltFloorRchd m3 : 42|1@1+ (1,0) [0|0] "" Vector__XXX
 SG_ VCFRONT_a279_refrigLiquidTempSns m4 : 42|1@1+ (1,0) [0|0] "" Vector__XXX
 SG_ VCFRONT_a339_iboosterFastTripOCMax m5 : 42|1@1+ (1,0) [0|0] "" Vector__XXX
 SG_ VCFRONT_a399_frunkNeverReportedOpen m6 : 42|1@1+ (1,0) [0|0] "" Vector__XXX
 SG_ VCFRONT_a459_thermalFillAndDrive m7 : 42|1@1+ (1,0) [0|0] "" Vector__XXX
 SG_ VCFRONT_a579_leftHeadlightEFuseTrip m9 : 42|1@1+ (1,0) [0|0] "" Vector__XXX
 SG_ VCFRONT_d639_batteryCoolantTempSensorIssue m10 : 42|1@1+ (1,0) [0|0] "" Vector__XXX
 SG_ VCFRONT_a040_Backtrace m0 : 43|1@1+ (1,0) [0|0] "" Vector__XXX
 SG_ VCFRONT_a100_CANbus_MIA m1 : 43|1@1+ (1,0) [0|0] "" Vector__XXX
 SG_ VCFRONT_a160_compressorInhibited m2 : 43|1@1+ (1,0) [0|0] "" Vector__XXX
 SG_ VCFRONT_a220_reverseBatteryFault m3 : 43|1@1+ (1,0) [0|0] "" Vector__XXX
 SG_ VCFRONT_a280_refrigLiquidPresSns m4 : 43|1@1+ (1,0) [0|0] "" Vector__XXX
 SG_ VCFRONT_a340_espFastTripOCMax m5 : 43|1@1+ (1,0) [0|0] "" Vector__XXX
 SG_ VCFRONT_a400_TLVBMS_BmbVrefBad m6 : 43|1@1+ (1,0) [0|0] "" Vector__XXX
 SG_ VCFRONT_a460_hardIsentropicTdFailed m7 : 43|1@1+ (1,0) [0|0] "" Vector__XXX
 SG_ VCFRONT_a580_rightHeadlightEFuseTrip m9 : 43|1@1+ (1,0) [0|0] "" Vector__XXX
 SG_ VCFRONT_d640_firmwareConfigMismatch m10 : 43|1@1+ (1,0) [0|0] "" Vector__XXX
 SG_ VCFRONT_a041_HighCPULoad m0 : 44|1@1+ (1,0) [0|0] "" Vector__XXX
 SG_ VCFRONT_a101_PM_MIA m1 : 44|1@1+ (1,0) [0|0] "" Vector__XXX
 SG_ VCFRONT_a161_compressorSelfFault m2 : 44|1@1+ (1,0) [0|0] "" Vector__XXX
 SG_ VCFRONT_a221_leftTurnLightFault m3 : 44|1@1+ (1,0) [0|0] "" Vector__XXX
 SG_ VCFRONT_a281_alcoholInterlockBlockingDrive m4 : 44|1@1+ (1,0) [0|0] "" Vector__XXX
 SG_ VCFRONT_a341_vbatFusedFastTripOCMax m5 : 44|1@1+ (1,0) [0|0] "" Vector__XXX
 SG_ VCFRONT_a401_deadLVMinimalAhDischarged m6 : 44|1@1+ (1,0) [0|0] "" Vector__XXX
 SG_ VCFRONT_a461_TLVBMS_SocHighAhError m7 : 44|1@1+ (1,0) [0|0] "" Vector__XXX
 SG_ VCFRONT_a521_vcleftEFuseLoadShed m8 : 44|1@1+ (1,0) [0|0] "" Vector__XXX
 SG_ VCFRONT_a581_windshieldWiperEFuseTrip m9 : 44|1@1+ (1,0) [0|0] "" Vector__XXX
 SG_ VCFRONT_d641_ptCoolantPumpCircuitOpen m10 : 44|1@1+ (1,0) [0|0] "" Vector__XXX
 SG_ VCFRONT_a042_HighStackUsage m0 : 45|1@1+ (1,0) [0|0] "" Vector__XXX
 SG_ VCFRONT_a102_PTC_MIA m1 : 45|1@1+ (1,0) [0|0] "" Vector__XXX
 SG_ VCFRONT_a162_compressorInhibitedContext m2 : 45|1@1+ (1,0) [0|0] "" Vector__XXX
 SG_ VCFRONT_a222_rightTurnLightFault m3 : 45|1@1+ (1,0) [0|0] "" Vector__XXX
 SG_ VCFRONT_a282_coolantLevelSensorFault m4 : 45|1@1+ (1,0) [0|0] "" Vector__XXX
 SG_ VCFRONT_a342_vcleftFastTripSlope m5 : 45|1@1+ (1,0) [0|0] "" Vector__XXX
 SG_ VCFRONT_a402_LVBatteryCannotSupportVehicle m6 : 45|1@1+ (1,0) [0|0] "" Vector__XXX
 SG_ VCFRONT_a462_LVBMSFault m7 : 45|1@1+ (1,0) [0|0] "" Vector__XXX
 SG_ VCFRONT_a522_hibernationActiveLogCapture m8 : 45|1@1+ (1,0) [0|0] "" Vector__XXX
 SG_ VCFRONT_a582_goodForPCSPowerCycle m9 : 45|1@1+ (1,0) [0|0] "" Vector__XXX
 SG_ VCFRONT_d642_batteryCoolantPumpCircuitOpen m10 : 45|1@1+ (1,0) [0|0] "" Vector__XXX
 SG_ VCFRONT_a043_Task1msError m0 : 46|1@1+ (1,0) [0|0] "" Vector__XXX
 SG_ VCFRONT_a103_CP_MIA m1 : 46|1@1+ (1,0) [0|0] "" Vector__XXX
 SG_ VCFRONT_a163_compressorDisabledFSR m2 : 46|1@1+ (1,0) [0|0] "" Vector__XXX
 SG_ VCFRONT_a223_12VTempSensDiscnect m3 : 46|1@1+ (1,0) [0|0] "" Vector__XXX
 SG_ VCFRONT_a283_thmlFanLimitedByCurrent m4 : 46|1@1+ (1,0) [0|0] "" Vector__XXX
 SG_ VCFRONT_a343_vcrightFastTripSlope m5 : 46|1@1+ (1,0) [0|0] "" Vector__XXX
 SG_ VCFRONT_a403_chargeExitHardCurrentLimit m6 : 46|1@1+ (1,0) [0|0] "" Vector__XXX
 SG_ VCFRONT_a463_frunkSensorService m7 : 46|1@1+ (1,0) [0|0] "" Vector__XXX
 SG_ VCFRONT_a523_eFuseThresholdsIncorrect m8 : 46|1@1+ (1,0) [0|0] "" Vector__XXX
 SG_ VCFRONT_a583_frunkSwitchGroupDisagreementDebug m9 : 46|1@1+ (1,0) [0|0] "" Vector__XXX
 SG_ VCFRONT_a643_rightHeadlampUartCondition m10 : 46|1@1+ (1,0) [0|0] "" Vector__XXX
 SG_ VCFRONT_a044_Task10msError m0 : 47|1@1+ (1,0) [0|0] "" Vector__XXX
 SG_ VCFRONT_a104_DAS_MIA m1 : 47|1@1+ (1,0) [0|0] "" Vector__XXX
 SG_ VCFRONT_a164_eFuseLckoutMissing m2 : 47|1@1+ (1,0) [0|0] "" Vector__XXX
 SG_ VCFRONT_a224_revBatChrgPmpFault m3 : 47|1@1+ (1,0) [0|0] "" Vector__XXX
 SG_ VCFRONT_a284_chillerExvFault m4 : 47|1@1+ (1,0) [0|0] "" Vector__XXX
 SG_ VCFRONT_a344_pcsFastTripSlope m5 : 47|1@1+ (1,0) [0|0] "" Vector__XXX
 SG_ VCFRONT_a404_resistanceEstimationHardFailure m6 : 47|1@1+ (1,0) [0|0] "" Vector__XXX
 SG_ VCFRONT_a464_highFlowIndexHighSubcoolFlagged m7 : 47|1@1+ (1,0) [0|0] "" Vector__XXX
 SG_ VCFRONT_a524_rightHeadlampAimingFault m8 : 47|1@1+ (1,0) [0|0] "" Vector__XXX
 SG_ VCFRONT_a584_frunkSwitchGroupDebug m9 : 47|1@1+ (1,0) [0|0] "" Vector__XXX
 SG_ VCFRONT_a644_washPumpHealthCalculationDbg0 m10 : 47|1@1+ (1,0) [0|0] "" Vector__XXX
 SG_ VCFRONT_a045_Task100msError m0 : 48|1@1+ (1,0) [0|0] "" Vector__XXX
 SG_ VCFRONT_a105_TAS_MIA m1 : 48|1@1+ (1,0) [0|0] "" Vector__XXX
 SG_ VCFRONT_a165_unxpctdEFuseLckout m2 : 48|1@1+ (1,0) [0|0] "" Vector__XXX
 SG_ VCFRONT_a225_driveBlckdByShowroom m3 : 48|1@1+ (1,0) [0|0] "" Vector__XXX
 SG_ VCFRONT_a285_evaporatorExvFault m4 : 48|1@1+ (1,0) [0|0] "" Vector__XXX
 SG_ VCFRONT_a345_epas3pFastTripSlope m5 : 48|1@1+ (1,0) [0|0] "" Vector__XXX
 SG_ VCFRONT_a405_dcrData1 m6 : 48|1@1+ (1,0) [0|0] "" Vector__XXX
 SG_ VCFRONT_a465_lowFlowIndexHighSubcoolFlagged m7 : 48|1@1+ (1,0) [0|0] "" Vector__XXX
 SG_ VCFRONT_a525_LVBatterySWMisconfiguration m8 : 48|1@1+ (1,0) [0|0] "" Vector__XXX
 SG_ VCFRONT_a585_bothHeadlampsInternalError m9 : 48|1@1+ (1,0) [0|0] "" Vector__XXX
 SG_ VCFRONT_a645_washPumpHealthCalculationDbg1 m10 : 48|1@1+ (1,0) [0|0] "" Vector__XXX
 SG_ VCFRONT_a046_Task1000msError m0 : 49|1@1+ (1,0) [0|0] "" Vector__XXX
 SG_ VCFRONT_a106_PCS_MIA m1 : 49|1@1+ (1,0) [0|0] "" Vector__XXX
 SG_ VCFRONT_a166_rightHCMMIA m2 : 49|1@1+ (1,0) [0|0] "" Vector__XXX
 SG_ VCFRONT_a286_recircExvFault m4 : 49|1@1+ (1,0) [0|0] "" Vector__XXX
 SG_ VCFRONT_a346_epas3sFastTripSlope m5 : 49|1@1+ (1,0) [0|0] "" Vector__XXX
 SG_ VCFRONT_a406_dcrData2 m6 : 49|1@1+ (1,0) [0|0] "" Vector__XXX
 SG_ VCFRONT_a466_highFlowIndexLowSubcoolFlagged m7 : 49|1@1+ (1,0) [0|0] "" Vector__XXX
 SG_ VCFRONT_a586_rightLowOrHighBeamLightCondition m9 : 49|1@1+ (1,0) [0|0] "" Vector__XXX
 SG_ VCFRONT_a646_washPumpHealthCalculationDbg2 m10 : 49|1@1+ (1,0) [0|0] "" Vector__XXX
 SG_ VCFRONT_a047_resetReason m0 : 50|1@1+ (1,0) [0|0] "" Vector__XXX
 SG_ VCFRONT_a107_BMS_MIA m1 : 50|1@1+ (1,0) [0|0] "" Vector__XXX
 SG_ VCFRONT_a167_leftHCMMIA m2 : 50|1@1+ (1,0) [0|0] "" Vector__XXX
 SG_ VCFRONT_a287_lccExvFault m4 : 50|1@1+ (1,0) [0|0] "" Vector__XXX
 SG_ VCFRONT_a347_iboosterFastTripSlope m5 : 50|1@1+ (1,0) [0|0] "" Vector__XXX
 SG_ VCFRONT_a407_dcrMilliOhmsAboveThreshold m6 : 50|1@1+ (1,0) [0|0] "" Vector__XXX
 SG_ VCFRONT_a467_lowPowerIndexFlagged m7 : 50|1@1+ (1,0) [0|0] "" Vector__XXX
 SG_ VCFRONT_a527_LVBatteryCellImbalance m8 : 50|1@1+ (1,0) [0|0] "" Vector__XXX
 SG_ VCFRONT_a587_externalLVPowerSupply m9 : 50|1@1+ (1,0) [0|0] "" Vector__XXX
 SG_ VCFRONT_d647_louverCommLost m10 : 50|1@1+ (1,0) [0|0] "" Vector__XXX
 SG_ VCFRONT_a108_DIF_MIA m1 : 51|1@1+ (1,0) [0|0] "" Vector__XXX
 SG_ VCFRONT_a168_hcmShortToVBAT m2 : 51|1@1+ (1,0) [0|0] "" Vector__XXX
 SG_ VCFRONT_a228_pumpBatFbkSanity m3 : 51|1@1+ (1,0) [0|0] "" Vector__XXX
 SG_ VCFRONT_a288_ccLeftExvFault m4 : 51|1@1+ (1,0) [0|0] "" Vector__XXX
 SG_ VCFRONT_a348_espFastTripSlope m5 : 51|1@1+ (1,0) [0|0] "" Vector__XXX
 SG_ VCFRONT_a408_standbyChargeProfileHardExit m6 : 51|1@1+ (1,0) [0|0] "" Vector__XXX
 SG_ VCFRONT_a468_highPowerIndexFlagged m7 : 51|1@1+ (1,0) [0|0] "" Vector__XXX
 SG_ VCFRONT_a528_LVBatteryCommsDiscnctd m8 : 51|1@1+ (1,0) [0|0] "" Vector__XXX
 SG_ VCFRONT_a588_vcleftPwrRationalityCurve m9 : 51|1@1+ (1,0) [0|0] "" Vector__XXX
 SG_ VCFRONT_d648_louverBlocked m10 : 51|1@1+ (1,0) [0|0] "" Vector__XXX
 SG_ VCFRONT_a109_RCM_MIA m1 : 52|1@1+ (1,0) [0|0] "" Vector__XXX
 SG_ VCFRONT_a169_hcmPhaseEnableFail m2 : 52|1@1+ (1,0) [0|0] "" Vector__XXX
 SG_ VCFRONT_a229_pumpPtFbkSanity m3 : 52|1@1+ (1,0) [0|0] "" Vector__XXX
 SG_ VCFRONT_a289_ccRightExvFault m4 : 52|1@1+ (1,0) [0|0] "" Vector__XXX
 SG_ VCFRONT_a349_vbatFusedFastTripSlope m5 : 52|1@1+ (1,0) [0|0] "" Vector__XXX
 SG_ VCFRONT_a409_invalidConfiguration m6 : 52|1@1+ (1,0) [0|0] "" Vector__XXX
 SG_ VCFRONT_a469_prvPopDetected m7 : 52|1@1+ (1,0) [0|0] "" Vector__XXX
 SG_ VCFRONT_a529_discnctdBatteryStateUnknown m8 : 52|1@1+ (1,0) [0|0] "" Vector__XXX
 SG_ VCFRONT_a589_vcleftFastBlowDetection m9 : 52|1@1+ (1,0) [0|0] "" Vector__XXX
 SG_ VCFRONT_a649_persistAccPortPowerReqOverridden m10 : 52|1@1+ (1,0) [0|0] "" Vector__XXX
 SG_ VCFRONT_a110_GTW_MIA m1 : 53|1@1+ (1,0) [0|0] "" Vector__XXX
 SG_ VCFRONT_a170_hcmUnderVoltage m2 : 53|1@1+ (1,0) [0|0] "" Vector__XXX
 SG_ VCFRONT_a230_thmlFanFbkSanity m3 : 53|1@1+ (1,0) [0|0] "" Vector__XXX
 SG_ VCFRONT_a290_leftFogLightFault m4 : 53|1@1+ (1,0) [0|0] "" Vector__XXX
 SG_ VCFRONT_a350_espValveCurrentSenseSaturated m5 : 53|1@1+ (1,0) [0|0] "" Vector__XXX
 SG_ VCFRONT_a410_LVBatteryDataCollection1 m6 : 53|1@1+ (1,0) [0|0] "" Vector__XXX
 SG_ VCFRONT_a470_implausiblePdPlDetected m7 : 53|1@1+ (1,0) [0|0] "" Vector__XXX
 SG_ VCFRONT_a530_sharpCurrentRise m8 : 53|1@1+ (1,0) [0|0] "" Vector__XXX
 SG_ VCFRONT_a590_vcrightPwrRationalityCurve m9 : 53|1@1+ (1,0) [0|0] "" Vector__XXX
 SG_ VCFRONT_d650_lowCoolantLevel m10 : 53|1@1+ (1,0) [0|0] "" Vector__XXX
 SG_ VCFRONT_a111_EPBR_MIA m1 : 54|1@1+ (1,0) [0|0] "" Vector__XXX
 SG_ VCFRONT_a171_driveBlckdByMsmtch m2 : 54|1@1+ (1,0) [0|0] "" Vector__XXX
 SG_ VCFRONT_a231_12VTempSensShort m3 : 54|1@1+ (1,0) [0|0] "" Vector__XXX
 SG_ VCFRONT_a291_rightFogLightFault m4 : 54|1@1+ (1,0) [0|0] "" Vector__XXX
 SG_ VCFRONT_a351_emergencyFrunkButtonPressIgnored m5 : 54|1@1+ (1,0) [0|0] "" Vector__XXX
 SG_ VCFRONT_a411_LVBatteryDataCollection2 m6 : 54|1@1+ (1,0) [0|0] "" Vector__XXX
 SG_ VCFRONT_a531_lowPowerIndexFlaggedUserFacing m8 : 54|1@1+ (1,0) [0|0] "" Vector__XXX
 SG_ VCFRONT_a591_vcrightFastBlowDetection m9 : 54|1@1+ (1,0) [0|0] "" Vector__XXX
 SG_ VCFRONT_d651_ptCoolantPumpStall m10 : 54|1@1+ (1,0) [0|0] "" Vector__XXX
 SG_ VCFRONT_a112_EPBL_MIA m1 : 55|1@1+ (1,0) [0|0] "" Vector__XXX
 SG_ VCFRONT_a172_wsteHtBlckdByMsmtch m2 : 55|1@1+ (1,0) [0|0] "" Vector__XXX
 SG_ VCFRONT_a232_lowSideControllerHighFdbk m3 : 55|1@1+ (1,0) [0|0] "" Vector__XXX
 SG_ VCFRONT_a292_sideMarkerLightPipeFault m4 : 55|1@1+ (1,0) [0|0] "" Vector__XXX
 SG_ VCFRONT_a352_audioCurrentSpikeData m5 : 55|1@1+ (1,0) [0|0] "" Vector__XXX
 SG_ VCFRONT_a412_dcrData3 m6 : 55|1@1+ (1,0) [0|0] "" Vector__XXX
 SG_ VCFRONT_a472_leftHeadlampRangeUpdate m7 : 55|1@1+ (1,0) [0|0] "" Vector__XXX
 SG_ VCFRONT_a532_gtwMIAInDrive m8 : 55|1@1+ (1,0) [0|0] "" Vector__XXX
 SG_ VCFRONT_a592_vcleftCurvePowerCutoff m9 : 55|1@1+ (1,0) [0|0] "" Vector__XXX
 SG_ VCFRONT_d652_ptCoolantPumpCircuitIssue m10 : 55|1@1+ (1,0) [0|0] "" Vector__XXX
 SG_ VCFRONT_a053_wiperCommErrorUser m0 : 56|1@1+ (1,0) [0|0] "" Vector__XXX
 SG_ VCFRONT_a113_UI_MIA m1 : 56|1@1+ (1,0) [0|0] "" Vector__XXX
 SG_ VCFRONT_a173_HVBlckdByMsmtch m2 : 56|1@1+ (1,0) [0|0] "" Vector__XXX
 SG_ VCFRONT_a233_autopilot1EFuseFault m3 : 56|1@1+ (1,0) [0|0] "" Vector__XXX
 SG_ VCFRONT_a293_interiorFrunkLightFault m4 : 56|1@1+ (1,0) [0|0] "" Vector__XXX
 SG_ VCFRONT_a353_wiperHeaterUndercurrent m5 : 56|1@1+ (1,0) [0|0] "" Vector__XXX
 SG_ VCFRONT_a413_TLVBMS_BmbVrefWarning m6 : 56|1@1+ (1,0) [0|0] "" Vector__XXX
 SG_ VCFRONT_a473_rightHeadlampRangeUpdate m7 : 56|1@1+ (1,0) [0|0] "" Vector__XXX
 SG_ VCFRONT_a533_TLVBMS_MosfetOverTemperatureFault m8 : 56|1@1+ (1,0) [0|0] "" Vector__XXX
 SG_ VCFRONT_a593_vcleftFastBlowPowerCutoff m9 : 56|1@1+ (1,0) [0|0] "" Vector__XXX
 SG_ VCFRONT_d653_ptCoolantPumpCommLost m10 : 56|1@1+ (1,0) [0|0] "" Vector__XXX
 SG_ VCFRONT_a054_compressorLowFlowUserFacing m0 : 57|1@1+ (1,0) [0|0] "" Vector__XXX
 SG_ VCFRONT_a114_ESP_MIA m1 : 57|1@1+ (1,0) [0|0] "" Vector__XXX
 SG_ VCFRONT_a174_driveNotAuthed m2 : 57|1@1+ (1,0) [0|0] "" Vector__XXX
 SG_ VCFRONT_a234_autopilot2EFuseFault m3 : 57|1@1+ (1,0) [0|0] "" Vector__XXX
 SG_ VCFRONT_a294_leftSideRepeaterLightFault m4 : 57|1@1+ (1,0) [0|0] "" Vector__XXX
 SG_ VCFRONT_a354_windshieldCameraHeaterUndercurrent m5 : 57|1@1+ (1,0) [0|0] "" Vector__XXX
 SG_ VCFRONT_a414_prechargeLVLoadReduction m6 : 57|1@1+ (1,0) [0|0] "" Vector__XXX
 SG_ VCFRONT_a474_leftHeadlampInternalError m7 : 57|1@1+ (1,0) [0|0] "" Vector__XXX
 SG_ VCFRONT_a534_chillerExvCalibInitDebug m8 : 57|1@1+ (1,0) [0|0] "" Vector__XXX
 SG_ VCFRONT_a594_virtualPitchConversionDebug m9 : 57|1@1+ (1,0) [0|0] "" Vector__XXX
 SG_ VCFRONT_d654_batteryCoolantPumpStall m10 : 57|1@1+ (1,0) [0|0] "" Vector__XXX
 SG_ VCFRONT_a115_VCSEC_MIA m1 : 58|1@1+ (1,0) [0|0] "" Vector__XXX
 SG_ VCFRONT_a175_ambientTempSns m2 : 58|1@1+ (1,0) [0|0] "" Vector__XXX
 SG_ VCFRONT_a235_ptTempSnsIrrational m3 : 58|1@1+ (1,0) [0|0] "" Vector__XXX
 SG_ VCFRONT_a295_rightSideRepeaterLightFault m4 : 58|1@1+ (1,0) [0|0] "" Vector__XXX
 SG_ VCFRONT_a355_coolantSysLockout m5 : 58|1@1+ (1,0) [0|0] "" Vector__XXX
 SG_ VCFRONT_a415_prechargeLVLoadReduction2 m6 : 58|1@1+ (1,0) [0|0] "" Vector__XXX
 SG_ VCFRONT_a475_rightHeadlampInternalError m7 : 58|1@1+ (1,0) [0|0] "" Vector__XXX
 SG_ VCFRONT_a535_evapExvCalibInitDebug m8 : 58|1@1+ (1,0) [0|0] "" Vector__XXX
 SG_ VCFRONT_a595_voltageSensorMismatch m9 : 58|1@1+ (1,0) [0|0] "" Vector__XXX
 SG_ VCFRONT_d655_batteryCoolantPumpCircuitIssue m10 : 58|1@1+ (1,0) [0|0] "" Vector__XXX
 SG_ VCFRONT_a116_VCRIGHT_MIA m1 : 59|1@1+ (1,0) [0|0] "" Vector__XXX
 SG_ VCFRONT_a176_vehicleInSelfTest m2 : 59|1@1+ (1,0) [0|0] "" Vector__XXX
 SG_ VCFRONT_a236_batTempSnsIrrational m3 : 59|1@1+ (1,0) [0|0] "" Vector__XXX
 SG_ VCFRONT_a296_turnSignalIssue m4 : 59|1@1+ (1,0) [0|0] "" Vector__XXX
 SG_ VCFRONT_a356_refrigSysLockout m5 : 59|1@1+ (1,0) [0|0] "" Vector__XXX
 SG_ VCFRONT_a416_TLVBMS_BrickOverDischarged m6 : 59|1@1+ (1,0) [0|0] "" Vector__XXX
 SG_ VCFRONT_a476_LVBMSMIA m7 : 59|1@1+ (1,0) [0|0] "" Vector__XXX
 SG_ VCFRONT_a536_recircExvCalibInitDebug m8 : 59|1@1+ (1,0) [0|0] "" Vector__XXX
 SG_ VCFRONT_a596_vcrightCurvePowerCutoff m9 : 59|1@1+ (1,0) [0|0] "" Vector__XXX
 SG_ VCFRONT_d656_batteryCoolantPumpCommLost m10 : 59|1@1+ (1,0) [0|0] "" Vector__XXX
 SG_ VCFRONT_a057_HVP_MIA m0 : 60|1@1+ (1,0) [0|0] "" Vector__XXX
 SG_ VCFRONT_a117_VCLEFT_MIA m1 : 60|1@1+ (1,0) [0|0] "" Vector__XXX
 SG_ VCFRONT_a177_mcuAudioEFuseFault m2 : 60|1@1+ (1,0) [0|0] "" Vector__XXX
 SG_ VCFRONT_a237_pumpBatChipComms m3 : 60|1@1+ (1,0) [0|0] "" Vector__XXX
 SG_ VCFRONT_a297_TLVBMS_BmbHwOverTemperatureFault m4 : 60|1@1+ (1,0) [0|0] "" Vector__XXX
 SG_ VCFRONT_a357_hornUndercurrent m5 : 60|1@1+ (1,0) [0|0] "" Vector__XXX
 SG_ VCFRONT_a417_TLVBMS_BrickOverVoltageFault m6 : 60|1@1+ (1,0) [0|0] "" Vector__XXX
 SG_ VCFRONT_a477_LVBatteryUnrecoverableByVehicle m7 : 60|1@1+ (1,0) [0|0] "" Vector__XXX
 SG_ VCFRONT_a537_lccExvCalibInitDebug m8 : 60|1@1+ (1,0) [0|0] "" Vector__XXX
 SG_ VCFRONT_a597_vcrightFastBlowPowerCutoff m9 : 60|1@1+ (1,0) [0|0] "" Vector__XXX
 SG_ VCFRONT_d657_radiatorFanOperationIssue m10 : 60|1@1+ (1,0) [0|0] "" Vector__XXX
 SG_ VCFRONT_a058_inputRHighSyncDebug m0 : 61|1@1+ (1,0) [0|0] "" Vector__XXX
 SG_ VCFRONT_a118_VCFRONT_MIA m1 : 61|1@1+ (1,0) [0|0] "" Vector__XXX
 SG_ VCFRONT_a178_compLiquidPumpOut m2 : 61|1@1+ (1,0) [0|0] "" Vector__XXX
 SG_ VCFRONT_a238_pumpPtChipComms m3 : 61|1@1+ (1,0) [0|0] "" Vector__XXX
 SG_ VCFRONT_a298_radiatorLowAirFlowDetected m4 : 61|1@1+ (1,0) [0|0] "" Vector__XXX
 SG_ VCFRONT_a358_hornOvercurrent m5 : 61|1@1+ (1,0) [0|0] "" Vector__XXX
 SG_ VCFRONT_a418_TLVBMS_BrickOverVoltageWarning m6 : 61|1@1+ (1,0) [0|0] "" Vector__XXX
 SG_ VCFRONT_a478_LVBMS_MOSFET_Open m7 : 61|1@1+ (1,0) [0|0] "" Vector__XXX
 SG_ VCFRONT_a538_cclExvCalibInitDebug m8 : 61|1@1+ (1,0) [0|0] "" Vector__XXX
 SG_ VCFRONT_a598_eFuseSelfTestFailureService m9 : 61|1@1+ (1,0) [0|0] "" Vector__XXX
 SG_ VCFRONT_d658_radiatorFanCircuitIssue m10 : 61|1@1+ (1,0) [0|0] "" Vector__XXX
 SG_ VCFRONT_a059_inputResistanceHigh m0 : 62|1@1+ (1,0) [0|0] "" Vector__XXX
 SG_ VCFRONT_a119_SCCM_MIA m1 : 62|1@1+ (1,0) [0|0] "" Vector__XXX
 SG_ VCFRONT_a179_highLVAmpsIntoPCS m2 : 62|1@1+ (1,0) [0|0] "" Vector__XXX
 SG_ VCFRONT_a239_thmlFanChipComms m3 : 62|1@1+ (1,0) [0|0] "" Vector__XXX
 SG_ VCFRONT_a299_homelinkConfigurationFailed m4 : 62|1@1+ (1,0) [0|0] "" Vector__XXX
 SG_ VCFRONT_a359_postPORExcessiveAh m5 : 62|1@1+ (1,0) [0|0] "" Vector__XXX
 SG_ VCFRONT_a419_TLVBMS_BrickSocLow m6 : 62|1@1+ (1,0) [0|0] "" Vector__XXX
 SG_ VCFRONT_a479_LVBMS_ECPA_NotClosed m7 : 62|1@1+ (1,0) [0|0] "" Vector__XXX
 SG_ VCFRONT_a539_ccrExvCalibInitDebug m8 : 62|1@1+ (1,0) [0|0] "" Vector__XXX
 SG_ VCFRONT_a599_LVBatteryTypeUnsupported m9 : 62|1@1+ (1,0) [0|0] "" Vector__XXX
 SG_ VCFRONT_d659_radiatorFanCommLost m10 : 62|1@1+ (1,0) [0|0] "" Vector__XXX
 SG_ VCFRONT_a060_engineeringBuild m0 : 63|1@1+ (1,0) [0|0] "" Vector__XXX
 SG_ VCFRONT_a120_DI_DRIVE_MIA m1 : 63|1@1+ (1,0) [0|0] "" Vector__XXX
 SG_ VCFRONT_a180_DCDCNotSupportingLVBus m2 : 63|1@1+ (1,0) [0|0] "" Vector__XXX
 SG_ VCFRONT_a240_lowSideCompromised m3 : 63|1@1+ (1,0) [0|0] "" Vector__XXX
 SG_ VCFRONT_a300_louverActuatorSwapDetected m4 : 63|1@1+ (1,0) [0|0] "" Vector__XXX
 SG_ VCFRONT_a360_ungracefulAccPlusExit m5 : 63|1@1+ (1,0) [0|0] "" Vector__XXX
 SG_ VCFRONT_a420_holidayParty m6 : 63|1@1+ (1,0) [0|0] "" Vector__XXX
 SG_ VCFRONT_a480_vnf1048Fault m7 : 63|1@1+ (1,0) [0|0] "" Vector__XXX
 SG_ VCFRONT_a540_radiatorSteamDetected m8 : 63|1@1+ (1,0) [0|0] "" Vector__XXX
 SG_ VCFRONT_a600_currentSensorMismatch m9 : 63|1@1+ (1,0) [0|0] "" Vector__XXX
 SG_ VCFRONT_d660_coolantValveCircuitIssue m10 : 63|1@1+ (1,0) [0|0] "" Vector__XXX
